VERSION "dbc-export 1 2026.26.6.5"

NS_ :

BS_:

BU_: BB DAS DI DIF DIR EPAS3P EPASTP ESP IBST PM PMF PMR RCM VCBATT0 VCCC VCFRONT VCLEFT VCRIGHT

BO_ 1427 EPASTP_alertLog: 8 EPASTP
 SG_ EPASTP_alertID M : 0|9@1+ (1,0) [0|511] "" Vector__XXX
 SG_ EPASTP_alertState : 15|1@1+ (1,0) [0|1] "" Vector__XXX
 SG_ EPASTP_a001_debugInfo m1 : 16|48@1+ (1,0) [0|281474976710655] "" Vector__XXX
 SG_ EPASTP_a002_debugInfo m2 : 16|48@1+ (1,0) [0|281474976710655] "" Vector__XXX
 SG_ EPASTP_a003_debugInfo m3 : 16|48@1+ (1,0) [0|281474976710655] "" Vector__XXX
 SG_ EPASTP_a004_debugInfo m4 : 16|48@1+ (1,0) [0|281474976710655] "" Vector__XXX
 SG_ EPASTP_a005_debugInfo m5 : 16|48@1+ (1,0) [0|281474976710655] "" Vector__XXX
 SG_ EPASTP_a006_debugInfo m6 : 16|48@1+ (1,0) [0|281474976710655] "" Vector__XXX
 SG_ EPASTP_a007_debugInfo m7 : 16|48@1+ (1,0) [0|281474976710655] "" Vector__XXX
 SG_ EPASTP_a009_debugInfo m9 : 16|48@1+ (1,0) [0|281474976710655] "" Vector__XXX
 SG_ EPASTP_a010_debugInfo m10 : 16|48@1+ (1,0) [0|281474976710655] "" Vector__XXX
 SG_ EPASTP_a011_debugInfo m11 : 16|48@1+ (1,0) [0|281474976710655] "" Vector__XXX
 SG_ EPASTP_a012_debugInfo m12 : 16|48@1+ (1,0) [0|281474976710655] "" Vector__XXX
 SG_ EPASTP_a013_debugInfo m13 : 16|48@1+ (1,0) [0|281474976710655] "" Vector__XXX
 SG_ EPASTP_a014_debugInfo m14 : 16|48@1+ (1,0) [0|281474976710655] "" Vector__XXX
 SG_ EPASTP_a015_debugInfo m15 : 16|48@1+ (1,0) [0|281474976710655] "" Vector__XXX
 SG_ EPASTP_a016_debugInfo m16 : 16|48@1+ (1,0) [0|281474976710655] "" Vector__XXX
 SG_ EPASTP_a017_debugInfo m17 : 16|48@1+ (1,0) [0|281474976710655] "" Vector__XXX
 SG_ EPASTP_a018_debugInfo m18 : 16|48@1+ (1,0) [0|281474976710655] "" Vector__XXX
 SG_ EPASTP_a019_debugInfo m19 : 16|48@1+ (1,0) [0|281474976710655] "" Vector__XXX
 SG_ EPASTP_a020_debugInfo m20 : 16|48@1+ (1,0) [0|281474976710655] "" Vector__XXX
 SG_ EPASTP_a021_debugInfo m21 : 16|48@1+ (1,0) [0|281474976710655] "" Vector__XXX
 SG_ EPASTP_a022_debugInfo m22 : 16|48@1+ (1,0) [0|281474976710655] "" Vector__XXX
 SG_ EPASTP_a023_debugInfo m23 : 16|48@1+ (1,0) [0|281474976710655] "" Vector__XXX
 SG_ EPASTP_a024_debugInfo m24 : 16|48@1+ (1,0) [0|281474976710655] "" Vector__XXX
 SG_ EPASTP_a025_debugInfo m25 : 16|48@1+ (1,0) [0|281474976710655] "" Vector__XXX
 SG_ EPASTP_a026_debugInfo m26 : 16|48@1+ (1,0) [0|281474976710655] "" Vector__XXX
 SG_ EPASTP_a027_debugInfo m27 : 16|48@1+ (1,0) [0|281474976710655] "" Vector__XXX
 SG_ EPASTP_a028_debugInfo m28 : 16|48@1+ (1,0) [0|281474976710655] "" Vector__XXX
 SG_ EPASTP_a029_debugInfo m29 : 16|48@1+ (1,0) [0|281474976710655] "" Vector__XXX
 SG_ EPASTP_a030_debugInfo m30 : 16|48@1+ (1,0) [0|281474976710655] "" Vector__XXX
 SG_ EPASTP_a031_debugInfo m31 : 16|48@1+ (1,0) [0|281474976710655] "" Vector__XXX
 SG_ EPASTP_a032_debugInfo m32 : 16|48@1+ (1,0) [0|281474976710655] "" Vector__XXX
 SG_ EPASTP_a033_debugInfo m33 : 16|48@1+ (1,0) [0|281474976710655] "" Vector__XXX
 SG_ EPASTP_a034_debugInfo m34 : 16|48@1+ (1,0) [0|281474976710655] "" Vector__XXX
 SG_ EPASTP_a035_debugInfo m35 : 16|48@1+ (1,0) [0|281474976710655] "" Vector__XXX
 SG_ EPASTP_a036_debugInfo m36 : 16|48@1+ (1,0) [0|281474976710655] "" Vector__XXX
 SG_ EPASTP_a037_debugInfo m37 : 16|48@1+ (1,0) [0|281474976710655] "" Vector__XXX
 SG_ EPASTP_a038_debugInfo m38 : 16|48@1+ (1,0) [0|281474976710655] "" Vector__XXX
 SG_ EPASTP_a039_debugInfo m39 : 16|48@1+ (1,0) [0|281474976710655] "" Vector__XXX
 SG_ EPASTP_a040_debugInfo m40 : 16|48@1+ (1,0) [0|281474976710655] "" Vector__XXX
 SG_ EPASTP_a041_debugInfo m41 : 16|48@1+ (1,0) [0|281474976710655] "" Vector__XXX
 SG_ EPASTP_a042_debugInfo m42 : 16|48@1+ (1,0) [0|281474976710655] "" Vector__XXX
 SG_ EPASTP_a043_debugInfo m43 : 16|48@1+ (1,0) [0|281474976710655] "" Vector__XXX
 SG_ EPASTP_a044_debugInfo m44 : 16|48@1+ (1,0) [0|281474976710655] "" Vector__XXX
 SG_ EPASTP_a045_debugInfo m45 : 16|48@1+ (1,0) [0|281474976710655] "" Vector__XXX
 SG_ EPASTP_a046_debugInfo m46 : 16|48@1+ (1,0) [0|281474976710655] "" Vector__XXX
 SG_ EPASTP_a047_debugInfo m47 : 16|48@1+ (1,0) [0|281474976710655] "" Vector__XXX
 SG_ EPASTP_a048_debugInfo m48 : 16|48@1+ (1,0) [0|281474976710655] "" Vector__XXX
 SG_ EPASTP_a049_debugInfo m49 : 16|48@1+ (1,0) [0|281474976710655] "" Vector__XXX
 SG_ EPASTP_a050_debugInfo m50 : 16|48@1+ (1,0) [0|281474976710655] "" Vector__XXX
 SG_ EPASTP_a051_debugInfo m51 : 16|48@1+ (1,0) [0|281474976710655] "" Vector__XXX
 SG_ EPASTP_a052_debugInfo m52 : 16|48@1+ (1,0) [0|281474976710655] "" Vector__XXX
 SG_ EPASTP_a053_debugInfo m53 : 16|48@1+ (1,0) [0|281474976710655] "" Vector__XXX
 SG_ EPASTP_a054_debugInfo m54 : 16|48@1+ (1,0) [0|281474976710655] "" Vector__XXX
 SG_ EPASTP_a055_debugInfo m55 : 16|48@1+ (1,0) [0|281474976710655] "" Vector__XXX
 SG_ EPASTP_a056_debugInfo m56 : 16|48@1+ (1,0) [0|281474976710655] "" Vector__XXX
 SG_ EPASTP_a057_debugInfo m57 : 16|48@1+ (1,0) [0|281474976710655] "" Vector__XXX
 SG_ EPASTP_a058_debugInfo m58 : 16|48@1+ (1,0) [0|281474976710655] "" Vector__XXX
 SG_ EPASTP_a059_debugInfo m59 : 16|48@1+ (1,0) [0|281474976710655] "" Vector__XXX
 SG_ EPASTP_a060_debugInfo m60 : 16|48@1+ (1,0) [0|281474976710655] "" Vector__XXX
 SG_ EPASTP_a061_debugInfo m61 : 16|48@1+ (1,0) [0|281474976710655] "" Vector__XXX
 SG_ EPASTP_a062_debugInfo m62 : 16|48@1+ (1,0) [0|281474976710655] "" Vector__XXX
 SG_ EPASTP_a063_debugInfo m63 : 16|48@1+ (1,0) [0|281474976710655] "" Vector__XXX
 SG_ EPASTP_a064_debugInfo m64 : 16|48@1+ (1,0) [0|281474976710655] "" Vector__XXX
 SG_ EPASTP_a065_debugInfo m65 : 16|48@1+ (1,0) [0|281474976710655] "" Vector__XXX
 SG_ EPASTP_a066_debugInfo m66 : 16|48@1+ (1,0) [0|281474976710655] "" Vector__XXX
 SG_ EPASTP_a067_debugInfo m67 : 16|48@1+ (1,0) [0|281474976710655] "" Vector__XXX
 SG_ EPASTP_a068_debugInfo m68 : 16|48@1+ (1,0) [0|281474976710655] "" Vector__XXX
 SG_ EPASTP_a069_debugInfo m69 : 16|48@1+ (1,0) [0|281474976710655] "" Vector__XXX
 SG_ EPASTP_a070_debugInfo m70 : 16|48@1+ (1,0) [0|281474976710655] "" Vector__XXX
 SG_ EPASTP_a071_debugInfo m71 : 16|48@1+ (1,0) [0|281474976710655] "" Vector__XXX
 SG_ EPASTP_a072_debugInfo m72 : 16|48@1+ (1,0) [0|281474976710655] "" Vector__XXX
 SG_ EPASTP_a073_debugInfo m73 : 16|48@1+ (1,0) [0|281474976710655] "" Vector__XXX
 SG_ EPASTP_a074_debugInfo m74 : 16|48@1+ (1,0) [0|281474976710655] "" Vector__XXX
 SG_ EPASTP_a075_debugInfo m75 : 16|48@1+ (1,0) [0|281474976710655] "" Vector__XXX
 SG_ EPASTP_a076_debugInfo m76 : 16|48@1+ (1,0) [0|281474976710655] "" Vector__XXX
 SG_ EPASTP_a077_debugInfo m77 : 16|48@1+ (1,0) [0|281474976710655] "" Vector__XXX
 SG_ EPASTP_a078_debugInfo m78 : 16|48@1+ (1,0) [0|281474976710655] "" Vector__XXX
 SG_ EPASTP_a079_debugInfo m79 : 16|48@1+ (1,0) [0|281474976710655] "" Vector__XXX
 SG_ EPASTP_a080_debugInfo m80 : 16|48@1+ (1,0) [0|281474976710655] "" Vector__XXX
 SG_ EPASTP_a081_debugInfo m81 : 16|48@1+ (1,0) [0|281474976710655] "" Vector__XXX
 SG_ EPASTP_a082_debugInfo m82 : 16|48@1+ (1,0) [0|281474976710655] "" Vector__XXX
 SG_ EPASTP_a083_debugInfo m83 : 16|48@1+ (1,0) [0|281474976710655] "" Vector__XXX
 SG_ EPASTP_a084_debugInfo m84 : 16|48@1+ (1,0) [0|281474976710655] "" Vector__XXX
 SG_ EPASTP_a085_debugInfo m85 : 16|48@1+ (1,0) [0|281474976710655] "" Vector__XXX
 SG_ EPASTP_a086_debugInfo m86 : 16|48@1+ (1,0) [0|281474976710655] "" Vector__XXX
 SG_ EPASTP_a087_debugInfo m87 : 16|48@1+ (1,0) [0|281474976710655] "" Vector__XXX
 SG_ EPASTP_a088_debugInfo m88 : 16|48@1+ (1,0) [0|281474976710655] "" Vector__XXX
 SG_ EPASTP_a089_debugInfo m89 : 16|48@1+ (1,0) [0|281474976710655] "" Vector__XXX
 SG_ EPASTP_a090_debugInfo m90 : 16|48@1+ (1,0) [0|281474976710655] "" Vector__XXX
 SG_ EPASTP_a091_debugInfo m91 : 16|48@1+ (1,0) [0|281474976710655] "" Vector__XXX
 SG_ EPASTP_a092_debugInfo m92 : 16|48@1+ (1,0) [0|281474976710655] "" Vector__XXX
 SG_ EPASTP_a093_debugInfo m93 : 16|48@1+ (1,0) [0|281474976710655] "" Vector__XXX
 SG_ EPASTP_a094_debugInfo m94 : 16|48@1+ (1,0) [0|281474976710655] "" Vector__XXX
 SG_ EPASTP_a095_debugInfo m95 : 16|48@1+ (1,0) [0|281474976710655] "" Vector__XXX
 SG_ EPASTP_a096_debugInfo m96 : 16|48@1+ (1,0) [0|281474976710655] "" Vector__XXX
 SG_ EPASTP_a097_debugInfo m97 : 16|48@1+ (1,0) [0|281474976710655] "" Vector__XXX
 SG_ EPASTP_a098_debugInfo m98 : 16|48@1+ (1,0) [0|281474976710655] "" Vector__XXX
 SG_ EPASTP_a099_debugInfo m99 : 16|48@1+ (1,0) [0|281474976710655] "" Vector__XXX
 SG_ EPASTP_a100_debugInfo m100 : 16|48@1+ (1,0) [0|281474976710655] "" Vector__XXX
 SG_ EPASTP_a101_debugInfo m101 : 16|48@1+ (1,0) [0|281474976710655] "" Vector__XXX
 SG_ EPASTP_a102_debugInfo m102 : 16|48@1+ (1,0) [0|281474976710655] "" Vector__XXX
 SG_ EPASTP_a103_debugInfo m103 : 16|48@1+ (1,0) [0|281474976710655] "" Vector__XXX
 SG_ EPASTP_a104_debugInfo m104 : 16|48@1+ (1,0) [0|281474976710655] "" Vector__XXX
 SG_ EPASTP_a105_debugInfo m105 : 16|48@1+ (1,0) [0|281474976710655] "" Vector__XXX
 SG_ EPASTP_a106_debugInfo m106 : 16|48@1+ (1,0) [0|281474976710655] "" Vector__XXX
 SG_ EPASTP_a107_debugInfo m107 : 16|48@1+ (1,0) [0|281474976710655] "" Vector__XXX
 SG_ EPASTP_a108_debugInfo m108 : 16|48@1+ (1,0) [0|281474976710655] "" Vector__XXX
 SG_ EPASTP_a109_debugInfo m109 : 16|48@1+ (1,0) [0|281474976710655] "" Vector__XXX
 SG_ EPASTP_a110_debugInfo m110 : 16|48@1+ (1,0) [0|281474976710655] "" Vector__XXX
 SG_ EPASTP_a111_debugInfo m111 : 16|48@1+ (1,0) [0|281474976710655] "" Vector__XXX
 SG_ EPASTP_a112_debugInfo m112 : 16|48@1+ (1,0) [0|281474976710655] "" Vector__XXX
 SG_ EPASTP_a113_debugInfo m113 : 16|48@1+ (1,0) [0|281474976710655] "" Vector__XXX
 SG_ EPASTP_a114_debugInfo m114 : 16|48@1+ (1,0) [0|281474976710655] "" Vector__XXX
 SG_ EPASTP_a115_debugInfo m115 : 16|48@1+ (1,0) [0|281474976710655] "" Vector__XXX
 SG_ EPASTP_a116_debugInfo m116 : 16|48@1+ (1,0) [0|281474976710655] "" Vector__XXX
 SG_ EPASTP_a117_debugInfo m117 : 16|48@1+ (1,0) [0|281474976710655] "" Vector__XXX
 SG_ EPASTP_a118_debugInfo m118 : 16|48@1+ (1,0) [0|281474976710655] "" Vector__XXX
 SG_ EPASTP_a119_debugInfo m119 : 16|48@1+ (1,0) [0|281474976710655] "" Vector__XXX
 SG_ EPASTP_a120_debugInfo m120 : 16|48@1+ (1,0) [0|281474976710655] "" Vector__XXX
 SG_ EPASTP_a121_debugInfo m121 : 16|48@1+ (1,0) [0|281474976710655] "" Vector__XXX
 SG_ EPASTP_a122_debugInfo m122 : 16|48@1+ (1,0) [0|281474976710655] "" Vector__XXX
 SG_ EPASTP_a123_debugInfo m123 : 16|48@1+ (1,0) [0|281474976710655] "" Vector__XXX
 SG_ EPASTP_a124_debugInfo m124 : 16|48@1+ (1,0) [0|281474976710655] "" Vector__XXX
 SG_ EPASTP_a125_debugInfo m125 : 16|48@1+ (1,0) [0|281474976710655] "" Vector__XXX
 SG_ EPASTP_a126_debugInfo m126 : 16|48@1+ (1,0) [0|281474976710655] "" Vector__XXX
 SG_ EPASTP_a127_debugInfo m127 : 16|48@1+ (1,0) [0|281474976710655] "" Vector__XXX
 SG_ EPASTP_a128_debugInfo m128 : 16|48@1+ (1,0) [0|281474976710655] "" Vector__XXX
 SG_ EPASTP_a129_debugInfo m129 : 16|48@1+ (1,0) [0|281474976710655] "" Vector__XXX
 SG_ EPASTP_a130_debugInfo m130 : 16|48@1+ (1,0) [0|281474976710655] "" Vector__XXX
 SG_ EPASTP_a131_debugInfo m131 : 16|48@1+ (1,0) [0|281474976710655] "" Vector__XXX
 SG_ EPASTP_a132_debugInfo m132 : 16|48@1+ (1,0) [0|281474976710655] "" Vector__XXX
 SG_ EPASTP_a133_debugInfo m133 : 16|48@1+ (1,0) [0|281474976710655] "" Vector__XXX
 SG_ EPASTP_a134_debugInfo m134 : 16|48@1+ (1,0) [0|281474976710655] "" Vector__XXX
 SG_ EPASTP_a135_debugInfo m135 : 16|48@1+ (1,0) [0|281474976710655] "" Vector__XXX
 SG_ EPASTP_a136_debugInfo m136 : 16|48@1+ (1,0) [0|281474976710655] "" Vector__XXX
 SG_ EPASTP_a137_debugInfo m137 : 16|48@1+ (1,0) [0|281474976710655] "" Vector__XXX
 SG_ EPASTP_a138_debugInfo m138 : 16|48@1+ (1,0) [0|281474976710655] "" Vector__XXX
 SG_ EPASTP_a139_debugInfo m139 : 16|48@1+ (1,0) [0|281474976710655] "" Vector__XXX
 SG_ EPASTP_a140_debugInfo m140 : 16|48@1+ (1,0) [0|281474976710655] "" Vector__XXX
 SG_ EPASTP_a141_debugInfo m141 : 16|48@1+ (1,0) [0|281474976710655] "" Vector__XXX
 SG_ EPASTP_a142_debugInfo m142 : 16|48@1+ (1,0) [0|281474976710655] "" Vector__XXX
 SG_ EPASTP_a143_debugInfo m143 : 16|48@1+ (1,0) [0|281474976710655] "" Vector__XXX
 SG_ EPASTP_a144_debugInfo m144 : 16|48@1+ (1,0) [0|281474976710655] "" Vector__XXX
 SG_ EPASTP_a145_debugInfo m145 : 16|48@1+ (1,0) [0|281474976710655] "" Vector__XXX
 SG_ EPASTP_a146_debugInfo m146 : 16|48@1+ (1,0) [0|281474976710655] "" Vector__XXX
 SG_ EPASTP_a147_debugInfo m147 : 16|48@1+ (1,0) [0|281474976710655] "" Vector__XXX
 SG_ EPASTP_a148_debugInfo m148 : 16|48@1+ (1,0) [0|281474976710655] "" Vector__XXX
 SG_ EPASTP_a149_debugInfo m149 : 16|48@1+ (1,0) [0|281474976710655] "" Vector__XXX
 SG_ EPASTP_a150_debugInfo m150 : 16|48@1+ (1,0) [0|281474976710655] "" Vector__XXX
 SG_ EPASTP_a152_debugInfo m152 : 16|48@1+ (1,0) [0|281474976710655] "" Vector__XXX
 SG_ EPASTP_a153_debugInfo m153 : 16|48@1+ (1,0) [0|281474976710655] "" Vector__XXX
 SG_ EPASTP_a154_debugInfo m154 : 16|48@1+ (1,0) [0|281474976710655] "" Vector__XXX
 SG_ EPASTP_a155_debugInfo m155 : 16|48@1+ (1,0) [0|281474976710655] "" Vector__XXX
 SG_ EPASTP_a156_debugInfo m156 : 16|48@1+ (1,0) [0|281474976710655] "" Vector__XXX
 SG_ EPASTP_a157_debugInfo m157 : 16|48@1+ (1,0) [0|281474976710655] "" Vector__XXX
 SG_ EPASTP_a158_debugInfo m158 : 16|48@1+ (1,0) [0|281474976710655] "" Vector__XXX
 SG_ EPASTP_a159_debugInfo m159 : 16|48@1+ (1,0) [0|281474976710655] "" Vector__XXX
 SG_ EPASTP_a160_debugInfo m160 : 16|48@1+ (1,0) [0|281474976710655] "" Vector__XXX
 SG_ EPASTP_a161_debugInfo m161 : 16|48@1+ (1,0) [0|281474976710655] "" Vector__XXX
 SG_ EPASTP_a162_debugInfo m162 : 16|48@1+ (1,0) [0|281474976710655] "" Vector__XXX
 SG_ EPASTP_a163_debugInfo m163 : 16|48@1+ (1,0) [0|281474976710655] "" Vector__XXX
 SG_ EPASTP_a164_debugInfo m164 : 16|48@1+ (1,0) [0|281474976710655] "" Vector__XXX
 SG_ EPASTP_a165_debugInfo m165 : 16|48@1+ (1,0) [0|281474976710655] "" Vector__XXX
 SG_ EPASTP_a166_debugInfo m166 : 16|48@1+ (1,0) [0|281474976710655] "" Vector__XXX
 SG_ EPASTP_a167_debugInfo m167 : 16|48@1+ (1,0) [0|281474976710655] "" Vector__XXX
 SG_ EPASTP_a168_debugInfo m168 : 16|48@1+ (1,0) [0|281474976710655] "" Vector__XXX
 SG_ EPASTP_a169_debugInfo m169 : 16|48@1+ (1,0) [0|281474976710655] "" Vector__XXX
 SG_ EPASTP_a170_debugInfo m170 : 16|48@1+ (1,0) [0|281474976710655] "" Vector__XXX
 SG_ EPASTP_a171_debugInfo m171 : 16|48@1+ (1,0) [0|281474976710655] "" Vector__XXX
 SG_ EPASTP_a172_debugInfo m172 : 16|48@1+ (1,0) [0|281474976710655] "" Vector__XXX
 SG_ EPASTP_a173_debugInfo m173 : 16|48@1+ (1,0) [0|281474976710655] "" Vector__XXX
 SG_ EPASTP_a174_debugInfo m174 : 16|48@1+ (1,0) [0|281474976710655] "" Vector__XXX
 SG_ EPASTP_a175_debugInfo m175 : 16|48@1+ (1,0) [0|281474976710655] "" Vector__XXX
 SG_ EPASTP_a176_debugInfo m176 : 16|48@1+ (1,0) [0|281474976710655] "" Vector__XXX
 SG_ EPASTP_a177_debugInfo m177 : 16|48@1+ (1,0) [0|281474976710655] "" Vector__XXX
 SG_ EPASTP_a178_debugInfo m178 : 16|48@1+ (1,0) [0|281474976710655] "" Vector__XXX
 SG_ EPASTP_a179_debugInfo m179 : 16|48@1+ (1,0) [0|281474976710655] "" Vector__XXX
 SG_ EPASTP_a180_debugInfo m180 : 16|48@1+ (1,0) [0|281474976710655] "" Vector__XXX
 SG_ EPASTP_a181_debugInfo m181 : 16|48@1+ (1,0) [0|281474976710655] "" Vector__XXX
 SG_ EPASTP_a182_debugInfo m182 : 16|48@1+ (1,0) [0|281474976710655] "" Vector__XXX
 SG_ EPASTP_a183_debugInfo m183 : 16|48@1+ (1,0) [0|281474976710655] "" Vector__XXX
 SG_ EPASTP_a184_debugInfo m184 : 16|48@1+ (1,0) [0|281474976710655] "" Vector__XXX
 SG_ EPASTP_a185_debugInfo m185 : 16|48@1+ (1,0) [0|281474976710655] "" Vector__XXX
 SG_ EPASTP_a186_debugInfo m186 : 16|48@1+ (1,0) [0|281474976710655] "" Vector__XXX
 SG_ EPASTP_a188_debugInfo m188 : 16|48@1+ (1,0) [0|281474976710655] "" Vector__XXX
 SG_ EPASTP_a189_debugInfo m189 : 16|48@1+ (1,0) [0|281474976710655] "" Vector__XXX
 SG_ EPASTP_a190_debugInfo m190 : 16|48@1+ (1,0) [0|281474976710655] "" Vector__XXX
 SG_ EPASTP_a191_debugInfo m191 : 16|48@1+ (1,0) [0|281474976710655] "" Vector__XXX
 SG_ EPASTP_a192_debugInfo m192 : 16|48@1+ (1,0) [0|281474976710655] "" Vector__XXX
 SG_ EPASTP_a193_debugInfo m193 : 16|48@1+ (1,0) [0|281474976710655] "" Vector__XXX
 SG_ EPASTP_a194_debugInfo m194 : 16|48@1+ (1,0) [0|281474976710655] "" Vector__XXX
 SG_ EPASTP_a195_debugInfo m195 : 16|48@1+ (1,0) [0|281474976710655] "" Vector__XXX
 SG_ EPASTP_a196_debugInfo m196 : 16|48@1+ (1,0) [0|281474976710655] "" Vector__XXX
 SG_ EPASTP_a197_debugInfo m197 : 16|48@1+ (1,0) [0|281474976710655] "" Vector__XXX
 SG_ EPASTP_a198_debugInfo m198 : 16|48@1+ (1,0) [0|281474976710655] "" Vector__XXX
 SG_ EPASTP_a199_debugInfo m199 : 16|48@1+ (1,0) [0|281474976710655] "" Vector__XXX
 SG_ EPASTP_a200_debugInfo m200 : 16|48@1+ (1,0) [0|281474976710655] "" Vector__XXX
 SG_ EPASTP_a201_debugInfo m201 : 16|48@1+ (1,0) [0|281474976710655] "" Vector__XXX
 SG_ EPASTP_a202_debugInfo m202 : 16|48@1+ (1,0) [0|281474976710655] "" Vector__XXX
 SG_ EPASTP_a203_debugInfo m203 : 16|48@1+ (1,0) [0|281474976710655] "" Vector__XXX
 SG_ EPASTP_a204_debugInfo m204 : 16|48@1+ (1,0) [0|281474976710655] "" Vector__XXX
 SG_ EPASTP_a205_debugInfo m205 : 16|48@1+ (1,0) [0|281474976710655] "" Vector__XXX
 SG_ EPASTP_a206_debugInfo m206 : 16|48@1+ (1,0) [0|281474976710655] "" Vector__XXX
 SG_ EPASTP_a207_debugInfo m207 : 16|48@1+ (1,0) [0|281474976710655] "" Vector__XXX
 SG_ EPASTP_a208_debugInfo m208 : 16|48@1+ (1,0) [0|281474976710655] "" Vector__XXX
 SG_ EPASTP_a209_debugInfo m209 : 16|48@1+ (1,0) [0|281474976710655] "" Vector__XXX
 SG_ EPASTP_a210_debugInfo m210 : 16|48@1+ (1,0) [0|281474976710655] "" Vector__XXX
 SG_ EPASTP_a211_debugInfo m211 : 16|48@1+ (1,0) [0|281474976710655] "" Vector__XXX
 SG_ EPASTP_a212_debugInfo m212 : 16|48@1+ (1,0) [0|281474976710655] "" Vector__XXX
 SG_ EPASTP_a213_debugInfo m213 : 16|48@1+ (1,0) [0|281474976710655] "" Vector__XXX
 SG_ EPASTP_a214_debugInfo m214 : 16|48@1+ (1,0) [0|281474976710655] "" Vector__XXX
 SG_ EPASTP_a215_debugInfo m215 : 16|48@1+ (1,0) [0|281474976710655] "" Vector__XXX
 SG_ EPASTP_a216_debugInfo m216 : 16|48@1+ (1,0) [0|281474976710655] "" Vector__XXX
 SG_ EPASTP_a217_debugInfo m217 : 16|48@1+ (1,0) [0|281474976710655] "" Vector__XXX
 SG_ EPASTP_a218_debugInfo m218 : 16|48@1+ (1,0) [0|281474976710655] "" Vector__XXX
 SG_ EPASTP_a219_debugInfo m219 : 16|48@1+ (1,0) [0|281474976710655] "" Vector__XXX
 SG_ EPASTP_a221_debugInfo m221 : 16|48@1+ (1,0) [0|281474976710655] "" Vector__XXX
 SG_ EPASTP_a222_debugInfo m222 : 16|48@1+ (1,0) [0|281474976710655] "" Vector__XXX
 SG_ EPASTP_a223_debugInfo m223 : 16|48@1+ (1,0) [0|281474976710655] "" Vector__XXX
 SG_ EPASTP_a224_debugInfo m224 : 16|48@1+ (1,0) [0|281474976710655] "" Vector__XXX
 SG_ EPASTP_a225_debugInfo m225 : 16|48@1+ (1,0) [0|281474976710655] "" Vector__XXX
 SG_ EPASTP_a226_debugInfo m226 : 16|48@1+ (1,0) [0|281474976710655] "" Vector__XXX
 SG_ EPASTP_a227_debugInfo m227 : 16|48@1+ (1,0) [0|281474976710655] "" Vector__XXX
 SG_ EPASTP_a228_debugInfo m228 : 16|48@1+ (1,0) [0|281474976710655] "" Vector__XXX
 SG_ EPASTP_a229_debugInfo m229 : 16|48@1+ (1,0) [0|281474976710655] "" Vector__XXX
 SG_ EPASTP_a230_debugInfo m230 : 16|48@1+ (1,0) [0|281474976710655] "" Vector__XXX
 SG_ EPASTP_a231_debugInfo m231 : 16|48@1+ (1,0) [0|281474976710655] "" Vector__XXX
 SG_ EPASTP_a232_debugInfo m232 : 16|48@1+ (1,0) [0|281474976710655] "" Vector__XXX
 SG_ EPASTP_a233_debugInfo m233 : 16|48@1+ (1,0) [0|281474976710655] "" Vector__XXX
 SG_ EPASTP_a234_debugInfo m234 : 16|48@1+ (1,0) [0|281474976710655] "" Vector__XXX
 SG_ EPASTP_a235_debugInfo m235 : 16|48@1+ (1,0) [0|281474976710655] "" Vector__XXX
 SG_ EPASTP_a236_debugInfo m236 : 16|48@1+ (1,0) [0|281474976710655] "" Vector__XXX
 SG_ EPASTP_a237_debugInfo m237 : 16|48@1+ (1,0) [0|281474976710655] "" Vector__XXX
 SG_ EPASTP_a238_debugInfo m238 : 16|48@1+ (1,0) [0|281474976710655] "" Vector__XXX
 SG_ EPASTP_a239_debugInfo m239 : 16|48@1+ (1,0) [0|281474976710655] "" Vector__XXX
 SG_ EPASTP_a240_debugInfo m240 : 16|48@1+ (1,0) [0|281474976710655] "" Vector__XXX
 SG_ EPASTP_a241_debugInfo m241 : 16|48@1+ (1,0) [0|281474976710655] "" Vector__XXX
 SG_ EPASTP_a242_debugInfo m242 : 16|48@1+ (1,0) [0|281474976710655] "" Vector__XXX
 SG_ EPASTP_a243_debugInfo m243 : 16|48@1+ (1,0) [0|281474976710655] "" Vector__XXX
 SG_ EPASTP_a244_debugInfo m244 : 16|48@1+ (1,0) [0|281474976710655] "" Vector__XXX
 SG_ EPASTP_a245_debugInfo m245 : 16|48@1+ (1,0) [0|281474976710655] "" Vector__XXX
 SG_ EPASTP_a246_debugInfo m246 : 16|48@1+ (1,0) [0|281474976710655] "" Vector__XXX
 SG_ EPASTP_a247_debugInfo m247 : 16|48@1+ (1,0) [0|281474976710655] "" Vector__XXX
 SG_ EPASTP_a248_debugInfo m248 : 16|48@1+ (1,0) [0|281474976710655] "" Vector__XXX
 SG_ EPASTP_a249_debugInfo m249 : 16|48@1+ (1,0) [0|281474976710655] "" Vector__XXX
 SG_ EPASTP_a250_debugInfo m250 : 16|48@1+ (1,0) [0|281474976710655] "" Vector__XXX
 SG_ EPASTP_a252_debugInfo m252 : 16|48@1+ (1,0) [0|281474976710655] "" Vector__XXX
 SG_ EPASTP_a253_debugInfo m253 : 16|48@1+ (1,0) [0|281474976710655] "" Vector__XXX
 SG_ EPASTP_a254_debugInfo m254 : 16|48@1+ (1,0) [0|281474976710655] "" Vector__XXX
 SG_ EPASTP_a255_debugInfo m255 : 16|48@1+ (1,0) [0|281474976710655] "" Vector__XXX
 SG_ EPASTP_a256_debugInfo m256 : 16|48@1+ (1,0) [0|281474976710655] "" Vector__XXX
 SG_ EPASTP_a257_debugInfo m257 : 16|48@1+ (1,0) [0|281474976710655] "" Vector__XXX
 SG_ EPASTP_a258_debugInfo m258 : 16|48@1+ (1,0) [0|281474976710655] "" Vector__XXX
 SG_ EPASTP_a259_debugInfo m259 : 16|48@1+ (1,0) [0|281474976710655] "" Vector__XXX
 SG_ EPASTP_a260_debugInfo m260 : 16|48@1+ (1,0) [0|281474976710655] "" Vector__XXX
 SG_ EPASTP_a261_debugInfo m261 : 16|48@1+ (1,0) [0|281474976710655] "" Vector__XXX
 SG_ EPASTP_a262_debugInfo m262 : 16|48@1+ (1,0) [0|281474976710655] "" Vector__XXX
 SG_ EPASTP_a263_debugInfo m263 : 16|48@1+ (1,0) [0|281474976710655] "" Vector__XXX
 SG_ EPASTP_a264_degradedECU m264 : 16|8@1+ (1,0) [0|255] "" Vector__XXX
 SG_ EPASTP_a264_vehicleSpeed m264 : 24|16@1+ (0.1,0) [0|6553.5] "kph" Vector__XXX
 SG_ EPASTP_a264_powerRatio m264 : 40|8@1+ (1,0) [0|255] "percent" Vector__XXX
 SG_ EPASTP_a264_ownSideDegradationRe m264 : 48|8@1+ (1,0) [0|255] "" Vector__XXX
 SG_ EPASTP_a264_otherSideDegradation m264 : 56|8@1+ (1,0) [0|255] "" Vector__XXX
 SG_ EPASTP_a265_degradedECU m265 : 16|8@1+ (1,0) [0|255] "" Vector__XXX
 SG_ EPASTP_a265_vehicleSpeed m265 : 24|16@1+ (0.1,0) [0|6553.5] "kph" Vector__XXX
 SG_ EPASTP_a265_rawMcuTemperature m265 : 40|16@1+ (1,-100) [-100|65435] "C" Vector__XXX
 SG_ EPASTP_a265_degradedCurrentLimit m265 : 56|8@1+ (1,0) [0|255] "A" Vector__XXX
 SG_ EPASTP_a266_cdpAssistFactor m266 : 16|8@1+ (1,0) [0|255] "percent" Vector__XXX
 SG_ EPASTP_a266_vehicleSpeed m266 : 24|16@1+ (0.1,0) [0|6553.5] "kph" Vector__XXX
 SG_ EPASTP_a267_vehicleSpeed m267 : 16|16@1+ (0.1,0) [0|6553.5] "kph" Vector__XXX
 SG_ EPASTP_a267_velocityEstimatorSta m267 : 32|8@1+ (1,0) [0|255] "" Vector__XXX
 SG_ EPASTP_a269_vehicleSpeed m269 : 16|16@1+ (0.1,0) [0|6553.5] "kph" Vector__XXX
 SG_ EPASTP_a270_debugInfo m270 : 16|48@1+ (1,0) [0|281474976710655] "" Vector__XXX

BO_ 919 EPASTP_alertMatrix: 8 EPASTP
 SG_ EPASTP_matrixIndex M : 0|4@1+ (1,0) [0|15] "" Vector__XXX
 SG_ EPASTP_a001_adcCalibrationOrInit m0 : 4|1@1+ (1,0) [0|1] "" Vector__XXX
 SG_ EPASTP_a002_adcMuxErr m0 : 5|1@1+ (1,0) [0|1] "" Vector__XXX
 SG_ EPASTP_a003_pspInvalidParamset m0 : 6|1@1+ (1,0) [0|1] "" Vector__XXX
 SG_ EPASTP_a004_scpInputMia m0 : 7|1@1+ (1,0) [0|1] "" Vector__XXX
 SG_ EPASTP_a005_scpUnknownResetSourc m0 : 8|1@1+ (1,0) [0|1] "" Vector__XXX
 SG_ EPASTP_a006_swrhResetByInvalidEr m0 : 9|1@1+ (1,0) [0|1] "" Vector__XXX
 SG_ EPASTP_a007_tsmcCoreTempDiff m0 : 10|1@1+ (1,0) [0|1] "" Vector__XXX
 SG_ EPASTP_a008_psdcPlatformShutdown m0 : 11|1@1+ (1,0) [0|1] "" Vector__XXX
 SG_ EPASTP_a009_mcusscLbistPermanent m0 : 12|1@1+ (1,0) [0|1] "" Vector__XXX
 SG_ EPASTP_a010_svcIncompatibleSwVer m0 : 13|1@1+ (1,0) [0|1] "" Vector__XXX
 SG_ EPASTP_a011_mcusscMonbistErr m0 : 14|1@1+ (1,0) [0|1] "" Vector__XXX
 SG_ EPASTP_a012_mcusscMbistEccErr m0 : 15|1@1+ (1,0) [0|1] "" Vector__XXX
 SG_ EPASTP_a013_mcusscSffMonitoringF m0 : 16|1@1+ (1,0) [0|1] "" Vector__XXX
 SG_ EPASTP_a014_mcusscSffMonitoringM m0 : 17|1@1+ (1,0) [0|1] "" Vector__XXX
 SG_ EPASTP_a015_mcusscCsErrorCheckFa m0 : 18|1@1+ (1,0) [0|1] "" Vector__XXX
 SG_ EPASTP_a016_mcufcCsErrorCheckFai m0 : 19|1@1+ (1,0) [0|1] "" Vector__XXX
 SG_ EPASTP_a017_stmdStmPlausibilityC m0 : 20|1@1+ (1,0) [0|1] "" Vector__XXX
 SG_ EPASTP_a018_exchCsErrorCheck m0 : 21|1@1+ (1,0) [0|1] "" Vector__XXX
 SG_ EPASTP_a019_rsthHwResetInfoCorru m0 : 22|1@1+ (1,0) [0|1] "" Vector__XXX
 SG_ EPASTP_a020_mcusscEolEcuIdIntegr m0 : 23|1@1+ (1,0) [0|1] "" Vector__XXX
 SG_ EPASTP_a021_osehCsErrorCheck m0 : 24|1@1+ (1,0) [0|1] "" Vector__XXX
 SG_ EPASTP_a022_swrhSwResetInfoCorru m0 : 25|1@1+ (1,0) [0|1] "" Vector__XXX
 SG_ EPASTP_a023_btarcCorruptionCheck m0 : 26|1@1+ (1,0) [0|1] "" Vector__XXX
 SG_ EPASTP_a024_srhCsErrorCheckFail m0 : 27|1@1+ (1,0) [0|1] "" Vector__XXX
 SG_ EPASTP_a025_btarcCorruptionCheck m0 : 28|1@1+ (1,0) [0|1] "" Vector__XXX
 SG_ EPASTP_a026_mrccCsErrorCheckFail m0 : 29|1@1+ (1,0) [0|1] "" Vector__XXX
 SG_ EPASTP_a027_mcusscDmuHfErr m0 : 30|1@1+ (1,0) [0|1] "" Vector__XXX
 SG_ EPASTP_a028_smuhNonInitDataCorru m0 : 31|1@1+ (1,0) [0|1] "" Vector__XXX
 SG_ EPASTP_a029_smuhSmuCoreCntErrorT m0 : 32|1@1+ (1,0) [0|1] "" Vector__XXX
 SG_ EPASTP_a030_rsthClockReset m0 : 33|1@1+ (1,0) [0|1] "" Vector__XXX
 SG_ EPASTP_a031_pmsProductionModeFai m0 : 34|1@1+ (1,0) [0|1] "" Vector__XXX
 SG_ EPASTP_a032_eolpEolCheckFailed m0 : 35|1@1+ (1,0) [0|1] "" Vector__XXX
 SG_ EPASTP_a033_icsvcPswVersionMisma m0 : 36|1@1+ (1,0) [0|1] "" Vector__XXX
 SG_ EPASTP_a034_sbchReadbackRegFail m0 : 37|1@1+ (1,0) [0|1] "" Vector__XXX
 SG_ EPASTP_a035_sbchChipIdFail m0 : 38|1@1+ (1,0) [0|1] "" Vector__XXX
 SG_ EPASTP_a036_sbcmSbcBistFailed m0 : 39|1@1+ (1,0) [0|1] "" Vector__XXX
 SG_ EPASTP_a037_epmV5P2Fail m0 : 40|1@1+ (1,0) [0|1] "" Vector__XXX
 SG_ EPASTP_a038_csohCh1CsErrorErrAtR m0 : 41|1@1+ (1,0) [0|1] "" Vector__XXX
 SG_ EPASTP_a039_csohCh2CsErrorErrAtR m0 : 42|1@1+ (1,0) [0|1] "" Vector__XXX
 SG_ EPASTP_a040_swrhLimitedResetRetr m0 : 43|1@1+ (1,0) [0|1] "" Vector__XXX
 SG_ EPASTP_a041_imcmCoreConfiguratio m0 : 44|1@1+ (1,0) [0|1] "" Vector__XXX
 SG_ EPASTP_a042_wdhWdTestFail m0 : 45|1@1+ (1,0) [0|1] "" Vector__XXX
 SG_ EPASTP_a043_sbcmWdStateDisabled m0 : 46|1@1+ (1,0) [0|1] "" Vector__XXX
 SG_ EPASTP_a044_sbcmSbcEepromFail m0 : 47|1@1+ (1,0) [0|1] "" Vector__XXX
 SG_ EPASTP_a045_psumSbcBandgapVoltEr m0 : 48|1@1+ (1,0) [0|1] "" Vector__XXX
 SG_ EPASTP_a046_mcusscOscillatorNotR m0 : 49|1@1+ (1,0) [0|1] "" Vector__XXX
 SG_ EPASTP_a047_epmVregVoltFail m0 : 50|1@1+ (1,0) [0|1] "" Vector__XXX
 SG_ EPASTP_a048_epmVcpVoltFail m0 : 51|1@1+ (1,0) [0|1] "" Vector__XXX
 SG_ EPASTP_a049_epmLgFail m0 : 52|1@1+ (1,0) [0|1] "" Vector__XXX
 SG_ EPASTP_a050_erlErr m0 : 53|1@1+ (1,0) [0|1] "" Vector__XXX
 SG_ EPASTP_a051_ermMessageErr m0 : 54|1@1+ (1,0) [0|1] "" Vector__XXX
 SG_ EPASTP_a052_ermSdcInputBufferOve m0 : 55|1@1+ (1,0) [0|1] "" Vector__XXX
 SG_ EPASTP_a053_adcUnexpectedNumOfDa m0 : 56|1@1+ (1,0) [0|1] "" Vector__XXX
 SG_ EPASTP_a054_adcUnexpectedData m0 : 57|1@1+ (1,0) [0|1] "" Vector__XXX
 SG_ EPASTP_a055_amExtendedGduTest m0 : 58|1@1+ (1,0) [0|1] "" Vector__XXX
 SG_ EPASTP_a056_amGduConfigCsErrorCh m0 : 59|1@1+ (1,0) [0|1] "" Vector__XXX
 SG_ EPASTP_a057_amGduVds m0 : 60|1@1+ (1,0) [0|1] "" Vector__XXX
 SG_ EPASTP_a058_amIntVgsUndervtgErr m0 : 61|1@1+ (1,0) [0|1] "" Vector__XXX
 SG_ EPASTP_a059_amStartupTestFailed m0 : 62|1@1+ (1,0) [0|1] "" Vector__XXX
 SG_ EPASTP_a060_amGduFail m0 : 63|1@1+ (1,0) [0|1] "" Vector__XXX
 SG_ EPASTP_a061_amIntSerialErr m1 : 4|1@1+ (1,0) [0|1] "" Vector__XXX
 SG_ EPASTP_a062_amPhaseBridgeCheck m1 : 5|1@1+ (1,0) [0|1] "" Vector__XXX
 SG_ EPASTP_a063_amIntRegulatorErr m1 : 6|1@1+ (1,0) [0|1] "" Vector__XXX
 SG_ EPASTP_a064_amBridgeShort m1 : 7|1@1+ (1,0) [0|1] "" Vector__XXX
 SG_ EPASTP_a065_amGduJuncTemp m1 : 8|1@1+ (1,0) [0|1] "" Vector__XXX
 SG_ EPASTP_a066_amVoltQfErr m1 : 9|1@1+ (1,0) [0|1] "" Vector__XXX
 SG_ EPASTP_a067_tspmPowermoduleTempI m1 : 10|1@1+ (1,0) [0|1] "" Vector__XXX
 SG_ EPASTP_a068_rsthCoreRedundancyEr m1 : 11|1@1+ (1,0) [0|1] "" Vector__XXX
 SG_ EPASTP_a069_rsthCoreTempOutOfRan m1 : 12|1@1+ (1,0) [0|1] "" Vector__XXX
 SG_ EPASTP_a070_rsthInternalLowVolt m1 : 13|1@1+ (1,0) [0|1] "" Vector__XXX
 SG_ EPASTP_a071_rsthInternalHighVolt m1 : 14|1@1+ (1,0) [0|1] "" Vector__XXX
 SG_ EPASTP_a072_rsthFlashUncorrEccOr m1 : 15|1@1+ (1,0) [0|1] "" Vector__XXX
 SG_ EPASTP_a073_rsthOtherEdcEcc m1 : 16|1@1+ (1,0) [0|1] "" Vector__XXX
 SG_ EPASTP_a074_rsthUnexpectedAlarm m1 : 17|1@1+ (1,0) [0|1] "" Vector__XXX
 SG_ EPASTP_a075_rsthUnusedOtherModul m1 : 18|1@1+ (1,0) [0|1] "" Vector__XXX
 SG_ EPASTP_a076_exchGeneralException m1 : 19|1@1+ (1,0) [0|1] "" Vector__XXX
 SG_ EPASTP_a077_dmDeadlineViolation m1 : 20|1@1+ (1,0) [0|1] "" Vector__XXX
 SG_ EPASTP_a078_dmDeadlineViolation m1 : 21|1@1+ (1,0) [0|1] "" Vector__XXX
 SG_ EPASTP_a079_gduhComErr m1 : 22|1@1+ (1,0) [0|1] "" Vector__XXX
 SG_ EPASTP_a080_pwmTimerSyncCheck m1 : 23|1@1+ (1,0) [0|1] "" Vector__XXX
 SG_ EPASTP_a081_exchFloatingPointExc m1 : 24|1@1+ (1,0) [0|1] "" Vector__XXX
 SG_ EPASTP_a082_adcTriggerTimeChk m1 : 25|1@1+ (1,0) [0|1] "" Vector__XXX
 SG_ EPASTP_a083_tdaDclinkcapacitorTe m1 : 26|1@1+ (1,0) [0|1] "" Vector__XXX
 SG_ EPASTP_a084_adcTriggerCheck m1 : 27|1@1+ (1,0) [0|1] "" Vector__XXX
 SG_ EPASTP_a085_amGduSwitchOffTestBy m1 : 28|1@1+ (1,0) [0|1] "" Vector__XXX
 SG_ EPASTP_a086_rsthRamUncorrEcc m1 : 29|1@1+ (1,0) [0|1] "" Vector__XXX
 SG_ EPASTP_a087_rsthFlashConfigErr m1 : 30|1@1+ (1,0) [0|1] "" Vector__XXX
 SG_ EPASTP_a088_tedMainboardTempChec m1 : 31|1@1+ (1,0) [0|1] "" Vector__XXX
 SG_ EPASTP_a089_tedRevercebattfetjun m1 : 32|1@1+ (1,0) [0|1] "" Vector__XXX
 SG_ EPASTP_a090_etsmWarning m1 : 33|1@1+ (1,0) [0|1] "" Vector__XXX
 SG_ EPASTP_a091_bvpBattVoltCrossChkF m1 : 34|1@1+ (1,0) [0|1] "" Vector__XXX
 SG_ EPASTP_a092_amGduSwitchOffTestBy m1 : 35|1@1+ (1,0) [0|1] "" Vector__XXX
 SG_ EPASTP_a093_sctpTsuSingleStaticF m1 : 36|1@1+ (1,0) [0|1] "" Vector__XXX
 SG_ EPASTP_a094_sctpTsuMultipleStati m1 : 37|1@1+ (1,0) [0|1] "" Vector__XXX
 SG_ EPASTP_a095_mdModelBasedMotorInt m1 : 38|1@1+ (1,0) [0|1] "" Vector__XXX
 SG_ EPASTP_a096_rppRpsSingleStaticFa m1 : 39|1@1+ (1,0) [0|1] "" Vector__XXX
 SG_ EPASTP_a097_rppRpsMultipleStatic m1 : 40|1@1+ (1,0) [0|1] "" Vector__XXX
 SG_ EPASTP_a098_invErr m1 : 41|1@1+ (1,0) [0|1] "" Vector__XXX
 SG_ EPASTP_a099_mcdTorqueMismatchFau m1 : 42|1@1+ (1,0) [0|1] "" Vector__XXX
 SG_ EPASTP_a100_amVbrgLssFault m1 : 43|1@1+ (1,0) [0|1] "" Vector__XXX
 SG_ EPASTP_a101_sdrvSpcIdMismatch m1 : 44|1@1+ (1,0) [0|1] "" Vector__XXX
 SG_ EPASTP_a102_amPhasecurrentQosErr m1 : 45|1@1+ (1,0) [0|1] "" Vector__XXX
 SG_ EPASTP_a103_exhaUnusedInterruptC m1 : 46|1@1+ (1,0) [0|1] "" Vector__XXX
 SG_ EPASTP_a104_exhaBusMpuException m1 : 47|1@1+ (1,0) [0|1] "" Vector__XXX
 SG_ EPASTP_a105_exhaSriBusErrExcepti m1 : 48|1@1+ (1,0) [0|1] "" Vector__XXX
 SG_ EPASTP_a106_exhaSpbBusErrExcepti m1 : 49|1@1+ (1,0) [0|1] "" Vector__XXX
 SG_ EPASTP_a107_exhaOtherNmiExceptio m1 : 50|1@1+ (1,0) [0|1] "" Vector__XXX
 SG_ EPASTP_a108_exhaInternalProtecti m1 : 51|1@1+ (1,0) [0|1] "" Vector__XXX
 SG_ EPASTP_a109_exhaSysBusOrPeriphEr m1 : 52|1@1+ (1,0) [0|1] "" Vector__XXX
 SG_ EPASTP_a110_amPhaseRelaySwitchOf m1 : 53|1@1+ (1,0) [0|1] "" Vector__XXX
 SG_ EPASTP_a111_amCurrentSensingDisc m1 : 54|1@1+ (1,0) [0|1] "" Vector__XXX
 SG_ EPASTP_a112_rsthSafetyFlipflopEr m1 : 55|1@1+ (1,0) [0|1] "" Vector__XXX
 SG_ EPASTP_a113_rsthUncorrectableEnd m1 : 56|1@1+ (1,0) [0|1] "" Vector__XXX
 SG_ EPASTP_a114_osehOsErr m1 : 57|1@1+ (1,0) [0|1] "" Vector__XXX
 SG_ EPASTP_a115_mcusscLbistSingleFai m1 : 58|1@1+ (1,0) [0|1] "" Vector__XXX
 SG_ EPASTP_a116_mrccStartupRegCsErro m1 : 59|1@1+ (1,0) [0|1] "" Vector__XXX
 SG_ EPASTP_a117_mrccStartupRegCsErro m1 : 60|1@1+ (1,0) [0|1] "" Vector__XXX
 SG_ EPASTP_a118_mcusscFlashCsErrorEr m1 : 61|1@1+ (1,0) [0|1] "" Vector__XXX
 SG_ EPASTP_a119_mcusscFlashEccCritic m1 : 62|1@1+ (1,0) [0|1] "" Vector__XXX
 SG_ EPASTP_a120_mcusscFlashEccLatent m1 : 63|1@1+ (1,0) [0|1] "" Vector__XXX
 SG_ EPASTP_a121_mcusscMbistEccErr m2 : 4|1@1+ (1,0) [0|1] "" Vector__XXX
 SG_ EPASTP_a122_pcpBridgeFetShort m2 : 5|1@1+ (1,0) [0|1] "" Vector__XXX
 SG_ EPASTP_a123_imcmCommErr m2 : 6|1@1+ (1,0) [0|1] "" Vector__XXX
 SG_ EPASTP_a124_mcusscMbistEccTransi m2 : 7|1@1+ (1,0) [0|1] "" Vector__XXX
 SG_ EPASTP_a125_mcusscMbistMiaErr m2 : 8|1@1+ (1,0) [0|1] "" Vector__XXX
 SG_ EPASTP_a126_mcusscMonbistMiaErr m2 : 9|1@1+ (1,0) [0|1] "" Vector__XXX
 SG_ EPASTP_a127_exchAdditionalExcept m2 : 10|1@1+ (1,0) [0|1] "" Vector__XXX
 SG_ EPASTP_a128_exchExceptionStopRes m2 : 11|1@1+ (1,0) [0|1] "" Vector__XXX
 SG_ EPASTP_a129_exchAdditionalExcept m2 : 12|1@1+ (1,0) [0|1] "" Vector__XXX
 SG_ EPASTP_a130_mrccConfigCsErrorErr m2 : 13|1@1+ (1,0) [0|1] "" Vector__XXX
 SG_ EPASTP_a131_exchGuardedResetAfte m2 : 14|1@1+ (1,0) [0|1] "" Vector__XXX
 SG_ EPASTP_a132_mcusscNotSupportedMc m2 : 15|1@1+ (1,0) [0|1] "" Vector__XXX
 SG_ EPASTP_a133_mcusscLbistEcuIdIsNo m2 : 16|1@1+ (1,0) [0|1] "" Vector__XXX
 SG_ EPASTP_a134_osehGuardedResetAfte m2 : 17|1@1+ (1,0) [0|1] "" Vector__XXX
 SG_ EPASTP_a135_tmpsfetjCalculationO m2 : 18|1@1+ (1,0) [0|1] "" Vector__XXX
 SG_ EPASTP_a136_ftElectricalAngleQf m2 : 19|1@1+ (1,0) [0|1] "" Vector__XXX
 SG_ EPASTP_a137_osehErrWithoutImmedi m2 : 20|1@1+ (1,0) [0|1] "" Vector__XXX
 SG_ EPASTP_a138_osehAdditionalErrWit m2 : 21|1@1+ (1,0) [0|1] "" Vector__XXX
 SG_ EPASTP_a139_osehAdditionalOsErr m2 : 22|1@1+ (1,0) [0|1] "" Vector__XXX
 SG_ EPASTP_a140_imcmConfigurationErr m2 : 23|1@1+ (1,0) [0|1] "" Vector__XXX
 SG_ EPASTP_a141_amFetShortTest m2 : 24|1@1+ (1,0) [0|1] "" Vector__XXX
 SG_ EPASTP_a142_tedEmifilterDmcTempC m2 : 25|1@1+ (1,0) [0|1] "" Vector__XXX
 SG_ EPASTP_a143_tedEmifilterCmcTempC m2 : 26|1@1+ (1,0) [0|1] "" Vector__XXX
 SG_ EPASTP_a144_mriCoreRaminitFailed m2 : 27|1@1+ (1,0) [0|1] "" Vector__XXX
 SG_ EPASTP_a145_mriPeripheralRaminit m2 : 28|1@1+ (1,0) [0|1] "" Vector__XXX
 SG_ EPASTP_a146_btarcRcCircuitCheck m2 : 29|1@1+ (1,0) [0|1] "" Vector__XXX
 SG_ EPASTP_a147_amDcLinkShortedFail m2 : 30|1@1+ (1,0) [0|1] "" Vector__XXX
 SG_ EPASTP_a148_mrccExitFromStandbyD m2 : 31|1@1+ (1,0) [0|1] "" Vector__XXX
 SG_ EPASTP_a149_amReversibleEmergenc m2 : 32|1@1+ (1,0) [0|1] "" Vector__XXX
 SG_ EPASTP_a150_amExternalEmergencyO m2 : 33|1@1+ (1,0) [0|1] "" Vector__XXX
 SG_ EPASTP_a151_amPermanentEmergency m2 : 34|1@1+ (1,0) [0|1] "" Vector__XXX
 SG_ EPASTP_a152_exchFlashEccExceptio m2 : 35|1@1+ (1,0) [0|1] "" Vector__XXX
 SG_ EPASTP_a153_sdsmBlockSelectorInv m2 : 36|1@1+ (1,0) [0|1] "" Vector__XXX
 SG_ EPASTP_a154_sdsmCsErrorInvalidPr m2 : 37|1@1+ (1,0) [0|1] "" Vector__XXX
 SG_ EPASTP_a155_sdsmDataInvalidAll m2 : 38|1@1+ (1,0) [0|1] "" Vector__XXX
 SG_ EPASTP_a156_amIntSerialErrSafety m2 : 39|1@1+ (1,0) [0|1] "" Vector__XXX
 SG_ EPASTP_a157_mcudcpInvalidEcuId m2 : 40|1@1+ (1,0) [0|1] "" Vector__XXX
 SG_ EPASTP_a158_amGduFailDuringRecov m2 : 41|1@1+ (1,0) [0|1] "" Vector__XXX
 SG_ EPASTP_a159_exchFlashWordlineTra m2 : 42|1@1+ (1,0) [0|1] "" Vector__XXX
 SG_ EPASTP_a160_rsthCpu1UnexpectedAl m2 : 43|1@1+ (1,0) [0|1] "" Vector__XXX
 SG_ EPASTP_a161_tdaRelayfetjunctionT m2 : 44|1@1+ (1,0) [0|1] "" Vector__XXX
 SG_ EPASTP_a162_tdaBridgefetjunction m2 : 45|1@1+ (1,0) [0|1] "" Vector__XXX
 SG_ EPASTP_a163_tdaPowermoduleTempCh m2 : 46|1@1+ (1,0) [0|1] "" Vector__XXX
 SG_ EPASTP_a164_tdaBattfetjunctionTe m2 : 47|1@1+ (1,0) [0|1] "" Vector__XXX
 SG_ EPASTP_a165_tdaDcbusshuntTempChe m2 : 48|1@1+ (1,0) [0|1] "" Vector__XXX
 SG_ EPASTP_a166_tdaPhasecurrentshunt m2 : 49|1@1+ (1,0) [0|1] "" Vector__XXX
 SG_ EPASTP_a167_iccd1ErrQueueOverflo m2 : 50|1@1+ (1,0) [0|1] "" Vector__XXX
 SG_ EPASTP_a168_c1csInvalidC1App m2 : 51|1@1+ (1,0) [0|1] "" Vector__XXX
 SG_ EPASTP_a169_scpSafetyReset m2 : 52|1@1+ (1,0) [0|1] "" Vector__XXX
 SG_ EPASTP_a170_pmpDcvoltAge m2 : 53|1@1+ (1,0) [0|1] "" Vector__XXX
 SG_ EPASTP_a171_pmpKgvalueAge m2 : 54|1@1+ (1,0) [0|1] "" Vector__XXX
 SG_ EPASTP_a172_pmpElangMotorcurrent m2 : 55|1@1+ (1,0) [0|1] "" Vector__XXX
 SG_ EPASTP_a173_pmpRotorspeedAge m2 : 56|1@1+ (1,0) [0|1] "" Vector__XXX
 SG_ EPASTP_a174_pmpPhasecurrentAge m2 : 57|1@1+ (1,0) [0|1] "" Vector__XXX
 SG_ EPASTP_a175_exchFlashStoredConfi m2 : 58|1@1+ (1,0) [0|1] "" Vector__XXX
 SG_ EPASTP_a176_exchCpu1ExceptionRes m2 : 59|1@1+ (1,0) [0|1] "" Vector__XXX
 SG_ EPASTP_a177_etsrInvalidated m2 : 60|1@1+ (1,0) [0|1] "" Vector__XXX
 SG_ EPASTP_a178_exchWdtException m2 : 61|1@1+ (1,0) [0|1] "" Vector__XXX
 SG_ EPASTP_a179_tedMotorcoilTempChec m2 : 62|1@1+ (1,0) [0|1] "" Vector__XXX
 SG_ EPASTP_a180_dmDeadlineViolationC m2 : 63|1@1+ (1,0) [0|1] "" Vector__XXX
 SG_ EPASTP_a181_dmDeadlineViolationC m3 : 4|1@1+ (1,0) [0|1] "" Vector__XXX
 SG_ EPASTP_a182_mcdInputMia m3 : 5|1@1+ (1,0) [0|1] "" Vector__XXX
 SG_ EPASTP_a183_sbchCommErrSbcToMcu m3 : 6|1@1+ (1,0) [0|1] "" Vector__XXX
 SG_ EPASTP_a184_sbcmCommBufferOverfl m3 : 7|1@1+ (1,0) [0|1] "" Vector__XXX
 SG_ EPASTP_a185_sbcscpQAWatchdogRese m3 : 8|1@1+ (1,0) [0|1] "" Vector__XXX
 SG_ EPASTP_a186_wdhCommBufferOverflo m3 : 9|1@1+ (1,0) [0|1] "" Vector__XXX
 SG_ EPASTP_a187_epmVoltFail m3 : 10|1@1+ (1,0) [0|1] "" Vector__XXX
 SG_ EPASTP_a188_epmCommBufferOverflo m3 : 11|1@1+ (1,0) [0|1] "" Vector__XXX
 SG_ EPASTP_a189_sbchCommErrMcuToSbc m3 : 12|1@1+ (1,0) [0|1] "" Vector__XXX
 SG_ EPASTP_a190_sbchCommBufferOverfl m3 : 13|1@1+ (1,0) [0|1] "" Vector__XXX
 SG_ EPASTP_a191_sbcscpVcp2VucVoltFai m3 : 14|1@1+ (1,0) [0|1] "" Vector__XXX
 SG_ EPASTP_a192_osumC0CsaNearFull m3 : 15|1@1+ (1,0) [0|1] "" Vector__XXX
 SG_ EPASTP_a193_osumC0StackNearFull m3 : 16|1@1+ (1,0) [0|1] "" Vector__XXX
 SG_ EPASTP_a194_amNvdataLoss m3 : 17|1@1+ (1,0) [0|1] "" Vector__XXX
 SG_ EPASTP_a195_imcmCommErrC1 m3 : 18|1@1+ (1,0) [0|1] "" Vector__XXX
 SG_ EPASTP_a196_topEolTasOffsetInval m3 : 19|1@1+ (1,0) [0|1] "" Vector__XXX
 SG_ EPASTP_a197_difpDifactorInvalid m3 : 20|1@1+ (1,0) [0|1] "" Vector__XXX
 SG_ EPASTP_a198_osumC1CsaNearFull m3 : 21|1@1+ (1,0) [0|1] "" Vector__XXX
 SG_ EPASTP_a199_osumC1StackNearFull m3 : 22|1@1+ (1,0) [0|1] "" Vector__XXX
 SG_ EPASTP_a200_ammInputBufferOverfl m3 : 23|1@1+ (1,0) [0|1] "" Vector__XXX
 SG_ EPASTP_a201_ammOutputBufferOverf m3 : 24|1@1+ (1,0) [0|1] "" Vector__XXX
 SG_ EPASTP_a202_ohnvmpStoredOffsetLo m3 : 25|1@1+ (1,0) [0|1] "" Vector__XXX
 SG_ EPASTP_a203_ctcInterfaceErr m3 : 26|1@1+ (1,0) [0|1] "" Vector__XXX
 SG_ EPASTP_a204_fdpPrevTrqErr m3 : 27|1@1+ (1,0) [0|1] "" Vector__XXX
 SG_ EPASTP_a205_fdrOclFail m3 : 28|1@1+ (1,0) [0|1] "" Vector__XXX
 SG_ EPASTP_a206_fdrOclPartialBlockin m3 : 29|1@1+ (1,0) [0|1] "" Vector__XXX
 SG_ EPASTP_a207_fdrOclFreezing m3 : 30|1@1+ (1,0) [0|1] "" Vector__XXX
 SG_ EPASTP_a208_fdrLowSeverityBlocki m3 : 31|1@1+ (1,0) [0|1] "" Vector__XXX
 SG_ EPASTP_a209_fdrLowSeverityFreezi m3 : 32|1@1+ (1,0) [0|1] "" Vector__XXX
 SG_ EPASTP_a210_fdrTotalBlocking m3 : 33|1@1+ (1,0) [0|1] "" Vector__XXX
 SG_ EPASTP_a211_frmInternalErr m3 : 34|1@1+ (1,0) [0|1] "" Vector__XXX
 SG_ EPASTP_a212_frmDataLost m3 : 35|1@1+ (1,0) [0|1] "" Vector__XXX
 SG_ EPASTP_a213_frmHighFrictionDetec m3 : 36|1@1+ (1,0) [0|1] "" Vector__XXX
 SG_ EPASTP_a214_velInterfaceErr m3 : 37|1@1+ (1,0) [0|1] "" Vector__XXX
 SG_ EPASTP_a215_vsgSafeViolErr m3 : 38|1@1+ (1,0) [0|1] "" Vector__XXX
 SG_ EPASTP_a216_isdgImproperShutdown m3 : 39|1@1+ (1,0) [0|1] "" Vector__XXX
 SG_ EPASTP_a217_msdMasterSilentErr m3 : 40|1@1+ (1,0) [0|1] "" Vector__XXX
 SG_ EPASTP_a218_aadApplicationStateE m3 : 41|1@1+ (1,0) [0|1] "" Vector__XXX
 SG_ EPASTP_a219_frhFastRestartFailed m3 : 42|1@1+ (1,0) [0|1] "" Vector__XXX
 SG_ EPASTP_a221_apsCntError m3 : 43|1@1+ (1,0) [0|1] "" Vector__XXX
 SG_ EPASTP_a222_apsCsError m3 : 44|1@1+ (1,0) [0|1] "" Vector__XXX
 SG_ EPASTP_a223_apsMia m3 : 45|1@1+ (1,0) [0|1] "" Vector__XXX
 SG_ EPASTP_a224_dasCntError m3 : 46|1@1+ (1,0) [0|1] "" Vector__XXX
 SG_ EPASTP_a225_dasCsError m3 : 47|1@1+ (1,0) [0|1] "" Vector__XXX
 SG_ EPASTP_a226_dasMia m3 : 48|1@1+ (1,0) [0|1] "" Vector__XXX
 SG_ EPASTP_a227_dirTorqueCntError m3 : 49|1@1+ (1,0) [0|1] "" Vector__XXX
 SG_ EPASTP_a228_dirTorqueCsError m3 : 50|1@1+ (1,0) [0|1] "" Vector__XXX
 SG_ EPASTP_a229_dirTorqueMia m3 : 51|1@1+ (1,0) [0|1] "" Vector__XXX
 SG_ EPASTP_a230_diSpdCntError m3 : 52|1@1+ (1,0) [0|1] "" Vector__XXX
 SG_ EPASTP_a231_diSpdCsError m3 : 53|1@1+ (1,0) [0|1] "" Vector__XXX
 SG_ EPASTP_a232_diSpdMia m3 : 54|1@1+ (1,0) [0|1] "" Vector__XXX
 SG_ EPASTP_a233_ecu2StatCntError m3 : 55|1@1+ (1,0) [0|1] "" Vector__XXX
 SG_ EPASTP_a234_ecu2StatCsError m3 : 56|1@1+ (1,0) [0|1] "" Vector__XXX
 SG_ EPASTP_a235_ecu2StatMia m3 : 57|1@1+ (1,0) [0|1] "" Vector__XXX
 SG_ EPASTP_a236_espWrCntError m3 : 58|1@1+ (1,0) [0|1] "" Vector__XXX
 SG_ EPASTP_a237_espWrCsError m3 : 59|1@1+ (1,0) [0|1] "" Vector__XXX
 SG_ EPASTP_a238_espWrMia m3 : 60|1@1+ (1,0) [0|1] "" Vector__XXX
 SG_ EPASTP_a239_espWsCntError m3 : 61|1@1+ (1,0) [0|1] "" Vector__XXX
 SG_ EPASTP_a240_espWsCsError m3 : 62|1@1+ (1,0) [0|1] "" Vector__XXX
 SG_ EPASTP_a241_espWsMia m3 : 63|1@1+ (1,0) [0|1] "" Vector__XXX
 SG_ EPASTP_a242_gtwConfigMia m4 : 4|1@1+ (1,0) [0|1] "" Vector__XXX
 SG_ EPASTP_a243_rcmCntError m4 : 5|1@1+ (1,0) [0|1] "" Vector__XXX
 SG_ EPASTP_a244_rcmCsError m4 : 6|1@1+ (1,0) [0|1] "" Vector__XXX
 SG_ EPASTP_a245_rcmMia m4 : 7|1@1+ (1,0) [0|1] "" Vector__XXX
 SG_ EPASTP_a246_sccmCntError m4 : 8|1@1+ (1,0) [0|1] "" Vector__XXX
 SG_ EPASTP_a247_sccmCsError m4 : 9|1@1+ (1,0) [0|1] "" Vector__XXX
 SG_ EPASTP_a248_sccmMia m4 : 10|1@1+ (1,0) [0|1] "" Vector__XXX
 SG_ EPASTP_a249_uiTuneReqCntError m4 : 11|1@1+ (1,0) [0|1] "" Vector__XXX
 SG_ EPASTP_a250_uiTuneReqCsError m4 : 12|1@1+ (1,0) [0|1] "" Vector__XXX
 SG_ EPASTP_a251_uiTuneReqMia m4 : 13|1@1+ (1,0) [0|1] "" Vector__XXX
 SG_ EPASTP_a252_vcFrontCntError m4 : 14|1@1+ (1,0) [0|1] "" Vector__XXX
 SG_ EPASTP_a253_vcFrontCsError m4 : 15|1@1+ (1,0) [0|1] "" Vector__XXX
 SG_ EPASTP_a254_vcFrontMia m4 : 16|1@1+ (1,0) [0|1] "" Vector__XXX
 SG_ EPASTP_a255_pmState2Mia m4 : 17|1@1+ (1,0) [0|1] "" Vector__XXX
 SG_ EPASTP_a256_dcvmOverVolt m4 : 18|1@1+ (1,0) [0|1] "" Vector__XXX
 SG_ EPASTP_a257_dcvmUnderVolt m4 : 19|1@1+ (1,0) [0|1] "" Vector__XXX
 SG_ EPASTP_a258_pspInvalidProjectPar m4 : 20|1@1+ (1,0) [0|1] "" Vector__XXX
 SG_ EPASTP_a259_scoCanBusOff m4 : 21|1@1+ (1,0) [0|1] "" Vector__XXX
 SG_ EPASTP_a260_scoPrivateBusOff m4 : 22|1@1+ (1,0) [0|1] "" Vector__XXX
 SG_ EPASTP_a261_sccmStatusError m4 : 23|1@1+ (1,0) [0|1] "" Vector__XXX
 SG_ EPASTP_a262_yawRateStatus m4 : 24|1@1+ (1,0) [0|1] "" Vector__XXX
 SG_ EPASTP_a263_espWsStatus m4 : 25|1@1+ (1,0) [0|1] "" Vector__XXX
 SG_ EPASTP_a264_assistTorqueLimited m4 : 26|1@1+ (1,0) [0|1] "" Vector__XXX
 SG_ EPASTP_a265_overheatProtect m4 : 27|1@1+ (1,0) [0|1] "" Vector__XXX
 SG_ EPASTP_a266_overloadProtect m4 : 28|1@1+ (1,0) [0|1] "" Vector__XXX
 SG_ EPASTP_a267_safeSpeedAssist m4 : 29|1@1+ (1,0) [0|1] "" Vector__XXX
 SG_ EPASTP_a268_eacCancelled m4 : 30|1@1+ (1,0) [0|1] "" Vector__XXX
 SG_ EPASTP_a269_assistTorqueDisabled m4 : 31|1@1+ (1,0) [0|1] "" Vector__XXX
 SG_ EPASTP_a270_oscillationCompTrqLi m4 : 32|1@1+ (1,0) [0|1] "" Vector__XXX

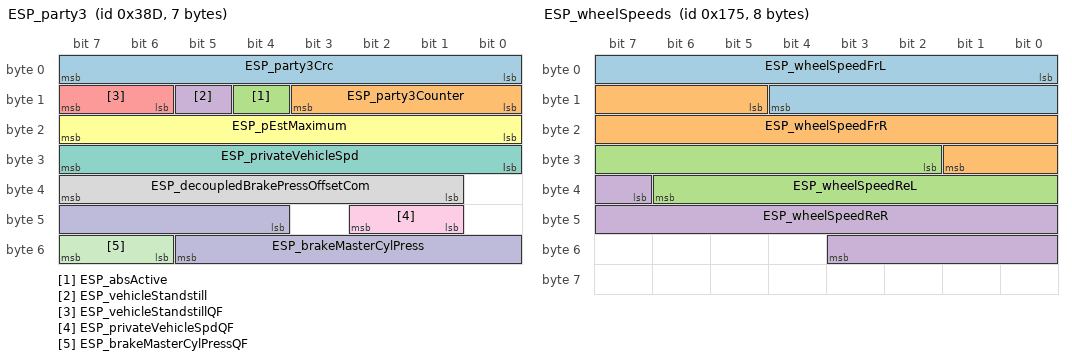
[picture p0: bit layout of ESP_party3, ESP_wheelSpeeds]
BO_ 909 ESP_party3: 7 ESP
 SG_ ESP_party3Crc : 0|8@1+ (1,0) [0|255] "" Vector__XXX
 SG_ ESP_party3Counter : 8|4@1+ (1,0) [0|15] "" Vector__XXX
 SG_ ESP_absActive : 12|1@1+ (1,0) [0|1] "" Vector__XXX
 SG_ ESP_vehicleStandstill : 13|1@1+ (1,0) [0|1] "" Vector__XXX
 SG_ ESP_vehicleStandstillQF : 14|2@1+ (1,0) [0|3] "" Vector__XXX
 SG_ ESP_pEstMaximum : 16|8@1+ (1,0) [0|255] "bar" Vector__XXX
 SG_ ESP_privateVehicleSpd : 24|8@1+ (0.4,0) [0|102] "m/s" Vector__XXX
 SG_ ESP_decoupledBrakePressOffsetCom : 33|7@1+ (0.25,-16) [-16|15.5] "bar" Vector__XXX
 SG_ ESP_privateVehicleSpdQF : 41|2@1+ (1,0) [0|3] "" Vector__XXX
 SG_ ESP_brakeMasterCylPress : 44|10@1+ (0.3,-30) [-30|276.6] "bar" Vector__XXX
 SG_ ESP_brakeMasterCylPressQF : 54|2@1+ (1,0) [0|3] "" Vector__XXX

BO_ 325 ESP_status: 8 ESP
 SG_ ESP_statusChecksum : 0|8@1+ (1,0) [0|255] "" Vector__XXX
 SG_ ESP_statusCounter : 8|4@1+ (1,0) [0|15] "" Vector__XXX
 SG_ ESP_espModeActive : 12|2@1+ (1,0) [0|3] "" Vector__XXX
 SG_ ESP_stabilityControlSts2 : 14|2@1+ (1,0) [0|3] "" Vector__XXX
 SG_ ESP_ebdFaultLamp : 16|1@1+ (1,0) [0|1] "" Vector__XXX
 SG_ ESP_absFaultLamp : 17|1@1+ (1,0) [0|1] "" Vector__XXX
 SG_ ESP_espFaultLamp : 18|1@1+ (1,0) [0|1] "" Vector__XXX
 SG_ ESP_hydraulicBoostEnabled : 19|1@1+ (1,0) [0|1] "" Vector__XXX
 SG_ ESP_espLampFlash : 20|1@1+ (1,0) [0|1] "" Vector__XXX
 SG_ ESP_brakeLamp : 21|1@1+ (1,0) [0|1] "" Vector__XXX
 SG_ ESP_absBrakeEvent2 : 22|2@1+ (1,0) [0|3] "" Vector__XXX
 SG_ ESP_longitudinalAccelQF : 24|1@1+ (1,0) [0|1] "" Vector__XXX
 SG_ ESP_lateralAccelQF : 25|1@1+ (1,0) [0|1] "" Vector__XXX
 SG_ ESP_yawRateQF : 26|1@1+ (1,0) [0|1] "" Vector__XXX
 SG_ ESP_steeringAngleQF : 27|1@1+ (1,0) [0|1] "" Vector__XXX
 SG_ ESP_brakeDiscWipingActive : 28|1@1+ (1,0) [0|1] "" Vector__XXX
 SG_ ESP_driverBrakeApply : 29|2@1+ (1,0) [0|2] "" Vector__XXX
 SG_ ESP_brakeApply : 31|1@1+ (1,0) [0|1] "" Vector__XXX
 SG_ ESP_aesPrimaryActuatorStatus : 32|2@1+ (1,0) [0|3] "" Vector__XXX
 SG_ ESP_cdpStatus : 34|2@1+ (1,0) [0|3] "" Vector__XXX
 SG_ ESP_ptcTargetState : 36|2@1+ (1,0) [0|2] "" Vector__XXX
 SG_ ESP_btcTargetState : 38|2@1+ (1,0) [0|2] "" Vector__XXX
 SG_ ESP_decoupledBrakePressEst : 40|8@1+ (1,-30) [-30|224] "bar" Vector__XXX
 SG_ ESP_ebrStandstillSkid : 48|1@1+ (1,0) [0|1] "" Vector__XXX
 SG_ ESP_ebrStatus : 49|2@1+ (1,0) [0|3] "" Vector__XXX
 SG_ ESP_brakeTorqueTarget : 51|13@1+ (3,0) [0|24573] "Nm" Vector__XXX

BO_ 373 ESP_wheelSpeeds: 8 ESP
 SG_ ESP_wheelSpeedFrL : 0|13@1+ (0.042,0) [0|343.98] "km/h" Vector__XXX
 SG_ ESP_wheelSpeedFrR : 13|13@1+ (0.042,0) [0|343.98] "km/h" Vector__XXX
 SG_ ESP_wheelSpeedReL : 26|13@1+ (0.042,0) [0|343.98] "km/h" Vector__XXX
 SG_ ESP_wheelSpeedReR : 39|13@1+ (0.042,0) [0|343.98] "km/h" Vector__XXX

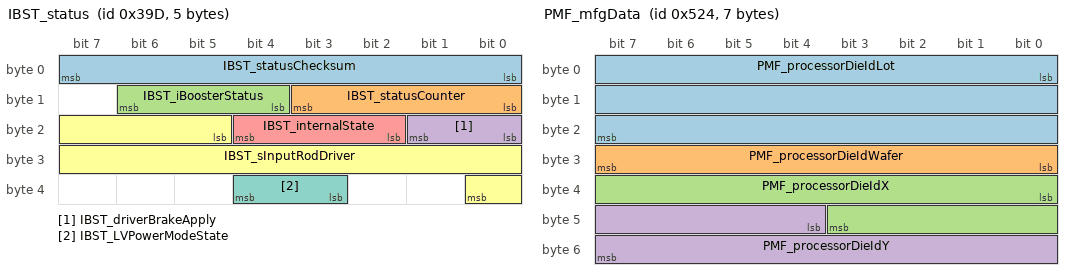
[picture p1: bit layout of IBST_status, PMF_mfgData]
BO_ 925 IBST_status: 5 IBST
 SG_ IBST_statusChecksum : 0|8@1+ (1,0) [0|255] "" Vector__XXX
 SG_ IBST_statusCounter : 8|4@1+ (1,0) [0|15] "" Vector__XXX
 SG_ IBST_iBoosterStatus : 12|3@1+ (1,0) [0|7] "" Vector__XXX
 SG_ IBST_driverBrakeApply : 16|2@1+ (1,0) [0|3] "" Vector__XXX
 SG_ IBST_internalState : 18|3@1+ (1,0) [0|7] "" Vector__XXX
 SG_ IBST_sInputRodDriver : 21|12@1+ (0.015625,-5) [-5|47] "mm" Vector__XXX
 SG_ IBST_LVPowerModeState : 35|2@1+ (1,0) [0|3] "" Vector__XXX

BO_ 1316 PMF_mfgData: 7 PMF
 SG_ PMF_processorDieIdLot : 0|24@1+ (1,0) [0|16777215] "" Vector__XXX
 SG_ PMF_processorDieIdWafer : 24|8@1+ (1,0) [0|255] "" Vector__XXX
 SG_ PMF_processorDieIdX : 32|12@1+ (1,0) [0|4095] "" Vector__XXX
 SG_ PMF_processorDieIdY : 44|12@1+ (1,0) [0|4095] "" Vector__XXX

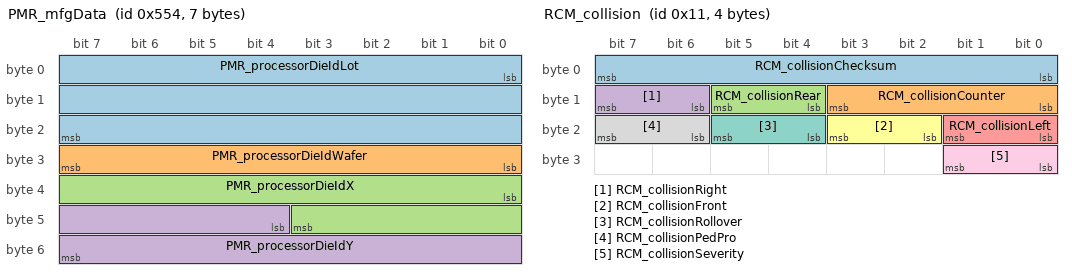
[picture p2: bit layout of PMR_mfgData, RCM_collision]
BO_ 1364 PMR_mfgData: 7 PMR
 SG_ PMR_processorDieIdLot : 0|24@1+ (1,0) [0|16777215] "" Vector__XXX
 SG_ PMR_processorDieIdWafer : 24|8@1+ (1,0) [0|255] "" Vector__XXX
 SG_ PMR_processorDieIdX : 32|12@1+ (1,0) [0|4095] "" Vector__XXX
 SG_ PMR_processorDieIdY : 44|12@1+ (1,0) [0|4095] "" Vector__XXX

BO_ 1973 PM_itpmsDisplay: 3 PM
 SG_ PM_itpmsDisplaySelector M : 0|2@1+ (1,0) [0|3] "" Vector__XXX
 SG_ PM_indirectTPMSTellTale m0 : 2|2@1+ (1,0) [0|3] "" Vector__XXX
 SG_ PM_indirectTPMSDisplayState m0 : 4|2@1+ (1,0) [0|3] "" Vector__XXX
 SG_ PM_indirectTPMSDisplayProgress m0 : 8|5@1+ (0.05,0) [0|1] "-" Vector__XXX
 SG_ PM_indirectTPMSDisplayWarningInd m0 : 13|2@1+ (1,0) [0|3] "" Vector__XXX
 SG_ PM_indirectTPMSDisplayWarni_0001 m0 : 16|2@1+ (1,0) [0|3] "" Vector__XXX
 SG_ PM_indirectTPMSDisplayWarni_0002 m0 : 18|2@1+ (1,0) [0|3] "" Vector__XXX
 SG_ PM_indirectTPMSDisplayWarni_0003 m0 : 20|2@1+ (1,0) [0|3] "" Vector__XXX
 SG_ PM_indirectTPMSRecommendedColdPr m1 : 8|8@1+ (0.025,0) [0|6.35] "bar" Vector__XXX
 SG_ PM_indirectTPMSRecommendedC_0001 m1 : 16|8@1+ (0.025,0) [0|6.35] "bar" Vector__XXX
 SG_ PM_fusedPressureEstimateFrL m2 : 2|9@1+ (0.008,0) [0|4] "bar" Vector__XXX
 SG_ PM_fusedPressureEstimateFrR m2 : 11|9@1+ (0.008,0) [0|4] "bar" Vector__XXX
 SG_ PM_fusedPressureEstimateReL m3 : 2|9@1+ (0.008,0) [0|4] "bar" Vector__XXX
 SG_ PM_fusedPressureEstimateReR m3 : 11|9@1+ (0.008,0) [0|4] "bar" Vector__XXX

BO_ 2038 PM_vdcDebug: 8 PM
 SG_ PM_vdcDebugSelector M : 0|6@1+ (1,0) [0|63] "" Vector__XXX
 SG_ PM_VDCA_TCSlipTargetMod_RA_Fwd m5 : 8|6@1- (0.1,0) [-3|3] "m/s" Vector__XXX
 SG_ PM_VDCA_TCSlipTargetMod_RA_Rwd m5 : 16|6@1- (0.1,0) [-3|3] "m/s" Vector__XXX
 SG_ PM_VSE_forceY_RA m5 : 22|9@1- (40,240) [-10000|10440] "N" Vector__XXX
 SG_ PM_VDCT_observerSlipAngle_RA m5 : 31|9@1- (0.005,0.03) [-1.25|1.305] "rad" Vector__XXX
 SG_ PM_VSE_muVehicleFxLow m5 : 40|5@1+ (0.05,0) [0|1.55] "mu" Vector__XXX
 SG_ PM_VE_fxmFres m13 : 8|8@1- (200,0) [-20000|20000] "N" Vector__XXX
 SG_ PM_VE_fxAccelMass m13 : 16|8@1- (0.16,0) [-20|20] "m/s^2" Vector__XXX
 SG_ PM_VE_vxDotGrade m13 : 24|8@1- (0.1,0.8) [-12|13.5] "m/s^2" Vector__XXX
 SG_ PM_VE_betaEst m13 : 32|8@1- (0.01,0) [-1|1] "rad" Vector__XXX
 SG_ PM_VSE_muVehicleFxHigh m13 : 40|5@1+ (0.05,0) [0|1.55] "mu" Vector__XXX
 SG_ PM_VSE_muVehicleDecLeakRate m29 : 6|5@1+ (0.05,0) [0|1.55] "mu" Vector__XXX
 SG_ PM_VSE_muVehicleLearnDown m29 : 11|5@1+ (0.05,0) [0|1.55] "mu" Vector__XXX
 SG_ PM_VSE_muVehicleDecFilter m29 : 16|5@1+ (0.05,0) [0|1.55] "mu" Vector__XXX
 SG_ PM_VSE_muVehicleLatDecLeakRate m29 : 21|5@1+ (0.05,0) [0|1.55] "mu" Vector__XXX
 SG_ PM_VSE_splitMuProbability m29 : 26|5@1+ (0.05,0) [0|1.55] "probability" Vector__XXX
 SG_ PM_VSE_splitMuTotalMz m29 : 31|9@1- (60,360) [-15000|15660] "Nm" Vector__XXX
 SG_ PM_VSE_attitudeBankAngle m29 : 40|9@1- (0.005,0.03) [-1.25|1.305] "rad" Vector__XXX
 SG_ PM_VSE_attitudeDBetaInControl m29 : 49|8@1- (0.01,0.03) [-1.25|1.3] "rad" Vector__XXX
 SG_ PM_VSE_roadWheelAngleAverage m29 : 57|7@1- (0.015,0.255) [-0.7|1.2] "rad" Vector__XXX

BO_ 17 RCM_collision: 4 RCM
 SG_ RCM_collisionChecksum : 0|8@1+ (1,0) [0|255] "" Vector__XXX
 SG_ RCM_collisionCounter : 8|4@1+ (1,0) [0|15] "" Vector__XXX
 SG_ RCM_collisionRear : 12|2@1+ (1,0) [0|2] "" Vector__XXX
 SG_ RCM_collisionRight : 14|2@1+ (1,0) [0|2] "" Vector__XXX
 SG_ RCM_collisionLeft : 16|2@1+ (1,0) [0|2] "" Vector__XXX
 SG_ RCM_collisionFront : 18|2@1+ (1,0) [0|2] "" Vector__XXX
 SG_ RCM_collisionRollover : 20|2@1+ (1,0) [0|2] "" Vector__XXX
 SG_ RCM_collisionPedPro : 22|2@1+ (1,0) [0|2] "" Vector__XXX
 SG_ RCM_collisionSeverity : 24|2@1+ (1,0) [0|3] "" Vector__XXX

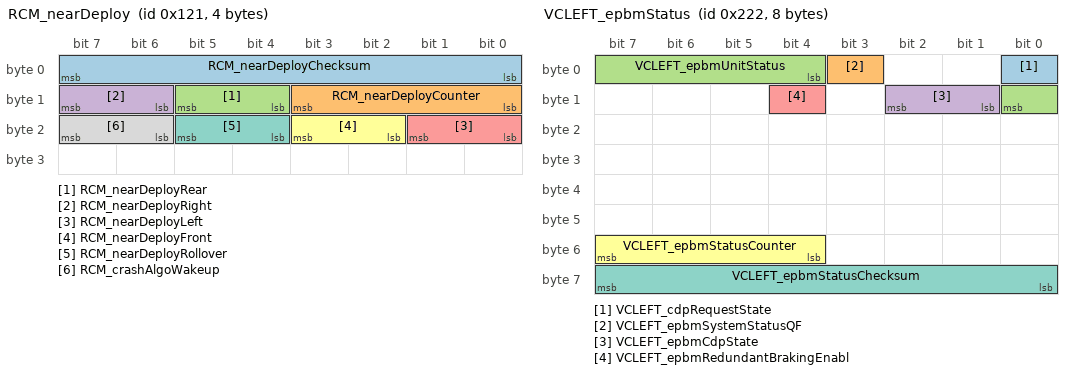
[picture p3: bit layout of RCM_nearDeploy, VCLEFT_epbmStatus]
BO_ 289 RCM_nearDeploy: 4 RCM
 SG_ RCM_nearDeployChecksum : 0|8@1+ (1,0) [0|255] "" Vector__XXX
 SG_ RCM_nearDeployCounter : 8|4@1+ (1,0) [0|15] "" Vector__XXX
 SG_ RCM_nearDeployRear : 12|2@1+ (1,0) [0|2] "" Vector__XXX
 SG_ RCM_nearDeployRight : 14|2@1+ (1,0) [0|2] "" Vector__XXX
 SG_ RCM_nearDeployLeft : 16|2@1+ (1,0) [0|2] "" Vector__XXX
 SG_ RCM_nearDeployFront : 18|2@1+ (1,0) [0|2] "" Vector__XXX
 SG_ RCM_nearDeployRollover : 20|2@1+ (1,0) [0|2] "" Vector__XXX
 SG_ RCM_crashAlgoWakeup : 22|2@1+ (1,0) [0|2] "" Vector__XXX

BO_ 1618 VCBATT0_info: 8 VCBATT0
 SG_ VCBATT0_infoIndex M : 0|8@1+ (1,0) [0|255] "" Vector__XXX
 SG_ VCBATT0_infoBuildType m10 : 8|3@1+ (1,0) [0|7] "" Vector__XXX
 SG_ VCBATT0_infoBuildConfigId m10 : 16|16@1+ (1,0) [0|65535] "" Vector__XXX
 SG_ VCBATT0_infoHardwareId m10 : 32|16@1+ (1,0) [0|65535] "" Vector__XXX
 SG_ VCBATT0_infoComponentId m10 : 48|16@1+ (1,0) [0|65535] "" Vector__XXX
 SG_ VCBATT0_infoPcbaId m11 : 8|8@1+ (1,0) [0|255] "" Vector__XXX
 SG_ VCBATT0_infoAssemblyId m11 : 16|8@1+ (1,0) [0|254] "" Vector__XXX
 SG_ VCBATT0_infoUsageId m11 : 24|16@1+ (1,0) [0|65535] "" Vector__XXX
 SG_ VCBATT0_infoSubUsageId m11 : 40|16@1+ (1,0) [0|65535] "" Vector__XXX
 SG_ VCBATT0_infoAppCrc m13 : 8|32@1+ (1,0) [0|4294967295] "" Vector__XXX
 SG_ VCBATT0_infoAppGitHash m17 : 8|56@1+ (1,0) [0|7.20575940379e+16] "" Vector__XXX
 SG_ VCBATT0_infoBootGitHash m18 : 8|56@1+ (1,0) [0|7.20575940379e+16] "" Vector__XXX
 SG_ VCBATT0_infoBootUdsProtoVersion m20 : 8|16@1+ (1,0) [0|65535] "" Vector__XXX
 SG_ VCBATT0_infoBootCrc m20 : 24|32@1+ (1,0) [0|4294967295] "" Vector__XXX

BO_ 1994 VCCC_info: 8 VCCC
 SG_ VCCC_infoIndex M : 0|8@1+ (1,0) [0|255] "" Vector__XXX
 SG_ VCCC_infoBuildType m10 : 8|8@1+ (1,0) [0|255] "" Vector__XXX
 SG_ VCCC_infoBuildConfigId m10 : 16|16@1+ (1,0) [0|65535] "" Vector__XXX
 SG_ VCCC_infoHardwareId m10 : 32|16@1+ (1,0) [0|65535] "" Vector__XXX
 SG_ VCCC_infoComponentId m10 : 48|16@1+ (1,0) [0|65535] "" Vector__XXX
 SG_ VCCC_infoPcbaId m11 : 8|8@1+ (1,0) [0|255] "" Vector__XXX
 SG_ VCCC_infoAssemblyId m11 : 16|8@1+ (1,0) [0|254] "" Vector__XXX
 SG_ VCCC_infoUsageId m11 : 24|16@1+ (1,0) [0|65535] "" Vector__XXX
 SG_ VCCC_infoSubUsageId m11 : 40|16@1+ (1,0) [0|65535] "" Vector__XXX
 SG_ VCCC_infoAppCrc m13 : 8|32@1+ (1,0) [0|4294967295] "" Vector__XXX
 SG_ VCCC_infoAppGitHash m17 : 8|56@1+ (1,0) [0|7.20575940379e+16] "" Vector__XXX
 SG_ VCCC_infoBootGitHash m18 : 8|56@1+ (1,0) [0|7.20575940379e+16] "" Vector__XXX
 SG_ VCCC_infoBootUdsProtoVersion m20 : 8|8@1+ (1,0) [0|255] "" Vector__XXX
 SG_ VCCC_infoBootCrc m20 : 24|32@1+ (1,0) [0|4294967295] "" Vector__XXX

BO_ 260 VCFRONT_partyDebug: 7 VCFRONT
 SG_ VCFRONT_vcleftHighPower : 0|1@1+ (1,0) [0|1] "" Vector__XXX
 SG_ VCFRONT_vcrightHighPower : 1|1@1+ (1,0) [0|1] "" Vector__XXX
 SG_ VCFRONT_uiHighPower : 2|1@1+ (1,0) [0|1] "" Vector__XXX
 SG_ VCFRONT_5VAStable : 3|1@1+ (1,0) [0|1] "" Vector__XXX
 SG_ VCFRONT_5VBStable : 4|1@1+ (1,0) [0|1] "" Vector__XXX
 SG_ VCFRONT_12VAStable : 5|1@1+ (1,0) [0|1] "" Vector__XXX
 SG_ VCFRONT_12VBStable : 6|1@1+ (1,0) [0|1] "" Vector__XXX
 SG_ VCFRONT_railA : 7|1@1+ (1,0) [0|1] "" Vector__XXX
 SG_ VCFRONT_railB : 8|1@1+ (1,0) [0|1] "" Vector__XXX
 SG_ VCFRONT_chargePumpStable : 9|1@1+ (1,0) [0|1] "" Vector__XXX
 SG_ VCFRONT_vehicleSM : 10|5@1+ (1,0) [0|31] "" Vector__XXX
 SG_ VCFRONT_revBattFault : 15|1@1+ (1,0) [0|1] "" Vector__XXX
 SG_ VCFRONT_battSM : 16|4@1+ (1,0) [0|15] "" Vector__XXX
 SG_ VCFRONT_U13Init : 20|1@1+ (1,0) [0|1] "" Vector__XXX
 SG_ VCFRONT_U16Init : 21|1@1+ (1,0) [0|1] "" Vector__XXX
 SG_ VCFRONT_anyVehLoadShedActiveDBG : 22|1@1+ (1,0) [0|1] "" Vector__XXX
 SG_ VCFRONT_battVoltage : 24|12@1+ (0.005443676,0) [0|22.29185322] "V" Vector__XXX
 SG_ VCFRONT_battCurrent : 40|16@1- (0.005,0) [-163.84|163.835] "A" Vector__XXX

BO_ 258 VCLEFT_doorStatus: 8 VCLEFT
 SG_ VCLEFT_doorClosureStatusFront : 0|4@1+ (1,0) [1|15] "" Vector__XXX
 SG_ VCLEFT_doorClosureStatusRear : 4|4@1+ (1,0) [1|15] "" Vector__XXX
 SG_ VCLEFT_frontLatchSwitch : 8|1@1+ (1,0) [0|1] "" Vector__XXX
 SG_ VCLEFT_rearLatchSwitch : 9|1@1+ (1,0) [0|1] "" Vector__XXX
 SG_ VCLEFT_frontHandlePulled : 10|1@1+ (1,0) [0|1] "" Vector__XXX
 SG_ VCLEFT_rearHandlePulled : 11|1@1+ (1,0) [0|1] "" Vector__XXX
 SG_ VCLEFT_frontRelActuatorSwitch : 12|1@1+ (1,0) [0|1] "" Vector__XXX
 SG_ VCLEFT_rearRelActuatorSwitch : 13|1@1+ (1,0) [0|1] "" Vector__XXX
 SG_ VCLEFT_frontLatchStatus : 14|4@1+ (1,0) [1|15] "" Vector__XXX
 SG_ VCLEFT_rearLatchStatus : 18|4@1+ (1,0) [1|15] "" Vector__XXX
 SG_ VCLEFT_lastDoorReqSourceFront : 22|3@1+ (1,0) [0|7] "" Vector__XXX
 SG_ VCLEFT_lastDoorReqSourceRear : 25|3@1+ (1,0) [0|7] "" Vector__XXX
 SG_ VCLEFT_frontIntSwitchFaulted : 28|1@1+ (1,0) [0|1] "" Vector__XXX
 SG_ VCLEFT_rearIntSwitchFaulted : 29|1@1+ (1,0) [0|1] "" Vector__XXX
 SG_ VCLEFT_frontIntSwitchPressed : 31|1@1+ (1,0) [0|1] "" Vector__XXX
 SG_ VCLEFT_rearIntSwitchPressed : 32|1@1+ (1,0) [0|1] "" Vector__XXX
 SG_ VCLEFT_mirrorTiltXPosition : 33|8@1+ (0.02,0) [0|5] "V" Vector__XXX
 SG_ VCLEFT_mirrorTiltYPosition : 41|8@1+ (0.02,0) [0|5] "V" Vector__XXX
 SG_ VCLEFT_mirrorState : 49|3@1+ (1,0) [0|7] "" Vector__XXX
 SG_ VCLEFT_mirrorFoldState : 52|3@1+ (1,0) [0|7] "" Vector__XXX
 SG_ VCLEFT_mirrorRecallState : 55|3@1+ (1,0) [0|7] "" Vector__XXX
 SG_ VCLEFT_mirrorHeatState : 58|3@1+ (1,0) [1|7] "" Vector__XXX
 SG_ VCLEFT_rearHandlePulledPersist : 61|1@1+ (1,0) [0|1] "" Vector__XXX
 SG_ VCLEFT_frontHandlePulledPersist : 62|1@1+ (1,0) [0|1] "" Vector__XXX
 SG_ VCLEFT_mirrorDipped : 63|1@1+ (1,0) [0|1] "" Vector__XXX

BO_ 546 VCLEFT_epbmStatus: 8 VCLEFT
 SG_ VCLEFT_cdpRequestState : 0|1@1+ (1,0) [0|1] "" Vector__XXX
 SG_ VCLEFT_epbmSystemStatusQF : 3|1@1+ (1,0) [0|1] "" Vector__XXX
 SG_ VCLEFT_epbmUnitStatus : 4|5@1+ (1,0) [0|31] "" Vector__XXX
 SG_ VCLEFT_epbmCdpState : 9|2@1+ (1,0) [0|3] "" Vector__XXX
 SG_ VCLEFT_epbmRedundantBrakingEnabl : 12|1@1+ (1,0) [0|1] "" Vector__XXX
 SG_ VCLEFT_epbmStatusCounter : 52|4@1+ (1,0) [0|15] "" Vector__XXX
 SG_ VCLEFT_epbmStatusChecksum : 56|8@1+ (1,0) [0|255] "" Vector__XXX

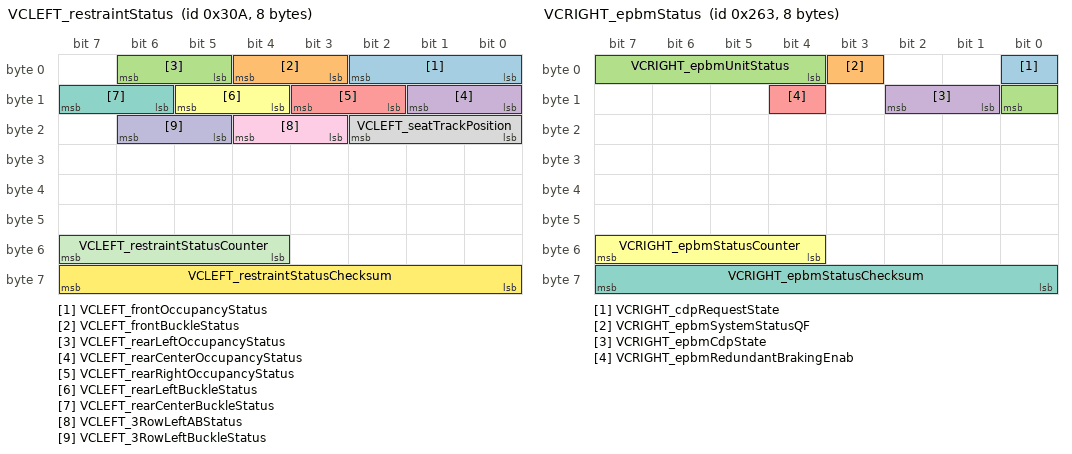
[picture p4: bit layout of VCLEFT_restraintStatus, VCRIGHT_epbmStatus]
BO_ 778 VCLEFT_restraintStatus: 8 VCLEFT
 SG_ VCLEFT_frontOccupancyStatus : 0|3@1+ (1,0) [0|6] "" Vector__XXX
 SG_ VCLEFT_frontBuckleStatus : 3|2@1+ (1,0) [0|3] "" Vector__XXX
 SG_ VCLEFT_rearLeftOccupancyStatus : 5|2@1+ (1,0) [0|3] "" Vector__XXX
 SG_ VCLEFT_rearCenterOccupancyStatus : 8|2@1+ (1,0) [0|3] "" Vector__XXX
 SG_ VCLEFT_rearRightOccupancyStatus : 10|2@1+ (1,0) [0|3] "" Vector__XXX
 SG_ VCLEFT_rearLeftBuckleStatus : 12|2@1+ (1,0) [0|3] "" Vector__XXX
 SG_ VCLEFT_rearCenterBuckleStatus : 14|2@1+ (1,0) [0|3] "" Vector__XXX
 SG_ VCLEFT_seatTrackPosition : 16|3@1+ (1,0) [0|6] "" Vector__XXX
 SG_ VCLEFT_3RowLeftABStatus : 19|2@1+ (1,0) [0|3] "" Vector__XXX
 SG_ VCLEFT_3RowLeftBuckleStatus : 21|2@1+ (1,0) [0|3] "" Vector__XXX
 SG_ VCLEFT_restraintStatusCounter : 52|4@1+ (1,0) [0|15] "" Vector__XXX
 SG_ VCLEFT_restraintStatusChecksum : 56|8@1+ (1,0) [0|255] "" Vector__XXX

BO_ 1124 VCRIGHT_AP_hvacState1Hz: 8 VCRIGHT
 SG_ VCRIGHT_AP_hvacState1HzIndex M : 0|1@1+ (1,0) [0|1] "" Vector__XXX
 SG_ VCRIGHT_AP_tempCameraModele_0001 m0 : 2|8@1+ (0.5,-40) [-40|85] "degC" Vector__XXX
 SG_ VCRIGHT_AP_tempCameraModeledWind m0 : 10|8@1+ (0.5,-40) [-40|85] "degC" Vector__XXX
 SG_ VCRIGHT_AP_cameraModeledWin_0001 m0 : 18|7@1+ (1,0) [0|100] "%" Vector__XXX
 SG_ VCRIGHT_AP_cameraModeledWindshie m0 : 25|7@1+ (1,0) [0|100] "%" Vector__XXX
 SG_ VCRIGHT_AP_maxAchievableASideTem m0 : 32|7@1+ (1,-20) [-20|70] "degC" Vector__XXX
 SG_ VCRIGHT_AP_cameraModeledPocketWa m0 : 42|10@1+ (0.04,0) [0|40] "g/kg" Vector__XXX
 SG_ VCRIGHT_AP_humidityModelInitStat m0 : 52|5@1+ (1,0) [0|31] "" Vector__XXX
 SG_ VCRIGHT_AP_humidityModelStatus m0 : 57|5@1+ (1,0) [0|31] "" Vector__XXX

BO_ 259 VCRIGHT_doorStatus: 8 VCRIGHT
 SG_ VCRIGHT_doorClosureStatusFront : 0|4@1+ (1,0) [1|15] "" Vector__XXX
 SG_ VCRIGHT_doorClosureStatusRear : 4|4@1+ (1,0) [1|15] "" Vector__XXX
 SG_ VCRIGHT_frontLatchSwitch : 8|1@1+ (1,0) [0|1] "" Vector__XXX
 SG_ VCRIGHT_rearLatchSwitch : 9|1@1+ (1,0) [0|1] "" Vector__XXX
 SG_ VCRIGHT_frontHandlePulled : 10|1@1+ (1,0) [0|1] "" Vector__XXX
 SG_ VCRIGHT_rearHandlePulled : 11|1@1+ (1,0) [0|1] "" Vector__XXX
 SG_ VCRIGHT_frontRelActuatorSwitch : 12|1@1+ (1,0) [0|1] "" Vector__XXX
 SG_ VCRIGHT_rearRelActuatorSwitch : 13|1@1+ (1,0) [0|1] "" Vector__XXX
 SG_ VCRIGHT_frontLatchStatus : 14|4@1+ (1,0) [1|15] "" Vector__XXX
 SG_ VCRIGHT_rearLatchStatus : 18|4@1+ (1,0) [1|15] "" Vector__XXX
 SG_ VCRIGHT_lastDoorReqSourceFront : 22|3@1+ (1,0) [0|7] "" Vector__XXX
 SG_ VCRIGHT_lastDoorReqSourceRear : 25|3@1+ (1,0) [0|7] "" Vector__XXX
 SG_ VCRIGHT_frontIntSwitchFaulted : 28|1@1+ (1,0) [0|1] "" Vector__XXX
 SG_ VCRIGHT_rearIntSwitchFaulted : 29|1@1+ (1,0) [0|1] "" Vector__XXX
 SG_ VCRIGHT_frontHandlePulledPersist : 30|1@1+ (1,0) [0|1] "" Vector__XXX
 SG_ VCRIGHT_frontIntSwitchPressed : 31|1@1+ (1,0) [0|1] "" Vector__XXX
 SG_ VCRIGHT_rearIntSwitchPressed : 32|1@1+ (1,0) [0|1] "" Vector__XXX
 SG_ VCRIGHT_mirrorTiltXPosition : 33|8@1+ (0.02,0) [0|5] "V" Vector__XXX
 SG_ VCRIGHT_mirrorTiltYPosition : 41|8@1+ (0.02,0) [0|5] "V" Vector__XXX
 SG_ VCRIGHT_mirrorState : 49|3@1+ (1,0) [0|7] "" Vector__XXX
 SG_ VCRIGHT_mirrorFoldState : 52|3@1+ (1,0) [0|7] "" Vector__XXX
 SG_ VCRIGHT_mirrorDipped : 55|1@1+ (1,0) [0|1] "" Vector__XXX
 SG_ VCRIGHT_trunkLatchStatus : 56|4@1+ (1,0) [1|15] "" Vector__XXX
 SG_ VCRIGHT_mirrorRecallState : 60|3@1+ (1,0) [0|7] "" Vector__XXX
 SG_ VCRIGHT_rearHandlePulledPersist : 63|1@1+ (1,0) [0|1] "" Vector__XXX

BO_ 611 VCRIGHT_epbmStatus: 8 VCRIGHT
 SG_ VCRIGHT_cdpRequestState : 0|1@1+ (1,0) [0|1] "" Vector__XXX
 SG_ VCRIGHT_epbmSystemStatusQF : 3|1@1+ (1,0) [0|1] "" Vector__XXX
 SG_ VCRIGHT_epbmUnitStatus : 4|5@1+ (1,0) [0|31] "" Vector__XXX
 SG_ VCRIGHT_epbmCdpState : 9|2@1+ (1,0) [0|3] "" Vector__XXX
 SG_ VCRIGHT_epbmRedundantBrakingEnab : 12|1@1+ (1,0) [0|1] "" Vector__XXX
 SG_ VCRIGHT_epbmStatusCounter : 52|4@1+ (1,0) [0|15] "" Vector__XXX
 SG_ VCRIGHT_epbmStatusChecksum : 56|8@1+ (1,0) [0|255] "" Vector__XXX

BO_ 794 VCRIGHT_restraintStatus: 8 VCRIGHT
 SG_ VCRIGHT_frontOccupancyStatus : 0|3@1+ (1,0) [0|6] "" Vector__XXX
 SG_ VCRIGHT_frontBuckleStatus : 3|2@1+ (1,0) [0|3] "" Vector__XXX
 SG_ VCRIGHT_rearCenterBuckleStatus : 5|2@1+ (1,0) [0|3] "" Vector__XXX
 SG_ VCRIGHT_rearRightBuckleStatus : 8|2@1+ (1,0) [0|3] "" Vector__XXX
 SG_ VCRIGHT_rearRightOccupancyStatus : 10|2@1+ (1,0) [0|3] "" Vector__XXX
 SG_ VCRIGHT_3RowLeftBuckleStatus : 12|2@1+ (1,0) [0|3] "" Vector__XXX
 SG_ VCRIGHT_3RowRightBuckleStatus : 14|2@1+ (1,0) [0|3] "" Vector__XXX
 SG_ VCRIGHT_3RowLeftOccupancyStatus : 16|2@1+ (1,0) [0|3] "" Vector__XXX
 SG_ VCRIGHT_3RowRightOccupancyStatus : 18|2@1+ (1,0) [0|3] "" Vector__XXX
 SG_ VCRIGHT_seatTrackPosition : 20|3@1+ (1,0) [0|6] "" Vector__XXX
 SG_ VCRIGHT_occupantClassification : 23|3@1+ (1,0) [0|6] "" Vector__XXX
 SG_ VCRIGHT_occupantClassificationQF : 26|1@1+ (1,0) [0|1] "" Vector__XXX
 SG_ VCRIGHT_classificationEnabled : 27|1@1+ (1,0) [0|1] "" Vector__XXX
 SG_ VCRIGHT_classificationEnabledQF : 28|1@1+ (1,0) [0|1] "" Vector__XXX
 SG_ VCRIGHT_3RowRightABStatus : 30|2@1+ (1,0) [0|3] "" Vector__XXX
 SG_ VCRIGHT_restraintStatusCounter : 52|4@1+ (1,0) [0|15] "" Vector__XXX
 SG_ VCRIGHT_restraintStatusChecksum : 56|8@1+ (1,0) [0|255] "" Vector__XXX

BO_TX_BU_ 1427 : EPASTP;
BO_TX_BU_ 919 : EPASTP;
BO_TX_BU_ 909 : ESP;
BO_TX_BU_ 325 : ESP;
BO_TX_BU_ 373 : ESP;
BO_TX_BU_ 925 : IBST;
BO_TX_BU_ 1316 : PMF;
BO_TX_BU_ 1364 : PMR;
BO_TX_BU_ 1973 : PM;
BO_TX_BU_ 2038 : PM;
BO_TX_BU_ 17 : RCM;
BO_TX_BU_ 289 : RCM;
BO_TX_BU_ 1618 : VCBATT0;
BO_TX_BU_ 1994 : VCCC;
BO_TX_BU_ 260 : VCFRONT;
BO_TX_BU_ 258 : VCLEFT;
BO_TX_BU_ 546 : VCLEFT;
BO_TX_BU_ 778 : VCLEFT;
BO_TX_BU_ 1124 : VCRIGHT;
BO_TX_BU_ 259 : VCRIGHT;
BO_TX_BU_ 611 : VCRIGHT;
BO_TX_BU_ 794 : VCRIGHT;
CM_ BO_ 1427 "EPASTP ECU message: alert log; frame length from the layout, not yet observed on a vehicle bus";
CM_ SG_ 1427 EPASTP_alertID "EPASTP ECU: alert ID";
CM_ SG_ 1427 EPASTP_alertState "EPASTP ECU: alert state";
CM_ SG_ 1427 EPASTP_a001_debugInfo "EPASTP ECU: a001 debug info";
CM_ SG_ 1427 EPASTP_a002_debugInfo "EPASTP ECU: a002 debug info";
CM_ SG_ 1427 EPASTP_a003_debugInfo "EPASTP ECU: a003 debug info";
CM_ SG_ 1427 EPASTP_a004_debugInfo "EPASTP ECU: a004 debug info";
CM_ SG_ 1427 EPASTP_a005_debugInfo "EPASTP ECU: a005 debug info";
CM_ SG_ 1427 EPASTP_a006_debugInfo "EPASTP ECU: a006 debug info";
CM_ SG_ 1427 EPASTP_a007_debugInfo "EPASTP ECU: a007 debug info";
CM_ SG_ 1427 EPASTP_a009_debugInfo "EPASTP ECU: a009 debug info";
CM_ SG_ 1427 EPASTP_a010_debugInfo "EPASTP ECU: a010 debug info";
CM_ SG_ 1427 EPASTP_a011_debugInfo "EPASTP ECU: a011 debug info";
CM_ SG_ 1427 EPASTP_a012_debugInfo "EPASTP ECU: a012 debug info";
CM_ SG_ 1427 EPASTP_a013_debugInfo "EPASTP ECU: a013 debug info";
CM_ SG_ 1427 EPASTP_a014_debugInfo "EPASTP ECU: a014 debug info";
CM_ SG_ 1427 EPASTP_a015_debugInfo "EPASTP ECU: a015 debug info";
CM_ SG_ 1427 EPASTP_a016_debugInfo "EPASTP ECU: a016 debug info";
CM_ SG_ 1427 EPASTP_a017_debugInfo "EPASTP ECU: a017 debug info";
CM_ SG_ 1427 EPASTP_a018_debugInfo "EPASTP ECU: a018 debug info";
CM_ SG_ 1427 EPASTP_a019_debugInfo "EPASTP ECU: a019 debug info";
CM_ SG_ 1427 EPASTP_a020_debugInfo "EPASTP ECU: a020 debug info";
CM_ SG_ 1427 EPASTP_a021_debugInfo "EPASTP ECU: a021 debug info";
CM_ SG_ 1427 EPASTP_a022_debugInfo "EPASTP ECU: a022 debug info";
CM_ SG_ 1427 EPASTP_a023_debugInfo "EPASTP ECU: a023 debug info";
CM_ SG_ 1427 EPASTP_a024_debugInfo "EPASTP ECU: a024 debug info";
CM_ SG_ 1427 EPASTP_a025_debugInfo "EPASTP ECU: a025 debug info";
CM_ SG_ 1427 EPASTP_a026_debugInfo "EPASTP ECU: a026 debug info";
CM_ SG_ 1427 EPASTP_a027_debugInfo "EPASTP ECU: a027 debug info";
CM_ SG_ 1427 EPASTP_a028_debugInfo "EPASTP ECU: a028 debug info";
CM_ SG_ 1427 EPASTP_a029_debugInfo "EPASTP ECU: a029 debug info";
CM_ SG_ 1427 EPASTP_a030_debugInfo "EPASTP ECU: a030 debug info";
CM_ SG_ 1427 EPASTP_a031_debugInfo "EPASTP ECU: a031 debug info";
CM_ SG_ 1427 EPASTP_a032_debugInfo "EPASTP ECU: a032 debug info";
CM_ SG_ 1427 EPASTP_a033_debugInfo "EPASTP ECU: a033 debug info";
CM_ SG_ 1427 EPASTP_a034_debugInfo "EPASTP ECU: a034 debug info";
CM_ SG_ 1427 EPASTP_a035_debugInfo "EPASTP ECU: a035 debug info";
CM_ SG_ 1427 EPASTP_a036_debugInfo "EPASTP ECU: a036 debug info";
CM_ SG_ 1427 EPASTP_a037_debugInfo "EPASTP ECU: a037 debug info";
CM_ SG_ 1427 EPASTP_a038_debugInfo "EPASTP ECU: a038 debug info";
CM_ SG_ 1427 EPASTP_a039_debugInfo "EPASTP ECU: a039 debug info";
CM_ SG_ 1427 EPASTP_a040_debugInfo "EPASTP ECU: a040 debug info";
CM_ SG_ 1427 EPASTP_a041_debugInfo "EPASTP ECU: a041 debug info";
CM_ SG_ 1427 EPASTP_a042_debugInfo "EPASTP ECU: a042 debug info";
CM_ SG_ 1427 EPASTP_a043_debugInfo "EPASTP ECU: a043 debug info";
CM_ SG_ 1427 EPASTP_a044_debugInfo "EPASTP ECU: a044 debug info";
CM_ SG_ 1427 EPASTP_a045_debugInfo "EPASTP ECU: a045 debug info";
CM_ SG_ 1427 EPASTP_a046_debugInfo "EPASTP ECU: a046 debug info";
CM_ SG_ 1427 EPASTP_a047_debugInfo "EPASTP ECU: a047 debug info";
CM_ SG_ 1427 EPASTP_a048_debugInfo "EPASTP ECU: a048 debug info";
CM_ SG_ 1427 EPASTP_a049_debugInfo "EPASTP ECU: a049 debug info";
CM_ SG_ 1427 EPASTP_a050_debugInfo "EPASTP ECU: a050 debug info";
CM_ SG_ 1427 EPASTP_a051_debugInfo "EPASTP ECU: a051 debug info";
CM_ SG_ 1427 EPASTP_a052_debugInfo "EPASTP ECU: a052 debug info";
CM_ SG_ 1427 EPASTP_a053_debugInfo "EPASTP ECU: a053 debug info";
CM_ SG_ 1427 EPASTP_a054_debugInfo "EPASTP ECU: a054 debug info";
CM_ SG_ 1427 EPASTP_a055_debugInfo "EPASTP ECU: a055 debug info";
CM_ SG_ 1427 EPASTP_a056_debugInfo "EPASTP ECU: a056 debug info";
CM_ SG_ 1427 EPASTP_a057_debugInfo "EPASTP ECU: a057 debug info";
CM_ SG_ 1427 EPASTP_a058_debugInfo "EPASTP ECU: a058 debug info";
CM_ SG_ 1427 EPASTP_a059_debugInfo "EPASTP ECU: a059 debug info";
CM_ SG_ 1427 EPASTP_a060_debugInfo "EPASTP ECU: a060 debug info";
CM_ SG_ 1427 EPASTP_a061_debugInfo "EPASTP ECU: a061 debug info";
CM_ SG_ 1427 EPASTP_a062_debugInfo "EPASTP ECU: a062 debug info";
CM_ SG_ 1427 EPASTP_a063_debugInfo "EPASTP ECU: a063 debug info";
CM_ SG_ 1427 EPASTP_a064_debugInfo "EPASTP ECU: a064 debug info";
CM_ SG_ 1427 EPASTP_a065_debugInfo "EPASTP ECU: a065 debug info";
CM_ SG_ 1427 EPASTP_a066_debugInfo "EPASTP ECU: a066 debug info";
CM_ SG_ 1427 EPASTP_a067_debugInfo "EPASTP ECU: a067 debug info";
CM_ SG_ 1427 EPASTP_a068_debugInfo "EPASTP ECU: a068 debug info";
CM_ SG_ 1427 EPASTP_a069_debugInfo "EPASTP ECU: a069 debug info";
CM_ SG_ 1427 EPASTP_a070_debugInfo "EPASTP ECU: a070 debug info";
CM_ SG_ 1427 EPASTP_a071_debugInfo "EPASTP ECU: a071 debug info";
CM_ SG_ 1427 EPASTP_a072_debugInfo "EPASTP ECU: a072 debug info";
CM_ SG_ 1427 EPASTP_a073_debugInfo "EPASTP ECU: a073 debug info";
CM_ SG_ 1427 EPASTP_a074_debugInfo "EPASTP ECU: a074 debug info";
CM_ SG_ 1427 EPASTP_a075_debugInfo "EPASTP ECU: a075 debug info";
CM_ SG_ 1427 EPASTP_a076_debugInfo "EPASTP ECU: a076 debug info";
CM_ SG_ 1427 EPASTP_a077_debugInfo "EPASTP ECU: a077 debug info";
CM_ SG_ 1427 EPASTP_a078_debugInfo "EPASTP ECU: a078 debug info";
CM_ SG_ 1427 EPASTP_a079_debugInfo "EPASTP ECU: a079 debug info";
CM_ SG_ 1427 EPASTP_a080_debugInfo "EPASTP ECU: a080 debug info";
CM_ SG_ 1427 EPASTP_a081_debugInfo "EPASTP ECU: a081 debug info";
CM_ SG_ 1427 EPASTP_a082_debugInfo "EPASTP ECU: a082 debug info";
CM_ SG_ 1427 EPASTP_a083_debugInfo "EPASTP ECU: a083 debug info";
CM_ SG_ 1427 EPASTP_a084_debugInfo "EPASTP ECU: a084 debug info";
CM_ SG_ 1427 EPASTP_a085_debugInfo "EPASTP ECU: a085 debug info";
CM_ SG_ 1427 EPASTP_a086_debugInfo "EPASTP ECU: a086 debug info";
CM_ SG_ 1427 EPASTP_a087_debugInfo "EPASTP ECU: a087 debug info";
CM_ SG_ 1427 EPASTP_a088_debugInfo "EPASTP ECU: a088 debug info";
CM_ SG_ 1427 EPASTP_a089_debugInfo "EPASTP ECU: a089 debug info";
CM_ SG_ 1427 EPASTP_a090_debugInfo "EPASTP ECU: a090 debug info";
CM_ SG_ 1427 EPASTP_a091_debugInfo "EPASTP ECU: a091 debug info";
CM_ SG_ 1427 EPASTP_a092_debugInfo "EPASTP ECU: a092 debug info";
CM_ SG_ 1427 EPASTP_a093_debugInfo "EPASTP ECU: a093 debug info";
CM_ SG_ 1427 EPASTP_a094_debugInfo "EPASTP ECU: a094 debug info";
CM_ SG_ 1427 EPASTP_a095_debugInfo "EPASTP ECU: a095 debug info";
CM_ SG_ 1427 EPASTP_a096_debugInfo "EPASTP ECU: a096 debug info";
CM_ SG_ 1427 EPASTP_a097_debugInfo "EPASTP ECU: a097 debug info";
CM_ SG_ 1427 EPASTP_a098_debugInfo "EPASTP ECU: a098 debug info";
CM_ SG_ 1427 EPASTP_a099_debugInfo "EPASTP ECU: a099 debug info";
CM_ SG_ 1427 EPASTP_a100_debugInfo "EPASTP ECU: a100 debug info";
CM_ SG_ 1427 EPASTP_a101_debugInfo "EPASTP ECU: a101 debug info";
CM_ SG_ 1427 EPASTP_a102_debugInfo "EPASTP ECU: a102 debug info";
CM_ SG_ 1427 EPASTP_a103_debugInfo "EPASTP ECU: a103 debug info";
CM_ SG_ 1427 EPASTP_a104_debugInfo "EPASTP ECU: a104 debug info";
CM_ SG_ 1427 EPASTP_a105_debugInfo "EPASTP ECU: a105 debug info";
CM_ SG_ 1427 EPASTP_a106_debugInfo "EPASTP ECU: a106 debug info";
CM_ SG_ 1427 EPASTP_a107_debugInfo "EPASTP ECU: a107 debug info";
CM_ SG_ 1427 EPASTP_a108_debugInfo "EPASTP ECU: a108 debug info";
CM_ SG_ 1427 EPASTP_a109_debugInfo "EPASTP ECU: a109 debug info";
CM_ SG_ 1427 EPASTP_a110_debugInfo "EPASTP ECU: a110 debug info";
CM_ SG_ 1427 EPASTP_a111_debugInfo "EPASTP ECU: a111 debug info";
CM_ SG_ 1427 EPASTP_a112_debugInfo "EPASTP ECU: a112 debug info";
CM_ SG_ 1427 EPASTP_a113_debugInfo "EPASTP ECU: a113 debug info";
CM_ SG_ 1427 EPASTP_a114_debugInfo "EPASTP ECU: a114 debug info";
CM_ SG_ 1427 EPASTP_a115_debugInfo "EPASTP ECU: a115 debug info";
CM_ SG_ 1427 EPASTP_a116_debugInfo "EPASTP ECU: a116 debug info";
CM_ SG_ 1427 EPASTP_a117_debugInfo "EPASTP ECU: a117 debug info";
CM_ SG_ 1427 EPASTP_a118_debugInfo "EPASTP ECU: a118 debug info";
CM_ SG_ 1427 EPASTP_a119_debugInfo "EPASTP ECU: a119 debug info";
CM_ SG_ 1427 EPASTP_a120_debugInfo "EPASTP ECU: a120 debug info";
CM_ SG_ 1427 EPASTP_a121_debugInfo "EPASTP ECU: a121 debug info";
CM_ SG_ 1427 EPASTP_a122_debugInfo "EPASTP ECU: a122 debug info";
CM_ SG_ 1427 EPASTP_a123_debugInfo "EPASTP ECU: a123 debug info";
CM_ SG_ 1427 EPASTP_a124_debugInfo "EPASTP ECU: a124 debug info";
CM_ SG_ 1427 EPASTP_a125_debugInfo "EPASTP ECU: a125 debug info";
CM_ SG_ 1427 EPASTP_a126_debugInfo "EPASTP ECU: a126 debug info";
CM_ SG_ 1427 EPASTP_a127_debugInfo "EPASTP ECU: a127 debug info";
CM_ SG_ 1427 EPASTP_a128_debugInfo "EPASTP ECU: a128 debug info";
CM_ SG_ 1427 EPASTP_a129_debugInfo "EPASTP ECU: a129 debug info";
CM_ SG_ 1427 EPASTP_a130_debugInfo "EPASTP ECU: a130 debug info";
CM_ SG_ 1427 EPASTP_a131_debugInfo "EPASTP ECU: a131 debug info";
CM_ SG_ 1427 EPASTP_a132_debugInfo "EPASTP ECU: a132 debug info";
CM_ SG_ 1427 EPASTP_a133_debugInfo "EPASTP ECU: a133 debug info";
CM_ SG_ 1427 EPASTP_a134_debugInfo "EPASTP ECU: a134 debug info";
CM_ SG_ 1427 EPASTP_a135_debugInfo "EPASTP ECU: a135 debug info";
CM_ SG_ 1427 EPASTP_a136_debugInfo "EPASTP ECU: a136 debug info";
CM_ SG_ 1427 EPASTP_a137_debugInfo "EPASTP ECU: a137 debug info";
CM_ SG_ 1427 EPASTP_a138_debugInfo "EPASTP ECU: a138 debug info";
CM_ SG_ 1427 EPASTP_a139_debugInfo "EPASTP ECU: a139 debug info";
CM_ SG_ 1427 EPASTP_a140_debugInfo "EPASTP ECU: a140 debug info";
CM_ SG_ 1427 EPASTP_a141_debugInfo "EPASTP ECU: a141 debug info";
CM_ SG_ 1427 EPASTP_a142_debugInfo "EPASTP ECU: a142 debug info";
CM_ SG_ 1427 EPASTP_a143_debugInfo "EPASTP ECU: a143 debug info";
CM_ SG_ 1427 EPASTP_a144_debugInfo "EPASTP ECU: a144 debug info";
CM_ SG_ 1427 EPASTP_a145_debugInfo "EPASTP ECU: a145 debug info";
CM_ SG_ 1427 EPASTP_a146_debugInfo "EPASTP ECU: a146 debug info";
CM_ SG_ 1427 EPASTP_a147_debugInfo "EPASTP ECU: a147 debug info";
CM_ SG_ 1427 EPASTP_a148_debugInfo "EPASTP ECU: a148 debug info";
CM_ SG_ 1427 EPASTP_a149_debugInfo "EPASTP ECU: a149 debug info";
CM_ SG_ 1427 EPASTP_a150_debugInfo "EPASTP ECU: a150 debug info";
CM_ SG_ 1427 EPASTP_a152_debugInfo "EPASTP ECU: a152 debug info";
CM_ SG_ 1427 EPASTP_a153_debugInfo "EPASTP ECU: a153 debug info";
CM_ SG_ 1427 EPASTP_a154_debugInfo "EPASTP ECU: a154 debug info";
CM_ SG_ 1427 EPASTP_a155_debugInfo "EPASTP ECU: a155 debug info";
CM_ SG_ 1427 EPASTP_a156_debugInfo "EPASTP ECU: a156 debug info";
CM_ SG_ 1427 EPASTP_a157_debugInfo "EPASTP ECU: a157 debug info";
CM_ SG_ 1427 EPASTP_a158_debugInfo "EPASTP ECU: a158 debug info";
CM_ SG_ 1427 EPASTP_a159_debugInfo "EPASTP ECU: a159 debug info";
CM_ SG_ 1427 EPASTP_a160_debugInfo "EPASTP ECU: a160 debug info";
CM_ SG_ 1427 EPASTP_a161_debugInfo "EPASTP ECU: a161 debug info";
CM_ SG_ 1427 EPASTP_a162_debugInfo "EPASTP ECU: a162 debug info";
CM_ SG_ 1427 EPASTP_a163_debugInfo "EPASTP ECU: a163 debug info";
CM_ SG_ 1427 EPASTP_a164_debugInfo "EPASTP ECU: a164 debug info";
CM_ SG_ 1427 EPASTP_a165_debugInfo "EPASTP ECU: a165 debug info";
CM_ SG_ 1427 EPASTP_a166_debugInfo "EPASTP ECU: a166 debug info";
CM_ SG_ 1427 EPASTP_a167_debugInfo "EPASTP ECU: a167 debug info";
CM_ SG_ 1427 EPASTP_a168_debugInfo "EPASTP ECU: a168 debug info";
CM_ SG_ 1427 EPASTP_a169_debugInfo "EPASTP ECU: a169 debug info";
CM_ SG_ 1427 EPASTP_a170_debugInfo "EPASTP ECU: a170 debug info";
CM_ SG_ 1427 EPASTP_a171_debugInfo "EPASTP ECU: a171 debug info";
CM_ SG_ 1427 EPASTP_a172_debugInfo "EPASTP ECU: a172 debug info";
CM_ SG_ 1427 EPASTP_a173_debugInfo "EPASTP ECU: a173 debug info";
CM_ SG_ 1427 EPASTP_a174_debugInfo "EPASTP ECU: a174 debug info";
CM_ SG_ 1427 EPASTP_a175_debugInfo "EPASTP ECU: a175 debug info";
CM_ SG_ 1427 EPASTP_a176_debugInfo "EPASTP ECU: a176 debug info";
CM_ SG_ 1427 EPASTP_a177_debugInfo "EPASTP ECU: a177 debug info";
CM_ SG_ 1427 EPASTP_a178_debugInfo "EPASTP ECU: a178 debug info";
CM_ SG_ 1427 EPASTP_a179_debugInfo "EPASTP ECU: a179 debug info";
CM_ SG_ 1427 EPASTP_a180_debugInfo "EPASTP ECU: a180 debug info";
CM_ SG_ 1427 EPASTP_a181_debugInfo "EPASTP ECU: a181 debug info";
CM_ SG_ 1427 EPASTP_a182_debugInfo "EPASTP ECU: a182 debug info";
CM_ SG_ 1427 EPASTP_a183_debugInfo "EPASTP ECU: a183 debug info";
CM_ SG_ 1427 EPASTP_a184_debugInfo "EPASTP ECU: a184 debug info";
CM_ SG_ 1427 EPASTP_a185_debugInfo "EPASTP ECU: a185 debug info";
CM_ SG_ 1427 EPASTP_a186_debugInfo "EPASTP ECU: a186 debug info";
CM_ SG_ 1427 EPASTP_a188_debugInfo "EPASTP ECU: a188 debug info";
CM_ SG_ 1427 EPASTP_a189_debugInfo "EPASTP ECU: a189 debug info";
CM_ SG_ 1427 EPASTP_a190_debugInfo "EPASTP ECU: a190 debug info";
CM_ SG_ 1427 EPASTP_a191_debugInfo "EPASTP ECU: a191 debug info";
CM_ SG_ 1427 EPASTP_a192_debugInfo "EPASTP ECU: a192 debug info";
CM_ SG_ 1427 EPASTP_a193_debugInfo "EPASTP ECU: a193 debug info";
CM_ SG_ 1427 EPASTP_a194_debugInfo "EPASTP ECU: a194 debug info";
CM_ SG_ 1427 EPASTP_a195_debugInfo "EPASTP ECU: a195 debug info";
CM_ SG_ 1427 EPASTP_a196_debugInfo "EPASTP ECU: a196 debug info";
CM_ SG_ 1427 EPASTP_a197_debugInfo "EPASTP ECU: a197 debug info";
CM_ SG_ 1427 EPASTP_a198_debugInfo "EPASTP ECU: a198 debug info";
CM_ SG_ 1427 EPASTP_a199_debugInfo "EPASTP ECU: a199 debug info";
CM_ SG_ 1427 EPASTP_a200_debugInfo "EPASTP ECU: a200 debug info";
CM_ SG_ 1427 EPASTP_a201_debugInfo "EPASTP ECU: a201 debug info";
CM_ SG_ 1427 EPASTP_a202_debugInfo "EPASTP ECU: a202 debug info";
CM_ SG_ 1427 EPASTP_a203_debugInfo "EPASTP ECU: a203 debug info";
CM_ SG_ 1427 EPASTP_a204_debugInfo "EPASTP ECU: a204 debug info";
CM_ SG_ 1427 EPASTP_a205_debugInfo "EPASTP ECU: a205 debug info";
CM_ SG_ 1427 EPASTP_a206_debugInfo "EPASTP ECU: a206 debug info";
CM_ SG_ 1427 EPASTP_a207_debugInfo "EPASTP ECU: a207 debug info";
CM_ SG_ 1427 EPASTP_a208_debugInfo "EPASTP ECU: a208 debug info";
CM_ SG_ 1427 EPASTP_a209_debugInfo "EPASTP ECU: a209 debug info";
CM_ SG_ 1427 EPASTP_a210_debugInfo "EPASTP ECU: a210 debug info";
CM_ SG_ 1427 EPASTP_a211_debugInfo "EPASTP ECU: a211 debug info";
CM_ SG_ 1427 EPASTP_a212_debugInfo "EPASTP ECU: a212 debug info";
CM_ SG_ 1427 EPASTP_a213_debugInfo "EPASTP ECU: a213 debug info";
CM_ SG_ 1427 EPASTP_a214_debugInfo "EPASTP ECU: a214 debug info";
CM_ SG_ 1427 EPASTP_a215_debugInfo "EPASTP ECU: a215 debug info";
CM_ SG_ 1427 EPASTP_a216_debugInfo "EPASTP ECU: a216 debug info";
CM_ SG_ 1427 EPASTP_a217_debugInfo "EPASTP ECU: a217 debug info";
CM_ SG_ 1427 EPASTP_a218_debugInfo "EPASTP ECU: a218 debug info";
CM_ SG_ 1427 EPASTP_a219_debugInfo "EPASTP ECU: a219 debug info";
CM_ SG_ 1427 EPASTP_a221_debugInfo "EPASTP ECU: a221 debug info";
CM_ SG_ 1427 EPASTP_a222_debugInfo "EPASTP ECU: a222 debug info";
CM_ SG_ 1427 EPASTP_a223_debugInfo "EPASTP ECU: a223 debug info";
CM_ SG_ 1427 EPASTP_a224_debugInfo "EPASTP ECU: a224 debug info";
CM_ SG_ 1427 EPASTP_a225_debugInfo "EPASTP ECU: a225 debug info";
CM_ SG_ 1427 EPASTP_a226_debugInfo "EPASTP ECU: a226 debug info";
CM_ SG_ 1427 EPASTP_a227_debugInfo "EPASTP ECU: a227 debug info";
CM_ SG_ 1427 EPASTP_a228_debugInfo "EPASTP ECU: a228 debug info";
CM_ SG_ 1427 EPASTP_a229_debugInfo "EPASTP ECU: a229 debug info";
CM_ SG_ 1427 EPASTP_a230_debugInfo "EPASTP ECU: a230 debug info";
CM_ SG_ 1427 EPASTP_a231_debugInfo "EPASTP ECU: a231 debug info";
CM_ SG_ 1427 EPASTP_a232_debugInfo "EPASTP ECU: a232 debug info";
CM_ SG_ 1427 EPASTP_a233_debugInfo "EPASTP ECU: a233 debug info";
CM_ SG_ 1427 EPASTP_a234_debugInfo "EPASTP ECU: a234 debug info";
CM_ SG_ 1427 EPASTP_a235_debugInfo "EPASTP ECU: a235 debug info";
CM_ SG_ 1427 EPASTP_a236_debugInfo "EPASTP ECU: a236 debug info";
CM_ SG_ 1427 EPASTP_a237_debugInfo "EPASTP ECU: a237 debug info";
CM_ SG_ 1427 EPASTP_a238_debugInfo "EPASTP ECU: a238 debug info";
CM_ SG_ 1427 EPASTP_a239_debugInfo "EPASTP ECU: a239 debug info";
CM_ SG_ 1427 EPASTP_a240_debugInfo "EPASTP ECU: a240 debug info";
CM_ SG_ 1427 EPASTP_a241_debugInfo "EPASTP ECU: a241 debug info";
CM_ SG_ 1427 EPASTP_a242_debugInfo "EPASTP ECU: a242 debug info";
CM_ SG_ 1427 EPASTP_a243_debugInfo "EPASTP ECU: a243 debug info";
CM_ SG_ 1427 EPASTP_a244_debugInfo "EPASTP ECU: a244 debug info";
CM_ SG_ 1427 EPASTP_a245_debugInfo "EPASTP ECU: a245 debug info";
CM_ SG_ 1427 EPASTP_a246_debugInfo "EPASTP ECU: a246 debug info";
CM_ SG_ 1427 EPASTP_a247_debugInfo "EPASTP ECU: a247 debug info";
CM_ SG_ 1427 EPASTP_a248_debugInfo "EPASTP ECU: a248 debug info";
CM_ SG_ 1427 EPASTP_a249_debugInfo "EPASTP ECU: a249 debug info";
CM_ SG_ 1427 EPASTP_a250_debugInfo "EPASTP ECU: a250 debug info";
CM_ SG_ 1427 EPASTP_a252_debugInfo "EPASTP ECU: a252 debug info";
CM_ SG_ 1427 EPASTP_a253_debugInfo "EPASTP ECU: a253 debug info";
CM_ SG_ 1427 EPASTP_a254_debugInfo "EPASTP ECU: a254 debug info";
CM_ SG_ 1427 EPASTP_a255_debugInfo "EPASTP ECU: a255 debug info";
CM_ SG_ 1427 EPASTP_a256_debugInfo "EPASTP ECU: a256 debug info";
CM_ SG_ 1427 EPASTP_a257_debugInfo "EPASTP ECU: a257 debug info";
CM_ SG_ 1427 EPASTP_a258_debugInfo "EPASTP ECU: a258 debug info";
CM_ SG_ 1427 EPASTP_a259_debugInfo "EPASTP ECU: a259 debug info";
CM_ SG_ 1427 EPASTP_a260_debugInfo "EPASTP ECU: a260 debug info";
CM_ SG_ 1427 EPASTP_a261_debugInfo "EPASTP ECU: a261 debug info";
CM_ SG_ 1427 EPASTP_a262_debugInfo "EPASTP ECU: a262 debug info";
CM_ SG_ 1427 EPASTP_a263_debugInfo "EPASTP ECU: a263 debug info";
CM_ SG_ 1427 EPASTP_a264_degradedECU "EPASTP ECU: a264 degraded ECU";
CM_ SG_ 1427 EPASTP_a264_vehicleSpeed "EPASTP ECU: a264 vehicle speed";
CM_ SG_ 1427 EPASTP_a264_powerRatio "EPASTP ECU: a264 power ratio";
CM_ SG_ 1427 EPASTP_a264_ownSideDegradationRe "EPASTP ECU: a264 own side degradation reason";
CM_ SG_ 1427 EPASTP_a264_otherSideDegradation "EPASTP ECU: a264 other side degradation reason";
CM_ SG_ 1427 EPASTP_a265_degradedECU "EPASTP ECU: a265 degraded ECU";
CM_ SG_ 1427 EPASTP_a265_vehicleSpeed "EPASTP ECU: a265 vehicle speed";
CM_ SG_ 1427 EPASTP_a265_rawMcuTemperature "EPASTP ECU: a265 raw mcu temperature";
CM_ SG_ 1427 EPASTP_a265_degradedCurrentLimit "EPASTP ECU: a265 degraded current limit";
CM_ SG_ 1427 EPASTP_a266_cdpAssistFactor "EPASTP ECU: a266 cdp assist factor";
CM_ SG_ 1427 EPASTP_a266_vehicleSpeed "EPASTP ECU: a266 vehicle speed";
CM_ SG_ 1427 EPASTP_a267_vehicleSpeed "EPASTP ECU: a267 vehicle speed";
CM_ SG_ 1427 EPASTP_a267_velocityEstimatorSta "EPASTP ECU: a267 velocity estimator state";
CM_ SG_ 1427 EPASTP_a269_vehicleSpeed "EPASTP ECU: a269 vehicle speed";
CM_ SG_ 1427 EPASTP_a270_debugInfo "EPASTP ECU: a270 debug info";
CM_ BO_ 919 "EPASTP ECU message: alert matrix; frame length from the layout, not yet observed on a vehicle bus";
CM_ SG_ 919 EPASTP_matrixIndex "EPASTP ECU: matrix index";
CM_ SG_ 919 EPASTP_a001_adcCalibrationOrInit "EPASTP ECU: a001 adc calibration or init fail";
CM_ SG_ 919 EPASTP_a002_adcMuxErr "EPASTP ECU: a002 adc mux err";
CM_ SG_ 919 EPASTP_a003_pspInvalidParamset "EPASTP ECU: a003 psp invalid paramset";
CM_ SG_ 919 EPASTP_a004_scpInputMia "EPASTP ECU: a004 scp input mia";
CM_ SG_ 919 EPASTP_a005_scpUnknownResetSourc "EPASTP ECU: a005 scp unknown reset source";
CM_ SG_ 919 EPASTP_a006_swrhResetByInvalidEr "EPASTP ECU: a006 swrh reset by invalid errid";
CM_ SG_ 919 EPASTP_a007_tsmcCoreTempDiff "EPASTP ECU: a007 tsmc core temp diff";
CM_ SG_ 919 EPASTP_a008_psdcPlatformShutdown "EPASTP ECU: a008 psdc platform shutdown";
CM_ SG_ 919 EPASTP_a009_mcusscLbistPermanent "EPASTP ECU: a009 mcussc lbist permanent fail";
CM_ SG_ 919 EPASTP_a010_svcIncompatibleSwVer "EPASTP ECU: a010 svc incompatible sw versions";
CM_ SG_ 919 EPASTP_a011_mcusscMonbistErr "EPASTP ECU: a011 mcussc monbist err";
CM_ SG_ 919 EPASTP_a012_mcusscMbistEccErr "EPASTP ECU: a012 mcussc mbist ecc err";
CM_ SG_ 919 EPASTP_a013_mcusscSffMonitoringF "EPASTP ECU: a013 mcussc sff monitoring failed";
CM_ SG_ 919 EPASTP_a014_mcusscSffMonitoringM "EPASTP ECU: a014 mcussc sff monitoring mia";
CM_ SG_ 919 EPASTP_a015_mcusscCsErrorCheckFa "EPASTP ECU: a015 mcussc cs error check fail";
CM_ SG_ 919 EPASTP_a016_mcufcCsErrorCheckFai "EPASTP ECU: a016 mcufc cs error check fail";
CM_ SG_ 919 EPASTP_a017_stmdStmPlausibilityC "EPASTP ECU: a017 stmd stm plausibility check err";
CM_ SG_ 919 EPASTP_a018_exchCsErrorCheck "EPASTP ECU: a018 exch cs error check";
CM_ SG_ 919 EPASTP_a019_rsthHwResetInfoCorru "EPASTP ECU: a019 rsth hw reset info corruption check";
CM_ SG_ 919 EPASTP_a020_mcusscEolEcuIdIntegr "EPASTP ECU: a020 mcussc eol ecu id integritiy fail";
CM_ SG_ 919 EPASTP_a021_osehCsErrorCheck "EPASTP ECU: a021 oseh cs error check";
CM_ SG_ 919 EPASTP_a022_swrhSwResetInfoCorru "EPASTP ECU: a022 swrh sw reset info corruption check";
CM_ SG_ 919 EPASTP_a023_btarcCorruptionCheck "EPASTP ECU: a023 btarc corruption check";
CM_ SG_ 919 EPASTP_a024_srhCsErrorCheckFail "EPASTP ECU: a024 srh cs error check fail";
CM_ SG_ 919 EPASTP_a025_btarcCorruptionCheck "EPASTP ECU: a025 btarc corruption check";
CM_ SG_ 919 EPASTP_a026_mrccCsErrorCheckFail "EPASTP ECU: a026 mrcc cs error check fail";
CM_ SG_ 919 EPASTP_a027_mcusscDmuHfErr "EPASTP ECU: a027 mcussc dmu hf err";
CM_ SG_ 919 EPASTP_a028_smuhNonInitDataCorru "EPASTP ECU: a028 smuh non init data corruption";
CM_ SG_ 919 EPASTP_a029_smuhSmuCoreCntErrorT "EPASTP ECU: a029 smuh smu core cnt error test fail";
CM_ SG_ 919 EPASTP_a030_rsthClockReset "EPASTP ECU: a030 rsth clock reset";
CM_ SG_ 919 EPASTP_a031_pmsProductionModeFai "EPASTP ECU: a031 pms production mode failed";
CM_ SG_ 919 EPASTP_a032_eolpEolCheckFailed "EPASTP ECU: a032 eolp eol check failed";
CM_ SG_ 919 EPASTP_a033_icsvcPswVersionMisma "EPASTP ECU: a033 icsvc psw version mismatch";
CM_ SG_ 919 EPASTP_a034_sbchReadbackRegFail "EPASTP ECU: a034 sbch readback reg fail";
CM_ SG_ 919 EPASTP_a035_sbchChipIdFail "EPASTP ECU: a035 sbch chip id fail";
CM_ SG_ 919 EPASTP_a036_sbcmSbcBistFailed "EPASTP ECU: a036 sbcm sbc bist failed";
CM_ SG_ 919 EPASTP_a037_epmV5P2Fail "EPASTP ECU: a037 epm V5 P2 fail";
CM_ SG_ 919 EPASTP_a038_csohCh1CsErrorErrAtR "EPASTP ECU: a038 csoh ch1 cs error err at reset";
CM_ SG_ 919 EPASTP_a039_csohCh2CsErrorErrAtR "EPASTP ECU: a039 csoh ch2 cs error err at reset";
CM_ SG_ 919 EPASTP_a040_swrhLimitedResetRetr "EPASTP ECU: a040 swrh limited reset retries expired";
CM_ SG_ 919 EPASTP_a041_imcmCoreConfiguratio "EPASTP ECU: a041 imcm core configuration mismatch";
CM_ SG_ 919 EPASTP_a042_wdhWdTestFail "EPASTP ECU: a042 wdh wd test fail";
CM_ SG_ 919 EPASTP_a043_sbcmWdStateDisabled "EPASTP ECU: a043 sbcm wd state disabled";
CM_ SG_ 919 EPASTP_a044_sbcmSbcEepromFail "EPASTP ECU: a044 sbcm sbc eeprom fail";
CM_ SG_ 919 EPASTP_a045_psumSbcBandgapVoltEr "EPASTP ECU: a045 psum sbc bandgap volt err";
CM_ SG_ 919 EPASTP_a046_mcusscOscillatorNotR "EPASTP ECU: a046 mcussc oscillator not reliable";
CM_ SG_ 919 EPASTP_a047_epmVregVoltFail "EPASTP ECU: a047 epm vreg volt fail";
CM_ SG_ 919 EPASTP_a048_epmVcpVoltFail "EPASTP ECU: a048 epm vcp volt fail";
CM_ SG_ 919 EPASTP_a049_epmLgFail "EPASTP ECU: a049 epm lg fail";
CM_ SG_ 919 EPASTP_a050_erlErr "EPASTP ECU: a050 erl err";
CM_ SG_ 919 EPASTP_a051_ermMessageErr "EPASTP ECU: a051 erm message err";
CM_ SG_ 919 EPASTP_a052_ermSdcInputBufferOve "EPASTP ECU: a052 erm sdc input buffer overflow";
CM_ SG_ 919 EPASTP_a053_adcUnexpectedNumOfDa "EPASTP ECU: a053 adc unexpected num of data";
CM_ SG_ 919 EPASTP_a054_adcUnexpectedData "EPASTP ECU: a054 adc unexpected data";
CM_ SG_ 919 EPASTP_a055_amExtendedGduTest "EPASTP ECU: a055 am extended gdu test";
CM_ SG_ 919 EPASTP_a056_amGduConfigCsErrorCh "EPASTP ECU: a056 am gdu config cs error check";
CM_ SG_ 919 EPASTP_a057_amGduVds "EPASTP ECU: a057 am gdu vds";
CM_ SG_ 919 EPASTP_a058_amIntVgsUndervtgErr "EPASTP ECU: a058 am int vgs undervtg err";
CM_ SG_ 919 EPASTP_a059_amStartupTestFailed "EPASTP ECU: a059 am startup test failed";
CM_ SG_ 919 EPASTP_a060_amGduFail "EPASTP ECU: a060 am gdu fail";
CM_ SG_ 919 EPASTP_a061_amIntSerialErr "EPASTP ECU: a061 am int serial err";
CM_ SG_ 919 EPASTP_a062_amPhaseBridgeCheck "EPASTP ECU: a062 am phase bridge check";
CM_ SG_ 919 EPASTP_a063_amIntRegulatorErr "EPASTP ECU: a063 am int regulator err";
CM_ SG_ 919 EPASTP_a064_amBridgeShort "EPASTP ECU: a064 am bridge short";
CM_ SG_ 919 EPASTP_a065_amGduJuncTemp "EPASTP ECU: a065 am gdu junc temp";
CM_ SG_ 919 EPASTP_a066_amVoltQfErr "EPASTP ECU: a066 am volt qf err";
CM_ SG_ 919 EPASTP_a067_tspmPowermoduleTempI "EPASTP ECU: a067 tspm powermodule temp implausible";
CM_ SG_ 919 EPASTP_a068_rsthCoreRedundancyEr "EPASTP ECU: a068 rsth core redundancy err";
CM_ SG_ 919 EPASTP_a069_rsthCoreTempOutOfRan "EPASTP ECU: a069 rsth core temp out of range hw check";
CM_ SG_ 919 EPASTP_a070_rsthInternalLowVolt "EPASTP ECU: a070 rsth internal low volt";
CM_ SG_ 919 EPASTP_a071_rsthInternalHighVolt "EPASTP ECU: a071 rsth internal high volt";
CM_ SG_ 919 EPASTP_a072_rsthFlashUncorrEccOr "EPASTP ECU: a072 rsth flash uncorr ecc or ovfl";
CM_ SG_ 919 EPASTP_a073_rsthOtherEdcEcc "EPASTP ECU: a073 rsth other edc ecc";
CM_ SG_ 919 EPASTP_a074_rsthUnexpectedAlarm "EPASTP ECU: a074 rsth unexpected alarm";
CM_ SG_ 919 EPASTP_a075_rsthUnusedOtherModul "EPASTP ECU: a075 rsth unused other module alarm";
CM_ SG_ 919 EPASTP_a076_exchGeneralException "EPASTP ECU: a076 exch general exception";
CM_ SG_ 919 EPASTP_a077_dmDeadlineViolation "EPASTP ECU: a077 dm deadline violation";
CM_ SG_ 919 EPASTP_a078_dmDeadlineViolation "EPASTP ECU: a078 dm deadline violation";
CM_ SG_ 919 EPASTP_a079_gduhComErr "EPASTP ECU: a079 gduh com err";
CM_ SG_ 919 EPASTP_a080_pwmTimerSyncCheck "EPASTP ECU: a080 pwm timer sync check";
CM_ SG_ 919 EPASTP_a081_exchFloatingPointExc "EPASTP ECU: a081 exch floating point exception";
CM_ SG_ 919 EPASTP_a082_adcTriggerTimeChk "EPASTP ECU: a082 adc trigger time chk";
CM_ SG_ 919 EPASTP_a083_tdaDclinkcapacitorTe "EPASTP ECU: a083 tda dclinkcapacitor temp checker";
CM_ SG_ 919 EPASTP_a084_adcTriggerCheck "EPASTP ECU: a084 adc trigger check";
CM_ SG_ 919 EPASTP_a085_amGduSwitchOffTestBy "EPASTP ECU: a085 am gdu switch off test by mcu";
CM_ SG_ 919 EPASTP_a086_rsthRamUncorrEcc "EPASTP ECU: a086 rsth ram uncorr ecc";
CM_ SG_ 919 EPASTP_a087_rsthFlashConfigErr "EPASTP ECU: a087 rsth flash config err";
CM_ SG_ 919 EPASTP_a088_tedMainboardTempChec "EPASTP ECU: a088 ted mainboard temp checker";
CM_ SG_ 919 EPASTP_a089_tedRevercebattfetjun "EPASTP ECU: a089 ted revercebattfetjunction temp checker";
CM_ SG_ 919 EPASTP_a090_etsmWarning "EPASTP ECU: a090 etsm warning";
CM_ SG_ 919 EPASTP_a091_bvpBattVoltCrossChkF "EPASTP ECU: a091 bvp batt volt cross chk failed";
CM_ SG_ 919 EPASTP_a092_amGduSwitchOffTestBy "EPASTP ECU: a092 am gdu switch off test by sbc";
CM_ SG_ 919 EPASTP_a093_sctpTsuSingleStaticF "EPASTP ECU: a093 sctp tsu single static fail";
CM_ SG_ 919 EPASTP_a094_sctpTsuMultipleStati "EPASTP ECU: a094 sctp tsu multiple static fail";
CM_ SG_ 919 EPASTP_a095_mdModelBasedMotorInt "EPASTP ECU: a095 md model based motor integrity check";
CM_ SG_ 919 EPASTP_a096_rppRpsSingleStaticFa "EPASTP ECU: a096 rpp rps single static fail";
CM_ SG_ 919 EPASTP_a097_rppRpsMultipleStatic "EPASTP ECU: a097 rpp rps multiple static fail";
CM_ SG_ 919 EPASTP_a098_invErr "EPASTP ECU: a098 inv err";
CM_ SG_ 919 EPASTP_a099_mcdTorqueMismatchFau "EPASTP ECU: a099 mcd torque mismatch fault";
CM_ SG_ 919 EPASTP_a100_amVbrgLssFault "EPASTP ECU: a100 am vbrg lss fault";
CM_ SG_ 919 EPASTP_a101_sdrvSpcIdMismatch "EPASTP ECU: a101 sdrv spc id mismatch";
CM_ SG_ 919 EPASTP_a102_amPhasecurrentQosErr "EPASTP ECU: a102 am phasecurrent qos err";
CM_ SG_ 919 EPASTP_a103_exhaUnusedInterruptC "EPASTP ECU: a103 exha unused interrupt call exception";
CM_ SG_ 919 EPASTP_a104_exhaBusMpuException "EPASTP ECU: a104 exha bus mpu exception";
CM_ SG_ 919 EPASTP_a105_exhaSriBusErrExcepti "EPASTP ECU: a105 exha sri bus err exception";
CM_ SG_ 919 EPASTP_a106_exhaSpbBusErrExcepti "EPASTP ECU: a106 exha spb bus err exception";
CM_ SG_ 919 EPASTP_a107_exhaOtherNmiExceptio "EPASTP ECU: a107 exha other nmi exception";
CM_ SG_ 919 EPASTP_a108_exhaInternalProtecti "EPASTP ECU: a108 exha internal protection exception";
CM_ SG_ 919 EPASTP_a109_exhaSysBusOrPeriphEr "EPASTP ECU: a109 exha sys bus or periph err exception";
CM_ SG_ 919 EPASTP_a110_amPhaseRelaySwitchOf "EPASTP ECU: a110 am phase relay switch off test";
CM_ SG_ 919 EPASTP_a111_amCurrentSensingDisc "EPASTP ECU: a111 am current sensing disconnection";
CM_ SG_ 919 EPASTP_a112_rsthSafetyFlipflopEr "EPASTP ECU: a112 rsth safety flipflop err";
CM_ SG_ 919 EPASTP_a113_rsthUncorrectableEnd "EPASTP ECU: a113 rsth uncorrectable end to end bus err";
CM_ SG_ 919 EPASTP_a114_osehOsErr "EPASTP ECU: a114 oseh os err";
CM_ SG_ 919 EPASTP_a115_mcusscLbistSingleFai "EPASTP ECU: a115 mcussc lbist single fail";
CM_ SG_ 919 EPASTP_a116_mrccStartupRegCsErro "EPASTP ECU: a116 mrcc startup reg cs error static err";
CM_ SG_ 919 EPASTP_a117_mrccStartupRegCsErro "EPASTP ECU: a117 mrcc startup reg cs error transient err";
CM_ SG_ 919 EPASTP_a118_mcusscFlashCsErrorEr "EPASTP ECU: a118 mcussc flash cs error err";
CM_ SG_ 919 EPASTP_a119_mcusscFlashEccCritic "EPASTP ECU: a119 mcussc flash ecc critical err";
CM_ SG_ 919 EPASTP_a120_mcusscFlashEccLatent "EPASTP ECU: a120 mcussc flash ecc latent err";
CM_ SG_ 919 EPASTP_a121_mcusscMbistEccErr "EPASTP ECU: a121 mcussc mbist ecc err";
CM_ SG_ 919 EPASTP_a122_pcpBridgeFetShort "EPASTP ECU: a122 pcp bridge fet short";
CM_ SG_ 919 EPASTP_a123_imcmCommErr "EPASTP ECU: a123 imcm comm err";
CM_ SG_ 919 EPASTP_a124_mcusscMbistEccTransi "EPASTP ECU: a124 mcussc mbist ecc transient err";
CM_ SG_ 919 EPASTP_a125_mcusscMbistMiaErr "EPASTP ECU: a125 mcussc mbist mia err";
CM_ SG_ 919 EPASTP_a126_mcusscMonbistMiaErr "EPASTP ECU: a126 mcussc monbist mia err";
CM_ SG_ 919 EPASTP_a127_exchAdditionalExcept "EPASTP ECU: a127 exch additional exception after rst";
CM_ SG_ 919 EPASTP_a128_exchExceptionStopRes "EPASTP ECU: a128 exch exception stop restart";
CM_ SG_ 919 EPASTP_a129_exchAdditionalExcept "EPASTP ECU: a129 exch additional exception stop restart";
CM_ SG_ 919 EPASTP_a130_mrccConfigCsErrorErr "EPASTP ECU: a130 mrcc config cs error err";
CM_ SG_ 919 EPASTP_a131_exchGuardedResetAfte "EPASTP ECU: a131 exch guarded reset after partition stop";
CM_ SG_ 919 EPASTP_a132_mcusscNotSupportedMc "EPASTP ECU: a132 mcussc not supported mcu";
CM_ SG_ 919 EPASTP_a133_mcusscLbistEcuIdIsNo "EPASTP ECU: a133 mcussc lbist ecu id is not supported";
CM_ SG_ 919 EPASTP_a134_osehGuardedResetAfte "EPASTP ECU: a134 oseh guarded reset after err without reset";
CM_ SG_ 919 EPASTP_a135_tmpsfetjCalculationO "EPASTP ECU: a135 tmpsfetj calculation overflow err";
CM_ SG_ 919 EPASTP_a136_ftElectricalAngleQf "EPASTP ECU: a136 ft electrical angle qf";
CM_ SG_ 919 EPASTP_a137_osehErrWithoutImmedi "EPASTP ECU: a137 oseh err without immediate reset";
CM_ SG_ 919 EPASTP_a138_osehAdditionalErrWit "EPASTP ECU: a138 oseh additional err without imm reset";
CM_ SG_ 919 EPASTP_a139_osehAdditionalOsErr "EPASTP ECU: a139 oseh additional os err";
CM_ SG_ 919 EPASTP_a140_imcmConfigurationErr "EPASTP ECU: a140 imcm configuration err";
CM_ SG_ 919 EPASTP_a141_amFetShortTest "EPASTP ECU: a141 am fet short test";
CM_ SG_ 919 EPASTP_a142_tedEmifilterDmcTempC "EPASTP ECU: a142 ted emifilter dmc temp checker";
CM_ SG_ 919 EPASTP_a143_tedEmifilterCmcTempC "EPASTP ECU: a143 ted emifilter cmc temp checker";
CM_ SG_ 919 EPASTP_a144_mriCoreRaminitFailed "EPASTP ECU: a144 mri core raminit failed";
CM_ SG_ 919 EPASTP_a145_mriPeripheralRaminit "EPASTP ECU: a145 mri peripheral raminit failed";
CM_ SG_ 919 EPASTP_a146_btarcRcCircuitCheck "EPASTP ECU: a146 btarc rc circuit check";
CM_ SG_ 919 EPASTP_a147_amDcLinkShortedFail "EPASTP ECU: a147 am dc link shorted fail";
CM_ SG_ 919 EPASTP_a148_mrccExitFromStandbyD "EPASTP ECU: a148 mrcc exit from standby detected";
CM_ SG_ 919 EPASTP_a149_amReversibleEmergenc "EPASTP ECU: a149 am reversible emergency off requested";
CM_ SG_ 919 EPASTP_a150_amExternalEmergencyO "EPASTP ECU: a150 am external emergency off requested";
CM_ SG_ 919 EPASTP_a151_amPermanentEmergency "EPASTP ECU: a151 am permanent emergency off requested";
CM_ SG_ 919 EPASTP_a152_exchFlashEccExceptio "EPASTP ECU: a152 exch flash ecc exception";
CM_ SG_ 919 EPASTP_a153_sdsmBlockSelectorInv "EPASTP ECU: a153 sdsm block selector invalid";
CM_ SG_ 919 EPASTP_a154_sdsmCsErrorInvalidPr "EPASTP ECU: a154 sdsm cs error invalid primary";
CM_ SG_ 919 EPASTP_a155_sdsmDataInvalidAll "EPASTP ECU: a155 sdsm data invalid all";
CM_ SG_ 919 EPASTP_a156_amIntSerialErrSafety "EPASTP ECU: a156 am int serial err safety reset";
CM_ SG_ 919 EPASTP_a157_mcudcpInvalidEcuId "EPASTP ECU: a157 mcudcp invalid ecu id";
CM_ SG_ 919 EPASTP_a158_amGduFailDuringRecov "EPASTP ECU: a158 am gdu fail during recovery";
CM_ SG_ 919 EPASTP_a159_exchFlashWordlineTra "EPASTP ECU: a159 exch flash wordline transient err";
CM_ SG_ 919 EPASTP_a160_rsthCpu1UnexpectedAl "EPASTP ECU: a160 rsth cpu1 unexpected alarm";
CM_ SG_ 919 EPASTP_a161_tdaRelayfetjunctionT "EPASTP ECU: a161 tda relayfetjunction temp checker";
CM_ SG_ 919 EPASTP_a162_tdaBridgefetjunction "EPASTP ECU: a162 tda bridgefetjunction temp checker";
CM_ SG_ 919 EPASTP_a163_tdaPowermoduleTempCh "EPASTP ECU: a163 tda powermodule temp checker";
CM_ SG_ 919 EPASTP_a164_tdaBattfetjunctionTe "EPASTP ECU: a164 tda battfetjunction temp checker";
CM_ SG_ 919 EPASTP_a165_tdaDcbusshuntTempChe "EPASTP ECU: a165 tda dcbusshunt temp checker";
CM_ SG_ 919 EPASTP_a166_tdaPhasecurrentshunt "EPASTP ECU: a166 tda phasecurrentshunt temp checker";
CM_ SG_ 919 EPASTP_a167_iccd1ErrQueueOverflo "EPASTP ECU: a167 iccd1 err queue overflow";
CM_ SG_ 919 EPASTP_a168_c1csInvalidC1App "EPASTP ECU: a168 c1cs invalid C1 app";
CM_ SG_ 919 EPASTP_a169_scpSafetyReset "EPASTP ECU: a169 scp safety reset";
CM_ SG_ 919 EPASTP_a170_pmpDcvoltAge "EPASTP ECU: a170 pmp dcvolt age";
CM_ SG_ 919 EPASTP_a171_pmpKgvalueAge "EPASTP ECU: a171 pmp kgvalue age";
CM_ SG_ 919 EPASTP_a172_pmpElangMotorcurrent "EPASTP ECU: a172 pmp elang motorcurrent age";
CM_ SG_ 919 EPASTP_a173_pmpRotorspeedAge "EPASTP ECU: a173 pmp rotorspeed age";
CM_ SG_ 919 EPASTP_a174_pmpPhasecurrentAge "EPASTP ECU: a174 pmp phasecurrent age";
CM_ SG_ 919 EPASTP_a175_exchFlashStoredConfi "EPASTP ECU: a175 exch flash stored config err";
CM_ SG_ 919 EPASTP_a176_exchCpu1ExceptionRes "EPASTP ECU: a176 exch cpu1 exception reset";
CM_ SG_ 919 EPASTP_a177_etsrInvalidated "EPASTP ECU: a177 etsr invalidated";
CM_ SG_ 919 EPASTP_a178_exchWdtException "EPASTP ECU: a178 exch wdt exception";
CM_ SG_ 919 EPASTP_a179_tedMotorcoilTempChec "EPASTP ECU: a179 ted motorcoil temp checker";
CM_ SG_ 919 EPASTP_a180_dmDeadlineViolationC "EPASTP ECU: a180 dm deadline violation C1";
CM_ SG_ 919 EPASTP_a181_dmDeadlineViolationC "EPASTP ECU: a181 dm deadline violation C1";
CM_ SG_ 919 EPASTP_a182_mcdInputMia "EPASTP ECU: a182 mcd input mia";
CM_ SG_ 919 EPASTP_a183_sbchCommErrSbcToMcu "EPASTP ECU: a183 sbch comm err sbc to mcu";
CM_ SG_ 919 EPASTP_a184_sbcmCommBufferOverfl "EPASTP ECU: a184 sbcm comm buffer overflow";
CM_ SG_ 919 EPASTP_a185_sbcscpQAWatchdogRese "EPASTP ECU: a185 sbcscp QA watchdog reset";
CM_ SG_ 919 EPASTP_a186_wdhCommBufferOverflo "EPASTP ECU: a186 wdh comm buffer overflow";
CM_ SG_ 919 EPASTP_a187_epmVoltFail "EPASTP ECU: a187 epm volt fail";
CM_ SG_ 919 EPASTP_a188_epmCommBufferOverflo "EPASTP ECU: a188 epm comm buffer overflow";
CM_ SG_ 919 EPASTP_a189_sbchCommErrMcuToSbc "EPASTP ECU: a189 sbch comm err mcu to sbc";
CM_ SG_ 919 EPASTP_a190_sbchCommBufferOverfl "EPASTP ECU: a190 sbch comm buffer overflow";
CM_ SG_ 919 EPASTP_a191_sbcscpVcp2VucVoltFai "EPASTP ECU: a191 sbcscp vcp2 vuc volt fail";
CM_ SG_ 919 EPASTP_a192_osumC0CsaNearFull "EPASTP ECU: a192 osum C0 csa near full";
CM_ SG_ 919 EPASTP_a193_osumC0StackNearFull "EPASTP ECU: a193 osum C0 stack near full";
CM_ SG_ 919 EPASTP_a194_amNvdataLoss "EPASTP ECU: a194 am nvdata loss";
CM_ SG_ 919 EPASTP_a195_imcmCommErrC1 "EPASTP ECU: a195 imcm comm err C1";
CM_ SG_ 919 EPASTP_a196_topEolTasOffsetInval "EPASTP ECU: a196 top eol tas offset invalid";
CM_ SG_ 919 EPASTP_a197_difpDifactorInvalid "EPASTP ECU: a197 difp difactor invalid";
CM_ SG_ 919 EPASTP_a198_osumC1CsaNearFull "EPASTP ECU: a198 osum C1 csa near full";
CM_ SG_ 919 EPASTP_a199_osumC1StackNearFull "EPASTP ECU: a199 osum C1 stack near full";
CM_ SG_ 919 EPASTP_a200_ammInputBufferOverfl "EPASTP ECU: a200 amm input buffer overflow";
CM_ SG_ 919 EPASTP_a201_ammOutputBufferOverf "EPASTP ECU: a201 amm output buffer overflow";
CM_ SG_ 919 EPASTP_a202_ohnvmpStoredOffsetLo "EPASTP ECU: a202 ohnvmp stored offset lost";
CM_ SG_ 919 EPASTP_a203_ctcInterfaceErr "EPASTP ECU: a203 ctc interface err";
CM_ SG_ 919 EPASTP_a204_fdpPrevTrqErr "EPASTP ECU: a204 fdp prev trq err";
CM_ SG_ 919 EPASTP_a205_fdrOclFail "EPASTP ECU: a205 fdr ocl fail";
CM_ SG_ 919 EPASTP_a206_fdrOclPartialBlockin "EPASTP ECU: a206 fdr ocl partial blocking";
CM_ SG_ 919 EPASTP_a207_fdrOclFreezing "EPASTP ECU: a207 fdr ocl freezing";
CM_ SG_ 919 EPASTP_a208_fdrLowSeverityBlocki "EPASTP ECU: a208 fdr low severity blocking";
CM_ SG_ 919 EPASTP_a209_fdrLowSeverityFreezi "EPASTP ECU: a209 fdr low severity freezing";
CM_ SG_ 919 EPASTP_a210_fdrTotalBlocking "EPASTP ECU: a210 fdr total blocking";
CM_ SG_ 919 EPASTP_a211_frmInternalErr "EPASTP ECU: a211 frm internal err";
CM_ SG_ 919 EPASTP_a212_frmDataLost "EPASTP ECU: a212 frm data lost";
CM_ SG_ 919 EPASTP_a213_frmHighFrictionDetec "EPASTP ECU: a213 frm high friction detected";
CM_ SG_ 919 EPASTP_a214_velInterfaceErr "EPASTP ECU: a214 vel interface err";
CM_ SG_ 919 EPASTP_a215_vsgSafeViolErr "EPASTP ECU: a215 vsg safe viol err";
CM_ SG_ 919 EPASTP_a216_isdgImproperShutdown "EPASTP ECU: a216 isdg improper shutdown";
CM_ SG_ 919 EPASTP_a217_msdMasterSilentErr "EPASTP ECU: a217 msd master silent err";
CM_ SG_ 919 EPASTP_a218_aadApplicationStateE "EPASTP ECU: a218 aad application state err";
CM_ SG_ 919 EPASTP_a219_frhFastRestartFailed "EPASTP ECU: a219 frh fast restart failed";
CM_ SG_ 919 EPASTP_a221_apsCntError "EPASTP ECU: a221 aps cnt error";
CM_ SG_ 919 EPASTP_a222_apsCsError "EPASTP ECU: a222 aps cs error";
CM_ SG_ 919 EPASTP_a223_apsMia "EPASTP ECU: a223 aps mia";
CM_ SG_ 919 EPASTP_a224_dasCntError "EPASTP ECU: a224 das cnt error";
CM_ SG_ 919 EPASTP_a225_dasCsError "EPASTP ECU: a225 das cs error";
CM_ SG_ 919 EPASTP_a226_dasMia "EPASTP ECU: a226 das mia";
CM_ SG_ 919 EPASTP_a227_dirTorqueCntError "EPASTP ECU: a227 dir torque cnt error";
CM_ SG_ 919 EPASTP_a228_dirTorqueCsError "EPASTP ECU: a228 dir torque cs error";
CM_ SG_ 919 EPASTP_a229_dirTorqueMia "EPASTP ECU: a229 dir torque mia";
CM_ SG_ 919 EPASTP_a230_diSpdCntError "EPASTP ECU: a230 di spd cnt error";
CM_ SG_ 919 EPASTP_a231_diSpdCsError "EPASTP ECU: a231 di spd cs error";
CM_ SG_ 919 EPASTP_a232_diSpdMia "EPASTP ECU: a232 di spd mia";
CM_ SG_ 919 EPASTP_a233_ecu2StatCntError "EPASTP ECU: a233 ecu2 stat cnt error";
CM_ SG_ 919 EPASTP_a234_ecu2StatCsError "EPASTP ECU: a234 ecu2 stat cs error";
CM_ SG_ 919 EPASTP_a235_ecu2StatMia "EPASTP ECU: a235 ecu2 stat mia";
CM_ SG_ 919 EPASTP_a236_espWrCntError "EPASTP ECU: a236 esp wr cnt error";
CM_ SG_ 919 EPASTP_a237_espWrCsError "EPASTP ECU: a237 esp wr cs error";
CM_ SG_ 919 EPASTP_a238_espWrMia "EPASTP ECU: a238 esp wr mia";
CM_ SG_ 919 EPASTP_a239_espWsCntError "EPASTP ECU: a239 esp ws cnt error";
CM_ SG_ 919 EPASTP_a240_espWsCsError "EPASTP ECU: a240 esp ws cs error";
CM_ SG_ 919 EPASTP_a241_espWsMia "EPASTP ECU: a241 esp ws mia";
CM_ SG_ 919 EPASTP_a242_gtwConfigMia "EPASTP ECU: a242 gtw config mia";
CM_ SG_ 919 EPASTP_a243_rcmCntError "EPASTP ECU: a243 rcm cnt error";
CM_ SG_ 919 EPASTP_a244_rcmCsError "EPASTP ECU: a244 rcm cs error";
CM_ SG_ 919 EPASTP_a245_rcmMia "EPASTP ECU: a245 rcm mia";
CM_ SG_ 919 EPASTP_a246_sccmCntError "EPASTP ECU: a246 sccm cnt error";
CM_ SG_ 919 EPASTP_a247_sccmCsError "EPASTP ECU: a247 sccm cs error";
CM_ SG_ 919 EPASTP_a248_sccmMia "EPASTP ECU: a248 sccm mia";
CM_ SG_ 919 EPASTP_a249_uiTuneReqCntError "EPASTP ECU: a249 ui tune req cnt error";
CM_ SG_ 919 EPASTP_a250_uiTuneReqCsError "EPASTP ECU: a250 ui tune req cs error";
CM_ SG_ 919 EPASTP_a251_uiTuneReqMia "EPASTP ECU: a251 ui tune req mia";
CM_ SG_ 919 EPASTP_a252_vcFrontCntError "EPASTP ECU: a252 vc front cnt error";
CM_ SG_ 919 EPASTP_a253_vcFrontCsError "EPASTP ECU: a253 vc front cs error";
CM_ SG_ 919 EPASTP_a254_vcFrontMia "EPASTP ECU: a254 vc front mia";
CM_ SG_ 919 EPASTP_a255_pmState2Mia "EPASTP ECU: a255 pm state2 mia";
CM_ SG_ 919 EPASTP_a256_dcvmOverVolt "EPASTP ECU: a256 dcvm over volt";
CM_ SG_ 919 EPASTP_a257_dcvmUnderVolt "EPASTP ECU: a257 dcvm under volt";
CM_ SG_ 919 EPASTP_a258_pspInvalidProjectPar "EPASTP ECU: a258 psp invalid project paramset";
CM_ SG_ 919 EPASTP_a259_scoCanBusOff "EPASTP ECU: a259 sco can bus off";
CM_ SG_ 919 EPASTP_a260_scoPrivateBusOff "EPASTP ECU: a260 sco private bus off";
CM_ SG_ 919 EPASTP_a261_sccmStatusError "EPASTP ECU: a261 sccm status error";
CM_ SG_ 919 EPASTP_a262_yawRateStatus "EPASTP ECU: a262 yaw rate status";
CM_ SG_ 919 EPASTP_a263_espWsStatus "EPASTP ECU: a263 esp ws status";
CM_ SG_ 919 EPASTP_a264_assistTorqueLimited "EPASTP ECU: a264 assist torque limited";
CM_ SG_ 919 EPASTP_a265_overheatProtect "EPASTP ECU: a265 overheat protect";
CM_ SG_ 919 EPASTP_a266_overloadProtect "EPASTP ECU: a266 overload protect";
CM_ SG_ 919 EPASTP_a267_safeSpeedAssist "EPASTP ECU: a267 safe speed assist";
CM_ SG_ 919 EPASTP_a268_eacCancelled "EPASTP ECU: a268 eac cancelled";
CM_ SG_ 919 EPASTP_a269_assistTorqueDisabled "EPASTP ECU: a269 assist torque disabled";
CM_ SG_ 919 EPASTP_a270_oscillationCompTrqLi "EPASTP ECU: a270 oscillation comp trq lim reached";
CM_ BO_ 909 "Electronic stability control message: party3; frame length from the layout, not yet observed on a vehicle bus";
CM_ SG_ 909 ESP_party3Crc "Electronic stability control: party3 crc";
CM_ SG_ 909 ESP_party3Counter "Electronic stability control: party3 counter";
CM_ SG_ 909 ESP_absActive "Electronic stability control: abs active";
CM_ SG_ 909 ESP_vehicleStandstill "Indicates that the vehicle is completely stationary.";
CM_ SG_ 909 ESP_vehicleStandstillQF "Qualifier of ESP_vehicleStandstill.";
CM_ SG_ 909 ESP_pEstMaximum "Maximum of estimated wheel braking pressure.";
CM_ SG_ 909 ESP_privateVehicleSpd "Vehicle speed as calculated by the ESP from the wheel speed sensors.";
CM_ SG_ 909 ESP_decoupledBrakePressOffsetCom "Master cylinder pressure sensor offset; raw 127 = signal not available (SNA)";
CM_ SG_ 909 ESP_privateVehicleSpdQF "ESP private vehicle speed qualifier";
CM_ SG_ 909 ESP_brakeMasterCylPress "Master cylinder pressure measured in the ESP; raw 1023 = signal not available (SNA)";
CM_ SG_ 909 ESP_brakeMasterCylPressQF "Reports the brake master cylinder pressure signal (ESP_brakeMasterCylPress) qualification status.";
CM_ BO_ 325 "Electronic stability control message: status; frame length from the layout, not yet observed on a vehicle bus";
CM_ SG_ 325 ESP_statusChecksum "Electronic stability control: status checksum";
CM_ SG_ 325 ESP_statusCounter "Electronic stability control: status counter";
CM_ SG_ 325 ESP_espModeActive "Electronic stability control: esp mode active";
CM_ SG_ 325 ESP_stabilityControlSts2 "Electronic stability control: stability control sts2";
CM_ SG_ 325 ESP_ebdFaultLamp "Electronic stability control: ebd fault lamp";
CM_ SG_ 325 ESP_absFaultLamp "ESP request to display ABS Fault Lamp.";
CM_ SG_ 325 ESP_espFaultLamp "ESP request to display ESP Fault lamp in instrument cluster.";
CM_ SG_ 325 ESP_hydraulicBoostEnabled "Electronic stability control: hydraulic boost enabled";
CM_ SG_ 325 ESP_espLampFlash "Electronic stability control: esp lamp flash";
CM_ SG_ 325 ESP_brakeLamp "Electronic stability control: brake lamp";
CM_ SG_ 325 ESP_absBrakeEvent2 "Indicates if ABS is active and on which axle.";
CM_ SG_ 325 ESP_longitudinalAccelQF "Longitudinal accel sensor quialifier from ESP";
CM_ SG_ 325 ESP_lateralAccelQF "Lateral accel sensor quialifier from ESP";
CM_ SG_ 325 ESP_yawRateQF "Electronic stability control: yaw rate QF";
CM_ SG_ 325 ESP_steeringAngleQF "Electronic stability control: steering angle QF";
CM_ SG_ 325 ESP_brakeDiscWipingActive "Indicates when brake disc wiping is active.";
CM_ SG_ 325 ESP_driverBrakeApply "Indicates when the driver applies the brake pedal; raw 3 = signal not available (SNA)";
CM_ SG_ 325 ESP_brakeApply "Electronic stability control: brake apply";
CM_ SG_ 325 ESP_aesPrimaryActuatorStatus "Electronic stability control: aes primary actuator status";
CM_ SG_ 325 ESP_cdpStatus "Indicates the state of the ESP to perform pressure builds through ESP for dynamic apply";
CM_ SG_ 325 ESP_ptcTargetState "Electronic stability control: ptc target state; raw 3 = signal not available (SNA)";
CM_ SG_ 325 ESP_btcTargetState "Electronic stability control: btc target state; raw 3 = signal not available (SNA)";
CM_ SG_ 325 ESP_decoupledBrakePressEst "Reports the master cylinder pressure estimated by the Electronic Stability Program (ESP) which includes four wheel ESP active pressure builds; raw 255 = signal not available (SNA)";
CM_ SG_ 325 ESP_ebrStandstillSkid "Electronic stability control: ebr standstill skid";
CM_ SG_ 325 ESP_ebrStatus "Electronic stability control: ebr status";
CM_ SG_ 325 ESP_brakeTorqueTarget "Electronic stability control: brake torque target";
CM_ BO_ 373 "Electronic stability control message: wheel speeds; frame length from the layout, not yet observed on a vehicle bus";
CM_ SG_ 373 ESP_wheelSpeedFrL "Electronic stability control: wheel speed fr l";
CM_ SG_ 373 ESP_wheelSpeedFrR "Electronic stability control: wheel speed fr r";
CM_ SG_ 373 ESP_wheelSpeedReL "Electronic stability control: wheel speed re l";
CM_ SG_ 373 ESP_wheelSpeedReR "Electronic stability control: wheel speed re r";
CM_ BO_ 925 "Electric brake booster message: status; frame length from the layout, not yet observed on a vehicle bus";
CM_ SG_ 925 IBST_statusChecksum "Electric brake booster: status checksum";
CM_ SG_ 925 IBST_statusCounter "Electric brake booster: status counter";
CM_ SG_ 925 IBST_iBoosterStatus "Indication of iBooster functional state";
CM_ SG_ 925 IBST_driverBrakeApply "Indicates when the driver applies the brake pedal.";
CM_ SG_ 925 IBST_internalState "Indication of iBooster internal state";
CM_ SG_ 925 IBST_sInputRodDriver "IBST estimated input rod stroke";
CM_ SG_ 925 IBST_LVPowerModeState "Electric brake booster: LV power mode state";
CM_ BO_ 1316 "PMF ECU message: mfg data; frame length from the layout, not yet observed on a vehicle bus";
CM_ SG_ 1316 PMF_processorDieIdLot "PMF ECU: processor die id lot";
CM_ SG_ 1316 PMF_processorDieIdWafer "PMF ECU: processor die id wafer";
CM_ SG_ 1316 PMF_processorDieIdX "PMF ECU: processor die id x";
CM_ SG_ 1316 PMF_processorDieIdY "PMF ECU: processor die id y";
CM_ BO_ 1364 "PMR ECU message: mfg data; frame length from the layout, not yet observed on a vehicle bus";
CM_ SG_ 1364 PMR_processorDieIdLot "PMR ECU: processor die id lot";
CM_ SG_ 1364 PMR_processorDieIdWafer "PMR ECU: processor die id wafer";
CM_ SG_ 1364 PMR_processorDieIdX "PMR ECU: processor die id x";
CM_ SG_ 1364 PMR_processorDieIdY "PMR ECU: processor die id y";
CM_ BO_ 1973 "PM ECU message: itpms display; frame length from the layout, not yet observed on a vehicle bus";
CM_ SG_ 1973 PM_itpmsDisplaySelector "PM ECU: itpms display selector";
CM_ SG_ 1973 PM_indirectTPMSTellTale "Indirect TPMS UI telltale status to indicate system availability";
CM_ SG_ 1973 PM_indirectTPMSDisplayState "Indirect TPMS UI calibration state";
CM_ SG_ 1973 PM_indirectTPMSDisplayProgress "PM ECU: indirect TPMS display progress";
CM_ SG_ 1973 PM_indirectTPMSDisplayWarningInd "Pressure loss warning indicator per wheel determined by indirect TPMS";
CM_ SG_ 1973 PM_indirectTPMSDisplayWarni_0001 "Pressure loss warning indicator per wheel determined by indirect TPMS";
CM_ SG_ 1973 PM_indirectTPMSDisplayWarni_0002 "Pressure loss warning indicator per wheel determined by indirect TPMS";
CM_ SG_ 1973 PM_indirectTPMSDisplayWarni_0003 "Pressure loss warning indicator per wheel determined by indirect TPMS";
CM_ SG_ 1973 PM_indirectTPMSRecommendedColdPr "Reports the recommended cold pressure for the front or rear tires as provided by the Indirect Tire Pressure Monitoring System (ITPMS); raw 255 = signal not available (SNA)";
CM_ SG_ 1973 PM_indirectTPMSRecommendedC_0001 "Reports the recommended cold pressure for the front or rear tires as provided by the Indirect Tire Pressure Monitoring System (ITPMS); raw 255 = signal not available (SNA)";
CM_ SG_ 1973 PM_fusedPressureEstimateFrL "Reports the estimated tire pressure at each wheel based on Indirect Tire Pressure Monitoring System (ITPMS) relative wheel speed and Global Navigation Satellite System (GNSS) absolute radius data.";
CM_ SG_ 1973 PM_fusedPressureEstimateFrR "Reports the estimated tire pressure at each wheel based on Indirect Tire Pressure Monitoring System (ITPMS) relative wheel speed and Global Navigation Satellite System (GNSS) absolute radius data.";
CM_ SG_ 1973 PM_fusedPressureEstimateReL "Reports the estimated tire pressure at each wheel based on Indirect Tire Pressure Monitoring System (ITPMS) relative wheel speed and Global Navigation Satellite System (GNSS) absolute radius data.";
CM_ SG_ 1973 PM_fusedPressureEstimateReR "Reports the estimated tire pressure at each wheel based on Indirect Tire Pressure Monitoring System (ITPMS) relative wheel speed and Global Navigation Satellite System (GNSS) absolute radius data.";
CM_ BO_ 2038 "PM ECU message: vdc debug; frame length from the layout, not yet observed on a vehicle bus";
CM_ SG_ 2038 PM_vdcDebugSelector "PM ECU: vdc debug selector";
CM_ SG_ 2038 PM_VDCA_TCSlipTargetMod_RA_Fwd "PM ECU: VDCA TC slip target mod RA fwd";
CM_ SG_ 2038 PM_VDCA_TCSlipTargetMod_RA_Rwd "PM ECU: VDCA TC slip target mod RA rwd";
CM_ SG_ 2038 PM_VSE_forceY_RA "PM ECU: VSE force y RA";
CM_ SG_ 2038 PM_VDCT_observerSlipAngle_RA "PM ECU: VDCT observer slip angle RA";
CM_ SG_ 2038 PM_VSE_muVehicleFxLow "PM ECU: VSE mu vehicle fx low";
CM_ SG_ 2038 PM_VE_fxmFres "PM ECU: VE fxm fres";
CM_ SG_ 2038 PM_VE_fxAccelMass "PM ECU: VE fx accel mass";
CM_ SG_ 2038 PM_VE_vxDotGrade "PM ECU: VE vx dot grade";
CM_ SG_ 2038 PM_VE_betaEst "PM ECU: VE beta est";
CM_ SG_ 2038 PM_VSE_muVehicleFxHigh "PM ECU: VSE mu vehicle fx high";
CM_ SG_ 2038 PM_VSE_muVehicleDecLeakRate "PM ECU: VSE mu vehicle dec leak rate";
CM_ SG_ 2038 PM_VSE_muVehicleLearnDown "PM ECU: VSE mu vehicle learn down";
CM_ SG_ 2038 PM_VSE_muVehicleDecFilter "PM ECU: VSE mu vehicle dec filter";
CM_ SG_ 2038 PM_VSE_muVehicleLatDecLeakRate "PM ECU: VSE mu vehicle lat dec leak rate";
CM_ SG_ 2038 PM_VSE_splitMuProbability "PM ECU: VSE split mu probability";
CM_ SG_ 2038 PM_VSE_splitMuTotalMz "PM ECU: VSE split mu total mz";
CM_ SG_ 2038 PM_VSE_attitudeBankAngle "PM ECU: VSE attitude bank angle";
CM_ SG_ 2038 PM_VSE_attitudeDBetaInControl "PM ECU: VSE attitude d beta in control";
CM_ SG_ 2038 PM_VSE_roadWheelAngleAverage "PM ECU: VSE road wheel angle average";
CM_ BO_ 17 "Restraint control module message: collision; frame length from the layout, not yet observed on a vehicle bus";
CM_ SG_ 17 RCM_collisionChecksum "Restraint control module: collision checksum";
CM_ SG_ 17 RCM_collisionCounter "Restraint control module: collision counter";
CM_ SG_ 17 RCM_collisionRear "Indicates that a rear collision occurred; raw 3 = signal not available (SNA)";
CM_ SG_ 17 RCM_collisionRight "Indicates that a right side collision occurred; raw 3 = signal not available (SNA)";
CM_ SG_ 17 RCM_collisionLeft "Indicates that a left side collision occurred; raw 3 = signal not available (SNA)";
CM_ SG_ 17 RCM_collisionFront "Indicates that a frontal collision occurred; raw 3 = signal not available (SNA)";
CM_ SG_ 17 RCM_collisionRollover "Indicates that a rollover has occurred; raw 3 = signal not available (SNA)";
CM_ SG_ 17 RCM_collisionPedPro "Indicates that a pedestrian impact has occurred; raw 3 = signal not available (SNA)";
CM_ SG_ 17 RCM_collisionSeverity "Collision severity";
CM_ BO_ 289 "Restraint control module message: near deploy; frame length from the layout, not yet observed on a vehicle bus";
CM_ SG_ 289 RCM_nearDeployChecksum "Restraint control module: near deploy checksum";
CM_ SG_ 289 RCM_nearDeployCounter "Restraint control module: near deploy counter";
CM_ SG_ 289 RCM_nearDeployRear "Indicates that a rear near deploy event has occurred. No airbags have been deployed; raw 3 = signal not available (SNA)";
CM_ SG_ 289 RCM_nearDeployRight "Indicates that a right side near deploy event has occurred. No airbags have been deployed; raw 3 = signal not available (SNA)";
CM_ SG_ 289 RCM_nearDeployLeft "Indicates that a left side near deploy event has occurred. No airbags have been deployed; raw 3 = signal not available (SNA)";
CM_ SG_ 289 RCM_nearDeployFront "Indicates that a frontal near deploy event has occurred. No airbags have been deployed; raw 3 = signal not available (SNA)";
CM_ SG_ 289 RCM_nearDeployRollover "Indicates that a roll over near deploy event has occurred. No airbags have been deployed; raw 3 = signal not available (SNA)";
CM_ SG_ 289 RCM_crashAlgoWakeup "Crash Algorithm Wakeup status; raw 3 = signal not available (SNA)";
CM_ BO_ 1618 "VCBATT0 ECU message: info; frame length from the layout, not yet observed on a vehicle bus";
CM_ SG_ 1618 VCBATT0_infoIndex "VCBATT0 ECU: info index";
CM_ SG_ 1618 VCBATT0_infoBuildType "VCBATT0 ECU: info build type";
CM_ SG_ 1618 VCBATT0_infoBuildConfigId "VCBATT0 ECU: info build config id";
CM_ SG_ 1618 VCBATT0_infoHardwareId "VCBATT0 ECU: info hardware id";
CM_ SG_ 1618 VCBATT0_infoComponentId "VCBATT0 ECU: info component id";
CM_ SG_ 1618 VCBATT0_infoPcbaId "VCBATT0 ECU: info pcba id";
CM_ SG_ 1618 VCBATT0_infoAssemblyId "VCBATT0 ECU: info assembly id; raw 255 = signal not available (SNA)";
CM_ SG_ 1618 VCBATT0_infoUsageId "VCBATT0 ECU: info usage id";
CM_ SG_ 1618 VCBATT0_infoSubUsageId "VCBATT0 ECU: info sub usage id";
CM_ SG_ 1618 VCBATT0_infoAppCrc "VCBATT0 ECU: info app crc";
CM_ SG_ 1618 VCBATT0_infoAppGitHash "VCBATT0 ECU: info app git hash";
CM_ SG_ 1618 VCBATT0_infoBootGitHash "VCBATT0 ECU: info boot git hash";
CM_ SG_ 1618 VCBATT0_infoBootUdsProtoVersion "VCBATT0 ECU: info boot uds proto version";
CM_ SG_ 1618 VCBATT0_infoBootCrc "VCBATT0 ECU: info boot crc";
CM_ BO_ 1994 "VCCC ECU message: info; frame length from the layout, not yet observed on a vehicle bus";
CM_ SG_ 1994 VCCC_infoIndex "VCCC ECU: info index";
CM_ SG_ 1994 VCCC_infoBuildType "VCCC ECU: info build type";
CM_ SG_ 1994 VCCC_infoBuildConfigId "VCCC ECU: info build config id";
CM_ SG_ 1994 VCCC_infoHardwareId "VCCC ECU: info hardware id";
CM_ SG_ 1994 VCCC_infoComponentId "VCCC ECU: info component id";
CM_ SG_ 1994 VCCC_infoPcbaId "VCCC ECU: info pcba id";
CM_ SG_ 1994 VCCC_infoAssemblyId "VCCC ECU: info assembly id; raw 255 = signal not available (SNA)";
CM_ SG_ 1994 VCCC_infoUsageId "VCCC ECU: info usage id";
CM_ SG_ 1994 VCCC_infoSubUsageId "VCCC ECU: info sub usage id";
CM_ SG_ 1994 VCCC_infoAppCrc "VCCC ECU: info app crc";
CM_ SG_ 1994 VCCC_infoAppGitHash "VCCC ECU: info app git hash";
CM_ SG_ 1994 VCCC_infoBootGitHash "VCCC ECU: info boot git hash";
CM_ SG_ 1994 VCCC_infoBootUdsProtoVersion "VCCC ECU: info boot uds proto version";
CM_ SG_ 1994 VCCC_infoBootCrc "VCCC ECU: info boot crc";
CM_ BO_ 260 "Front body controller message: party debug; frame length from the layout, not yet observed on a vehicle bus";
CM_ SG_ 260 VCFRONT_vcleftHighPower "Front body controller: vcleft high power";
CM_ SG_ 260 VCFRONT_vcrightHighPower "Front body controller: vcright high power";
CM_ SG_ 260 VCFRONT_uiHighPower "Front body controller: ui high power";
CM_ SG_ 260 VCFRONT_5VAStable "Front body controller: 5 VA stable";
CM_ SG_ 260 VCFRONT_5VBStable "Front body controller: 5 VB stable";
CM_ SG_ 260 VCFRONT_12VAStable "Front body controller: 12 VA stable";
CM_ SG_ 260 VCFRONT_12VBStable "Front body controller: 12 VB stable";
CM_ SG_ 260 VCFRONT_railA "Front body controller: rail a";
CM_ SG_ 260 VCFRONT_railB "Front body controller: rail b";
CM_ SG_ 260 VCFRONT_chargePumpStable "Front body controller: charge pump stable";
CM_ SG_ 260 VCFRONT_vehicleSM "Vehicle state machine state; raw 18 = signal not available (SNA)";
CM_ SG_ 260 VCFRONT_revBattFault "Front body controller: rev batt fault";
CM_ SG_ 260 VCFRONT_battSM "Front body controller: batt SM";
CM_ SG_ 260 VCFRONT_U13Init "Front body controller: U13 init";
CM_ SG_ 260 VCFRONT_U16Init "Front body controller: U16 init";
CM_ SG_ 260 VCFRONT_anyVehLoadShedActiveDBG "Front body controller: any veh load shed active DBG";
CM_ SG_ 260 VCFRONT_battVoltage "Front body controller: batt voltage";
CM_ SG_ 260 VCFRONT_battCurrent "Front body controller: batt current";
CM_ BO_ 258 "Left body controller message: door status; frame length from the layout, not yet observed on a vehicle bus";
CM_ SG_ 258 VCLEFT_doorClosureStatusFront "Status of the door from a closures perspective; raw 0 = signal not available (SNA)";
CM_ SG_ 258 VCLEFT_doorClosureStatusRear "Status of the door from a closures perspective; raw 0 = signal not available (SNA)";
CM_ SG_ 258 VCLEFT_frontLatchSwitch "State of front left door latch switch representing door open/closed. 0 is open and 1 is closed";
CM_ SG_ 258 VCLEFT_rearLatchSwitch "State of rear left door latch switch representing door open/closed. 0 is open and 1 is closed";
CM_ SG_ 258 VCLEFT_frontHandlePulled "Left body controller: front handle pulled";
CM_ SG_ 258 VCLEFT_rearHandlePulled "Left body controller: rear handle pulled";
CM_ SG_ 258 VCLEFT_frontRelActuatorSwitch "State of front left door latch switch representing latch arm/unarmed. Disarms while door handle is pulled.";
CM_ SG_ 258 VCLEFT_rearRelActuatorSwitch "State of rear left door latch switch representing latch arm/unarmed. Disarms while door handle is pulled";
CM_ SG_ 258 VCLEFT_frontLatchStatus "Status of left front door latch; raw 0 = signal not available (SNA)";
CM_ SG_ 258 VCLEFT_rearLatchStatus "Status of rear left door latch; raw 0 = signal not available (SNA)";
CM_ SG_ 258 VCLEFT_lastDoorReqSourceFront "last source of front door open request";
CM_ SG_ 258 VCLEFT_lastDoorReqSourceRear "last source of rear door open request";
CM_ SG_ 258 VCLEFT_frontIntSwitchFaulted "Indicates if the front door interior button is faulted";
CM_ SG_ 258 VCLEFT_rearIntSwitchFaulted "Indicates if the rear door interior button is faulted";
CM_ SG_ 258 VCLEFT_frontIntSwitchPressed "Left body controller: front int switch pressed";
CM_ SG_ 258 VCLEFT_rearIntSwitchPressed "Left body controller: rear int switch pressed";
CM_ SG_ 258 VCLEFT_mirrorTiltXPosition "Value representing left side view mirror tilt horizontal position";
CM_ SG_ 258 VCLEFT_mirrorTiltYPosition "Value representing left side view mirror tilt vertical position";
CM_ SG_ 258 VCLEFT_mirrorState "State of the left side view mirror.";
CM_ SG_ 258 VCLEFT_mirrorFoldState "Fold state for the left side view mirror";
CM_ SG_ 258 VCLEFT_mirrorRecallState "State of Mirror Recall.";
CM_ SG_ 258 VCLEFT_mirrorHeatState "Left body controller: mirror heat state; raw 0 = signal not available (SNA)";
CM_ SG_ 258 VCLEFT_rearHandlePulledPersist "Left body controller: rear handle pulled persist";
CM_ SG_ 258 VCLEFT_frontHandlePulledPersist "Left body controller: front handle pulled persist";
CM_ SG_ 258 VCLEFT_mirrorDipped "Reports if the side view mirrors in are in the dipped position.";
CM_ BO_ 546 "Left body controller message: epbm status; frame length from the layout, not yet observed on a vehicle bus";
CM_ SG_ 546 VCLEFT_cdpRequestState "If the Electronic Parking Brake makes a Controlled Deceleration for Parking Brake request, when cdpOkayToRequest is EPB_CDP_REQUEST_INVALID, cdpRequestState shall transition to EPB_CDP_REQUEST_INVALID, untill the Electronic Parking Brake Monitor enters unitStatus PARKED. Stability Control listens to this signal to qualify Controlled Deceleration for Parking Brake requests from the Electronic Parking Brake.";
CM_ SG_ 546 VCLEFT_epbmSystemStatusQF "Left body controller: epbm system status QF";
CM_ SG_ 546 VCLEFT_epbmUnitStatus "Electronic Parking Brake Monitors state.";
CM_ SG_ 546 VCLEFT_epbmCdpState "Left body controller: epbm cdp state";
CM_ SG_ 546 VCLEFT_epbmRedundantBrakingEnabl "Left body controller: epbm redundant braking enabled";
CM_ SG_ 546 VCLEFT_epbmStatusCounter "Left body controller: epbm status counter";
CM_ SG_ 546 VCLEFT_epbmStatusChecksum "Left body controller: epbm status checksum";
CM_ BO_ 778 "Left body controller message: restraint status; frame length from the layout, not yet observed on a vehicle bus";
CM_ SG_ 778 VCLEFT_frontOccupancyStatus "Left body controller: front occupancy status; raw 7 = signal not available (SNA)";
CM_ SG_ 778 VCLEFT_frontBuckleStatus "Status of front left seatbelt buckle";
CM_ SG_ 778 VCLEFT_rearLeftOccupancyStatus "Status of rear left seat occupancy sensor";
CM_ SG_ 778 VCLEFT_rearCenterOccupancyStatus "Status of rear center seat occupancy sensor";
CM_ SG_ 778 VCLEFT_rearRightOccupancyStatus "Status of rear right seat occupancy sensor";
CM_ SG_ 778 VCLEFT_rearLeftBuckleStatus "Status of rear left seatbelt buckle";
CM_ SG_ 778 VCLEFT_rearCenterBuckleStatus "Status of rear center seatbelt buckle";
CM_ SG_ 778 VCLEFT_seatTrackPosition "Status of seat track position sensor; raw 7 = signal not available (SNA)";
CM_ SG_ 778 VCLEFT_3RowLeftABStatus "Reports status of third row left airbag suppression; raw 2 = signal not available (SNA)";
CM_ SG_ 778 VCLEFT_3RowLeftBuckleStatus "Reports status of third row left seatbelt buckle";
CM_ SG_ 778 VCLEFT_restraintStatusCounter "Left body controller: restraint status counter";
CM_ SG_ 778 VCLEFT_restraintStatusChecksum "Left body controller: restraint status checksum";
CM_ BO_ 1124 "Right body controller message: AP hvac state1 hz; frame length from the layout, not yet observed on a vehicle bus";
CM_ SG_ 1124 VCRIGHT_AP_hvacState1HzIndex "Right body controller: AP hvac state1 hz index";
CM_ SG_ 1124 VCRIGHT_AP_tempCameraModele_0001 "Right body controller: AP temp camera modeled windshield out; raw 255 = signal not available (SNA)";
CM_ SG_ 1124 VCRIGHT_AP_tempCameraModeledWind "Right body controller: AP temp camera modeled windshield in; raw 255 = signal not available (SNA)";
CM_ SG_ 1124 VCRIGHT_AP_cameraModeledWin_0001 "Right body controller: AP camera modeled windshield out rh; raw 127 = signal not available (SNA)";
CM_ SG_ 1124 VCRIGHT_AP_cameraModeledWindshie "Right body controller: AP camera modeled windshield in rh; raw 127 = signal not available (SNA)";
CM_ SG_ 1124 VCRIGHT_AP_maxAchievableASideTem "Right body controller: AP max achievable a side temp camera pocket";
CM_ SG_ 1124 VCRIGHT_AP_cameraModeledPocketWa "Right body controller: AP camera modeled pocket water mass; raw 1023 = signal not available (SNA)";
CM_ SG_ 1124 VCRIGHT_AP_humidityModelInitStat "Right body controller: AP humidity model init status";
CM_ SG_ 1124 VCRIGHT_AP_humidityModelStatus "Right body controller: AP humidity model status";
CM_ BO_ 259 "Right body controller message: door status; frame length from the layout, not yet observed on a vehicle bus";
CM_ SG_ 259 VCRIGHT_doorClosureStatusFront "Status of the door from a closures perspective; raw 0 = signal not available (SNA)";
CM_ SG_ 259 VCRIGHT_doorClosureStatusRear "Status of the door from a closures perspective; raw 0 = signal not available (SNA)";
CM_ SG_ 259 VCRIGHT_frontLatchSwitch "State of front left door latch switch representing door open/closed. 0 is open and 1 is closed";
CM_ SG_ 259 VCRIGHT_rearLatchSwitch "State of rear right door latch switch representing door open/closed. 0 is open and 1 is closed";
CM_ SG_ 259 VCRIGHT_frontHandlePulled "Right body controller: front handle pulled";
CM_ SG_ 259 VCRIGHT_rearHandlePulled "Right body controller: rear handle pulled";
CM_ SG_ 259 VCRIGHT_frontRelActuatorSwitch "State of front left door latch switch representing latch arm/unarmed. Disarms while door handle is pulled.";
CM_ SG_ 259 VCRIGHT_rearRelActuatorSwitch "State of rear right door latch switch representing latch arm/unarmed. Disarms while door handle is pulled";
CM_ SG_ 259 VCRIGHT_frontLatchStatus "Status of right front door latch; raw 0 = signal not available (SNA)";
CM_ SG_ 259 VCRIGHT_rearLatchStatus "Status of rear right door latch; raw 0 = signal not available (SNA)";
CM_ SG_ 259 VCRIGHT_lastDoorReqSourceFront "last source of front door open request";
CM_ SG_ 259 VCRIGHT_lastDoorReqSourceRear "last source of rear door open request";
CM_ SG_ 259 VCRIGHT_frontIntSwitchFaulted "Indicates if the front door interior button is faulted";
CM_ SG_ 259 VCRIGHT_rearIntSwitchFaulted "Indicates if the rear door interior button is faulted";
CM_ SG_ 259 VCRIGHT_frontHandlePulledPersist "Right body controller: front handle pulled persist";
CM_ SG_ 259 VCRIGHT_frontIntSwitchPressed "Right body controller: front int switch pressed";
CM_ SG_ 259 VCRIGHT_rearIntSwitchPressed "Right body controller: rear int switch pressed";
CM_ SG_ 259 VCRIGHT_mirrorTiltXPosition "Value representing right side view mirror tilt horizontal position";
CM_ SG_ 259 VCRIGHT_mirrorTiltYPosition "Value representing right side view mirror tilt vertical position";
CM_ SG_ 259 VCRIGHT_mirrorState "State of the right side view mirror.";
CM_ SG_ 259 VCRIGHT_mirrorFoldState "Fold state for the right side view mirror";
CM_ SG_ 259 VCRIGHT_mirrorDipped "Reports if the side view mirrors in are in the dipped position.";
CM_ SG_ 259 VCRIGHT_trunkLatchStatus "State of the trunk latch; raw 0 = signal not available (SNA)";
CM_ SG_ 259 VCRIGHT_mirrorRecallState "State of Mirror Recall.";
CM_ SG_ 259 VCRIGHT_rearHandlePulledPersist "Right body controller: rear handle pulled persist";
CM_ BO_ 611 "Right body controller message: epbm status; frame length from the layout, not yet observed on a vehicle bus";
CM_ SG_ 611 VCRIGHT_cdpRequestState "If the Electronic Parking Brake makes a Controlled Deceleration for Parking Brake request, when cdpOkayToRequest is EPB_CDP_REQUEST_INVALID, cdpRequestState shall transition to EPB_CDP_REQUEST_INVALID, untill the Electronic Parking Brake Monitor enters unitStatus PARKED. Stability Control listens to this signal to qualify Controlled Deceleration for Parking Brake requests from the Electronic Parking Brake.";
CM_ SG_ 611 VCRIGHT_epbmSystemStatusQF "Right body controller: epbm system status QF";
CM_ SG_ 611 VCRIGHT_epbmUnitStatus "Electronic Parking Brake Monitors state.";
CM_ SG_ 611 VCRIGHT_epbmCdpState "Right body controller: epbm cdp state";
CM_ SG_ 611 VCRIGHT_epbmRedundantBrakingEnab "Right body controller: epbm redundant braking enabled";
CM_ SG_ 611 VCRIGHT_epbmStatusCounter "Right body controller: epbm status counter";
CM_ SG_ 611 VCRIGHT_epbmStatusChecksum "Right body controller: epbm status checksum";
CM_ BO_ 794 "Right body controller message: restraint status; frame length from the layout, not yet observed on a vehicle bus";
CM_ SG_ 794 VCRIGHT_frontOccupancyStatus "Right body controller: front occupancy status; raw 7 = signal not available (SNA)";
CM_ SG_ 794 VCRIGHT_frontBuckleStatus "Status of front right seatbelt buckle";
CM_ SG_ 794 VCRIGHT_rearCenterBuckleStatus "Right body controller: rear center buckle status";
CM_ SG_ 794 VCRIGHT_rearRightBuckleStatus "Right body controller: rear right buckle status";
CM_ SG_ 794 VCRIGHT_rearRightOccupancyStatus "Right body controller: rear right occupancy status";
CM_ SG_ 794 VCRIGHT_3RowLeftBuckleStatus "Status of third row left seatbelt buckle";
CM_ SG_ 794 VCRIGHT_3RowRightBuckleStatus "Right body controller: 3 row right buckle status";
CM_ SG_ 794 VCRIGHT_3RowLeftOccupancyStatus "Right body controller: 3 row left occupancy status";
CM_ SG_ 794 VCRIGHT_3RowRightOccupancyStatus "Right body controller: 3 row right occupancy status";
CM_ SG_ 794 VCRIGHT_seatTrackPosition "Right body controller: seat track position; raw 7 = signal not available (SNA)";
CM_ SG_ 794 VCRIGHT_occupantClassification "Right body controller: occupant classification; raw 7 = signal not available (SNA)";
CM_ SG_ 794 VCRIGHT_occupantClassificationQF "Right body controller: occupant classification QF";
CM_ SG_ 794 VCRIGHT_classificationEnabled "Indicates whether the RCM should consume VCRIGHT occupant classification rather than another source such as OCS1P";
CM_ SG_ 794 VCRIGHT_classificationEnabledQF "Indicates whether the VCRIGHT_classificationEnabled signal is valid";
CM_ SG_ 794 VCRIGHT_3RowRightABStatus "Reports status of third row right airbag suppression; raw 2 = signal not available (SNA)";
CM_ SG_ 794 VCRIGHT_restraintStatusCounter "Right body controller: restraint status counter";
CM_ SG_ 794 VCRIGHT_restraintStatusChecksum "Right body controller: restraint status checksum";
BA_DEF_ BO_ "GenMsgCycleTime" INT 0 3600000;
BA_DEF_ BO_ "GenMsgSendType" ENUM "Cyclic","NotUsed","NotUsed","NotUsed","NotUsed","NotUsed","NotUsed","IfActive","NoMsgSendType","NotUsed";
BA_DEF_ BO_ "VFrameFormat" ENUM "StandardCAN","ExtendedCAN","reserved","J1939PG","reserved","reserved","reserved","reserved","reserved","reserved","reserved","reserved","reserved","reserved","StandardCAN_FD","ExtendedCAN_FD";
BA_DEF_ BO_ "CANFD_BRS" ENUM "0","1";
BA_DEF_ SG_ "GenSigSNA" STRING;
BA_DEF_ SG_ "SystemSignalLongSymbol" STRING;
BA_DEF_ SG_ "Confidence" ENUM "validated","plausible","layout-only","contradicted";
BA_DEF_DEF_ "GenMsgCycleTime" 0;
BA_DEF_DEF_ "GenMsgSendType" "NoMsgSendType";
BA_DEF_DEF_ "VFrameFormat" "StandardCAN";
BA_DEF_DEF_ "CANFD_BRS" "1";
BA_DEF_DEF_ "GenSigSNA" "";
BA_DEF_DEF_ "SystemSignalLongSymbol" "";
BA_DEF_DEF_ "Confidence" "layout-only";
BA_ "GenMsgCycleTime" BO_ 919 1000;
BA_ "GenMsgSendType" BO_ 919 0;
BA_ "GenMsgCycleTime" BO_ 909 10;
BA_ "GenMsgSendType" BO_ 909 0;
BA_ "GenMsgCycleTime" BO_ 325 20;
BA_ "GenMsgSendType" BO_ 325 0;
BA_ "GenMsgCycleTime" BO_ 373 20;
BA_ "GenMsgSendType" BO_ 373 0;
BA_ "GenMsgCycleTime" BO_ 925 40;
BA_ "GenMsgSendType" BO_ 925 0;
BA_ "GenMsgCycleTime" BO_ 1316 1000;
BA_ "GenMsgSendType" BO_ 1316 0;
BA_ "GenMsgCycleTime" BO_ 1364 1000;
BA_ "GenMsgSendType" BO_ 1364 0;
BA_ "GenMsgCycleTime" BO_ 1973 1000;
BA_ "GenMsgSendType" BO_ 1973 0;
BA_ "GenMsgCycleTime" BO_ 2038 20;
BA_ "GenMsgSendType" BO_ 2038 0;
BA_ "GenMsgCycleTime" BO_ 17 10;
BA_ "GenMsgSendType" BO_ 17 0;
BA_ "GenMsgCycleTime" BO_ 289 10;
BA_ "GenMsgSendType" BO_ 289 0;
BA_ "GenMsgCycleTime" BO_ 1618 1000;
BA_ "GenMsgSendType" BO_ 1618 0;
BA_ "GenMsgCycleTime" BO_ 1994 1000;
BA_ "GenMsgSendType" BO_ 1994 0;
BA_ "GenMsgCycleTime" BO_ 260 100;
BA_ "GenMsgSendType" BO_ 260 0;
BA_ "GenMsgCycleTime" BO_ 258 100;
BA_ "GenMsgSendType" BO_ 258 0;
BA_ "GenMsgCycleTime" BO_ 546 100;
BA_ "GenMsgSendType" BO_ 546 0;
BA_ "GenMsgCycleTime" BO_ 778 50;
BA_ "GenMsgSendType" BO_ 778 0;
BA_ "GenMsgCycleTime" BO_ 1124 1000;
BA_ "GenMsgSendType" BO_ 1124 0;
BA_ "GenMsgCycleTime" BO_ 259 100;
BA_ "GenMsgSendType" BO_ 259 0;
BA_ "GenMsgCycleTime" BO_ 611 100;
BA_ "GenMsgSendType" BO_ 611 0;
BA_ "GenMsgCycleTime" BO_ 794 50;
BA_ "GenMsgSendType" BO_ 794 0;
BA_ "Confidence" SG_ 1427 EPASTP_alertID 1;
BA_ "Confidence" SG_ 1427 EPASTP_alertState 1;
BA_ "Confidence" SG_ 1427 EPASTP_a264_degradedECU 1;
BA_ "Confidence" SG_ 1427 EPASTP_a264_vehicleSpeed 1;
BA_ "Confidence" SG_ 1427 EPASTP_a264_powerRatio 1;
BA_ "Confidence" SG_ 1427 EPASTP_a264_ownSideDegradationRe 1;
BA_ "SystemSignalLongSymbol" SG_ 1427 EPASTP_a264_ownSideDegradationRe "EPASTP_a264_ownSideDegradationReason";
BA_ "Confidence" SG_ 1427 EPASTP_a264_otherSideDegradation 1;
BA_ "SystemSignalLongSymbol" SG_ 1427 EPASTP_a264_otherSideDegradation "EPASTP_a264_otherSideDegradationReason";
BA_ "Confidence" SG_ 1427 EPASTP_a265_degradedECU 1;
BA_ "Confidence" SG_ 1427 EPASTP_a265_vehicleSpeed 1;
BA_ "Confidence" SG_ 1427 EPASTP_a265_rawMcuTemperature 1;
BA_ "Confidence" SG_ 1427 EPASTP_a265_degradedCurrentLimit 1;
BA_ "Confidence" SG_ 1427 EPASTP_a266_cdpAssistFactor 1;
BA_ "Confidence" SG_ 1427 EPASTP_a266_vehicleSpeed 1;
BA_ "Confidence" SG_ 1427 EPASTP_a267_vehicleSpeed 1;
BA_ "Confidence" SG_ 1427 EPASTP_a267_velocityEstimatorSta 1;
BA_ "SystemSignalLongSymbol" SG_ 1427 EPASTP_a267_velocityEstimatorSta "EPASTP_a267_velocityEstimatorState";
BA_ "Confidence" SG_ 1427 EPASTP_a269_vehicleSpeed 1;
BA_ "Confidence" SG_ 919 EPASTP_matrixIndex 1;
BA_ "SystemSignalLongSymbol" SG_ 919 EPASTP_a001_adcCalibrationOrInit "EPASTP_a001_adcCalibrationOrInitFail";
BA_ "SystemSignalLongSymbol" SG_ 919 EPASTP_a005_scpUnknownResetSourc "EPASTP_a005_scpUnknownResetSource";
BA_ "SystemSignalLongSymbol" SG_ 919 EPASTP_a006_swrhResetByInvalidEr "EPASTP_a006_swrhResetByInvalidErrid";
BA_ "SystemSignalLongSymbol" SG_ 919 EPASTP_a009_mcusscLbistPermanent "EPASTP_a009_mcusscLbistPermanentFail";
BA_ "SystemSignalLongSymbol" SG_ 919 EPASTP_a010_svcIncompatibleSwVer "EPASTP_a010_svcIncompatibleSwVersions";
BA_ "SystemSignalLongSymbol" SG_ 919 EPASTP_a013_mcusscSffMonitoringF "EPASTP_a013_mcusscSffMonitoringFailed";
BA_ "SystemSignalLongSymbol" SG_ 919 EPASTP_a014_mcusscSffMonitoringM "EPASTP_a014_mcusscSffMonitoringMia";
BA_ "SystemSignalLongSymbol" SG_ 919 EPASTP_a015_mcusscCsErrorCheckFa "EPASTP_a015_mcusscCsErrorCheckFail";
BA_ "SystemSignalLongSymbol" SG_ 919 EPASTP_a016_mcufcCsErrorCheckFai "EPASTP_a016_mcufcCsErrorCheckFail";
BA_ "SystemSignalLongSymbol" SG_ 919 EPASTP_a017_stmdStmPlausibilityC "EPASTP_a017_stmdStmPlausibilityCheckErr";
BA_ "SystemSignalLongSymbol" SG_ 919 EPASTP_a019_rsthHwResetInfoCorru "EPASTP_a019_rsthHwResetInfoCorruptionCheck";
BA_ "SystemSignalLongSymbol" SG_ 919 EPASTP_a020_mcusscEolEcuIdIntegr "EPASTP_a020_mcusscEolEcuIdIntegritiyFail";
BA_ "SystemSignalLongSymbol" SG_ 919 EPASTP_a022_swrhSwResetInfoCorru "EPASTP_a022_swrhSwResetInfoCorruptionCheck";
BA_ "SystemSignalLongSymbol" SG_ 919 EPASTP_a028_smuhNonInitDataCorru "EPASTP_a028_smuhNonInitDataCorruption";
BA_ "SystemSignalLongSymbol" SG_ 919 EPASTP_a029_smuhSmuCoreCntErrorT "EPASTP_a029_smuhSmuCoreCntErrorTestFail";
BA_ "SystemSignalLongSymbol" SG_ 919 EPASTP_a031_pmsProductionModeFai "EPASTP_a031_pmsProductionModeFailed";
BA_ "SystemSignalLongSymbol" SG_ 919 EPASTP_a033_icsvcPswVersionMisma "EPASTP_a033_icsvcPswVersionMismatch";
BA_ "SystemSignalLongSymbol" SG_ 919 EPASTP_a038_csohCh1CsErrorErrAtR "EPASTP_a038_csohCh1CsErrorErrAtReset";
BA_ "SystemSignalLongSymbol" SG_ 919 EPASTP_a039_csohCh2CsErrorErrAtR "EPASTP_a039_csohCh2CsErrorErrAtReset";
BA_ "SystemSignalLongSymbol" SG_ 919 EPASTP_a040_swrhLimitedResetRetr "EPASTP_a040_swrhLimitedResetRetriesExpired";
BA_ "SystemSignalLongSymbol" SG_ 919 EPASTP_a041_imcmCoreConfiguratio "EPASTP_a041_imcmCoreConfigurationMismatch";
BA_ "SystemSignalLongSymbol" SG_ 919 EPASTP_a045_psumSbcBandgapVoltEr "EPASTP_a045_psumSbcBandgapVoltErr";
BA_ "SystemSignalLongSymbol" SG_ 919 EPASTP_a046_mcusscOscillatorNotR "EPASTP_a046_mcusscOscillatorNotReliable";
BA_ "SystemSignalLongSymbol" SG_ 919 EPASTP_a052_ermSdcInputBufferOve "EPASTP_a052_ermSdcInputBufferOverflow";
BA_ "SystemSignalLongSymbol" SG_ 919 EPASTP_a053_adcUnexpectedNumOfDa "EPASTP_a053_adcUnexpectedNumOfData";
BA_ "SystemSignalLongSymbol" SG_ 919 EPASTP_a056_amGduConfigCsErrorCh "EPASTP_a056_amGduConfigCsErrorCheck";
BA_ "SystemSignalLongSymbol" SG_ 919 EPASTP_a067_tspmPowermoduleTempI "EPASTP_a067_tspmPowermoduleTempImplausible";
BA_ "SystemSignalLongSymbol" SG_ 919 EPASTP_a068_rsthCoreRedundancyEr "EPASTP_a068_rsthCoreRedundancyErr";
BA_ "SystemSignalLongSymbol" SG_ 919 EPASTP_a069_rsthCoreTempOutOfRan "EPASTP_a069_rsthCoreTempOutOfRangeHwCheck";
BA_ "SystemSignalLongSymbol" SG_ 919 EPASTP_a072_rsthFlashUncorrEccOr "EPASTP_a072_rsthFlashUncorrEccOrOvfl";
BA_ "SystemSignalLongSymbol" SG_ 919 EPASTP_a075_rsthUnusedOtherModul "EPASTP_a075_rsthUnusedOtherModuleAlarm";
BA_ "SystemSignalLongSymbol" SG_ 919 EPASTP_a081_exchFloatingPointExc "EPASTP_a081_exchFloatingPointException";
BA_ "SystemSignalLongSymbol" SG_ 919 EPASTP_a083_tdaDclinkcapacitorTe "EPASTP_a083_tdaDclinkcapacitorTempChecker";
BA_ "SystemSignalLongSymbol" SG_ 919 EPASTP_a085_amGduSwitchOffTestBy "EPASTP_a085_amGduSwitchOffTestByMcu";
BA_ "SystemSignalLongSymbol" SG_ 919 EPASTP_a088_tedMainboardTempChec "EPASTP_a088_tedMainboardTempChecker";
BA_ "SystemSignalLongSymbol" SG_ 919 EPASTP_a089_tedRevercebattfetjun "EPASTP_a089_tedRevercebattfetjunctionTempChecker";
BA_ "SystemSignalLongSymbol" SG_ 919 EPASTP_a091_bvpBattVoltCrossChkF "EPASTP_a091_bvpBattVoltCrossChkFailed";
BA_ "SystemSignalLongSymbol" SG_ 919 EPASTP_a092_amGduSwitchOffTestBy "EPASTP_a092_amGduSwitchOffTestBySbc";
BA_ "SystemSignalLongSymbol" SG_ 919 EPASTP_a093_sctpTsuSingleStaticF "EPASTP_a093_sctpTsuSingleStaticFail";
BA_ "SystemSignalLongSymbol" SG_ 919 EPASTP_a094_sctpTsuMultipleStati "EPASTP_a094_sctpTsuMultipleStaticFail";
BA_ "SystemSignalLongSymbol" SG_ 919 EPASTP_a095_mdModelBasedMotorInt "EPASTP_a095_mdModelBasedMotorIntegrityCheck";
BA_ "SystemSignalLongSymbol" SG_ 919 EPASTP_a096_rppRpsSingleStaticFa "EPASTP_a096_rppRpsSingleStaticFail";
BA_ "SystemSignalLongSymbol" SG_ 919 EPASTP_a097_rppRpsMultipleStatic "EPASTP_a097_rppRpsMultipleStaticFail";
BA_ "SystemSignalLongSymbol" SG_ 919 EPASTP_a099_mcdTorqueMismatchFau "EPASTP_a099_mcdTorqueMismatchFault";
BA_ "SystemSignalLongSymbol" SG_ 919 EPASTP_a103_exhaUnusedInterruptC "EPASTP_a103_exhaUnusedInterruptCallException";
BA_ "SystemSignalLongSymbol" SG_ 919 EPASTP_a105_exhaSriBusErrExcepti "EPASTP_a105_exhaSriBusErrException";
BA_ "SystemSignalLongSymbol" SG_ 919 EPASTP_a106_exhaSpbBusErrExcepti "EPASTP_a106_exhaSpbBusErrException";
BA_ "SystemSignalLongSymbol" SG_ 919 EPASTP_a107_exhaOtherNmiExceptio "EPASTP_a107_exhaOtherNmiException";
BA_ "SystemSignalLongSymbol" SG_ 919 EPASTP_a108_exhaInternalProtecti "EPASTP_a108_exhaInternalProtectionException";
BA_ "SystemSignalLongSymbol" SG_ 919 EPASTP_a109_exhaSysBusOrPeriphEr "EPASTP_a109_exhaSysBusOrPeriphErrException";
BA_ "SystemSignalLongSymbol" SG_ 919 EPASTP_a110_amPhaseRelaySwitchOf "EPASTP_a110_amPhaseRelaySwitchOffTest";
BA_ "SystemSignalLongSymbol" SG_ 919 EPASTP_a111_amCurrentSensingDisc "EPASTP_a111_amCurrentSensingDisconnection";
BA_ "SystemSignalLongSymbol" SG_ 919 EPASTP_a112_rsthSafetyFlipflopEr "EPASTP_a112_rsthSafetyFlipflopErr";
BA_ "SystemSignalLongSymbol" SG_ 919 EPASTP_a113_rsthUncorrectableEnd "EPASTP_a113_rsthUncorrectableEndToEndBusErr";
BA_ "SystemSignalLongSymbol" SG_ 919 EPASTP_a115_mcusscLbistSingleFai "EPASTP_a115_mcusscLbistSingleFail";
BA_ "SystemSignalLongSymbol" SG_ 919 EPASTP_a116_mrccStartupRegCsErro "EPASTP_a116_mrccStartupRegCsErrorStaticErr";
BA_ "SystemSignalLongSymbol" SG_ 919 EPASTP_a117_mrccStartupRegCsErro "EPASTP_a117_mrccStartupRegCsErrorTransientErr";
BA_ "SystemSignalLongSymbol" SG_ 919 EPASTP_a118_mcusscFlashCsErrorEr "EPASTP_a118_mcusscFlashCsErrorErr";
BA_ "SystemSignalLongSymbol" SG_ 919 EPASTP_a119_mcusscFlashEccCritic "EPASTP_a119_mcusscFlashEccCriticalErr";
BA_ "SystemSignalLongSymbol" SG_ 919 EPASTP_a120_mcusscFlashEccLatent "EPASTP_a120_mcusscFlashEccLatentErr";
BA_ "SystemSignalLongSymbol" SG_ 919 EPASTP_a124_mcusscMbistEccTransi "EPASTP_a124_mcusscMbistEccTransientErr";
BA_ "SystemSignalLongSymbol" SG_ 919 EPASTP_a127_exchAdditionalExcept "EPASTP_a127_exchAdditionalExceptionAfterRst";
BA_ "SystemSignalLongSymbol" SG_ 919 EPASTP_a128_exchExceptionStopRes "EPASTP_a128_exchExceptionStopRestart";
BA_ "SystemSignalLongSymbol" SG_ 919 EPASTP_a129_exchAdditionalExcept "EPASTP_a129_exchAdditionalExceptionStopRestart";
BA_ "SystemSignalLongSymbol" SG_ 919 EPASTP_a131_exchGuardedResetAfte "EPASTP_a131_exchGuardedResetAfterPartitionStop";
BA_ "SystemSignalLongSymbol" SG_ 919 EPASTP_a132_mcusscNotSupportedMc "EPASTP_a132_mcusscNotSupportedMcu";
BA_ "SystemSignalLongSymbol" SG_ 919 EPASTP_a133_mcusscLbistEcuIdIsNo "EPASTP_a133_mcusscLbistEcuIdIsNotSupported";
BA_ "SystemSignalLongSymbol" SG_ 919 EPASTP_a134_osehGuardedResetAfte "EPASTP_a134_osehGuardedResetAfterErrWithoutReset";
BA_ "SystemSignalLongSymbol" SG_ 919 EPASTP_a135_tmpsfetjCalculationO "EPASTP_a135_tmpsfetjCalculationOverflowErr";
BA_ "SystemSignalLongSymbol" SG_ 919 EPASTP_a137_osehErrWithoutImmedi "EPASTP_a137_osehErrWithoutImmediateReset";
BA_ "SystemSignalLongSymbol" SG_ 919 EPASTP_a138_osehAdditionalErrWit "EPASTP_a138_osehAdditionalErrWithoutImmReset";
BA_ "SystemSignalLongSymbol" SG_ 919 EPASTP_a142_tedEmifilterDmcTempC "EPASTP_a142_tedEmifilterDmcTempChecker";
BA_ "SystemSignalLongSymbol" SG_ 919 EPASTP_a143_tedEmifilterCmcTempC "EPASTP_a143_tedEmifilterCmcTempChecker";
BA_ "SystemSignalLongSymbol" SG_ 919 EPASTP_a145_mriPeripheralRaminit "EPASTP_a145_mriPeripheralRaminitFailed";
BA_ "SystemSignalLongSymbol" SG_ 919 EPASTP_a148_mrccExitFromStandbyD "EPASTP_a148_mrccExitFromStandbyDetected";
BA_ "SystemSignalLongSymbol" SG_ 919 EPASTP_a149_amReversibleEmergenc "EPASTP_a149_amReversibleEmergencyOffRequested";
BA_ "SystemSignalLongSymbol" SG_ 919 EPASTP_a150_amExternalEmergencyO "EPASTP_a150_amExternalEmergencyOffRequested";
BA_ "SystemSignalLongSymbol" SG_ 919 EPASTP_a151_amPermanentEmergency "EPASTP_a151_amPermanentEmergencyOffRequested";
BA_ "SystemSignalLongSymbol" SG_ 919 EPASTP_a152_exchFlashEccExceptio "EPASTP_a152_exchFlashEccException";
BA_ "SystemSignalLongSymbol" SG_ 919 EPASTP_a153_sdsmBlockSelectorInv "EPASTP_a153_sdsmBlockSelectorInvalid";
BA_ "SystemSignalLongSymbol" SG_ 919 EPASTP_a154_sdsmCsErrorInvalidPr "EPASTP_a154_sdsmCsErrorInvalidPrimary";
BA_ "SystemSignalLongSymbol" SG_ 919 EPASTP_a156_amIntSerialErrSafety "EPASTP_a156_amIntSerialErrSafetyReset";
BA_ "SystemSignalLongSymbol" SG_ 919 EPASTP_a158_amGduFailDuringRecov "EPASTP_a158_amGduFailDuringRecovery";
BA_ "SystemSignalLongSymbol" SG_ 919 EPASTP_a159_exchFlashWordlineTra "EPASTP_a159_exchFlashWordlineTransientErr";
BA_ "SystemSignalLongSymbol" SG_ 919 EPASTP_a160_rsthCpu1UnexpectedAl "EPASTP_a160_rsthCpu1UnexpectedAlarm";
BA_ "SystemSignalLongSymbol" SG_ 919 EPASTP_a161_tdaRelayfetjunctionT "EPASTP_a161_tdaRelayfetjunctionTempChecker";
BA_ "SystemSignalLongSymbol" SG_ 919 EPASTP_a162_tdaBridgefetjunction "EPASTP_a162_tdaBridgefetjunctionTempChecker";
BA_ "SystemSignalLongSymbol" SG_ 919 EPASTP_a163_tdaPowermoduleTempCh "EPASTP_a163_tdaPowermoduleTempChecker";
BA_ "SystemSignalLongSymbol" SG_ 919 EPASTP_a164_tdaBattfetjunctionTe "EPASTP_a164_tdaBattfetjunctionTempChecker";
BA_ "SystemSignalLongSymbol" SG_ 919 EPASTP_a165_tdaDcbusshuntTempChe "EPASTP_a165_tdaDcbusshuntTempChecker";
BA_ "SystemSignalLongSymbol" SG_ 919 EPASTP_a166_tdaPhasecurrentshunt "EPASTP_a166_tdaPhasecurrentshuntTempChecker";
BA_ "SystemSignalLongSymbol" SG_ 919 EPASTP_a167_iccd1ErrQueueOverflo "EPASTP_a167_iccd1ErrQueueOverflow";
BA_ "SystemSignalLongSymbol" SG_ 919 EPASTP_a172_pmpElangMotorcurrent "EPASTP_a172_pmpElangMotorcurrentAge";
BA_ "SystemSignalLongSymbol" SG_ 919 EPASTP_a175_exchFlashStoredConfi "EPASTP_a175_exchFlashStoredConfigErr";
BA_ "SystemSignalLongSymbol" SG_ 919 EPASTP_a176_exchCpu1ExceptionRes "EPASTP_a176_exchCpu1ExceptionReset";
BA_ "SystemSignalLongSymbol" SG_ 919 EPASTP_a179_tedMotorcoilTempChec "EPASTP_a179_tedMotorcoilTempChecker";
BA_ "SystemSignalLongSymbol" SG_ 919 EPASTP_a180_dmDeadlineViolationC "EPASTP_a180_dmDeadlineViolationC1";
BA_ "SystemSignalLongSymbol" SG_ 919 EPASTP_a181_dmDeadlineViolationC "EPASTP_a181_dmDeadlineViolationC1";
BA_ "SystemSignalLongSymbol" SG_ 919 EPASTP_a184_sbcmCommBufferOverfl "EPASTP_a184_sbcmCommBufferOverflow";
BA_ "SystemSignalLongSymbol" SG_ 919 EPASTP_a185_sbcscpQAWatchdogRese "EPASTP_a185_sbcscpQAWatchdogReset";
BA_ "SystemSignalLongSymbol" SG_ 919 EPASTP_a186_wdhCommBufferOverflo "EPASTP_a186_wdhCommBufferOverflow";
BA_ "SystemSignalLongSymbol" SG_ 919 EPASTP_a188_epmCommBufferOverflo "EPASTP_a188_epmCommBufferOverflow";
BA_ "SystemSignalLongSymbol" SG_ 919 EPASTP_a190_sbchCommBufferOverfl "EPASTP_a190_sbchCommBufferOverflow";
BA_ "SystemSignalLongSymbol" SG_ 919 EPASTP_a191_sbcscpVcp2VucVoltFai "EPASTP_a191_sbcscpVcp2VucVoltFail";
BA_ "SystemSignalLongSymbol" SG_ 919 EPASTP_a196_topEolTasOffsetInval "EPASTP_a196_topEolTasOffsetInvalid";
BA_ "SystemSignalLongSymbol" SG_ 919 EPASTP_a200_ammInputBufferOverfl "EPASTP_a200_ammInputBufferOverflow";
BA_ "SystemSignalLongSymbol" SG_ 919 EPASTP_a201_ammOutputBufferOverf "EPASTP_a201_ammOutputBufferOverflow";
BA_ "SystemSignalLongSymbol" SG_ 919 EPASTP_a202_ohnvmpStoredOffsetLo "EPASTP_a202_ohnvmpStoredOffsetLost";
BA_ "SystemSignalLongSymbol" SG_ 919 EPASTP_a206_fdrOclPartialBlockin "EPASTP_a206_fdrOclPartialBlocking";
BA_ "SystemSignalLongSymbol" SG_ 919 EPASTP_a208_fdrLowSeverityBlocki "EPASTP_a208_fdrLowSeverityBlocking";
BA_ "SystemSignalLongSymbol" SG_ 919 EPASTP_a209_fdrLowSeverityFreezi "EPASTP_a209_fdrLowSeverityFreezing";
BA_ "SystemSignalLongSymbol" SG_ 919 EPASTP_a213_frmHighFrictionDetec "EPASTP_a213_frmHighFrictionDetected";
BA_ "SystemSignalLongSymbol" SG_ 919 EPASTP_a218_aadApplicationStateE "EPASTP_a218_aadApplicationStateErr";
BA_ "SystemSignalLongSymbol" SG_ 919 EPASTP_a258_pspInvalidProjectPar "EPASTP_a258_pspInvalidProjectParamset";
BA_ "SystemSignalLongSymbol" SG_ 919 EPASTP_a270_oscillationCompTrqLi "EPASTP_a270_oscillationCompTrqLimReached";
BA_ "Confidence" SG_ 909 ESP_party3Crc 0;
BA_ "Confidence" SG_ 909 ESP_party3Counter 0;
BA_ "Confidence" SG_ 909 ESP_absActive 0;
BA_ "Confidence" SG_ 909 ESP_vehicleStandstill 0;
BA_ "Confidence" SG_ 909 ESP_vehicleStandstillQF 0;
BA_ "Confidence" SG_ 909 ESP_pEstMaximum 0;
BA_ "Confidence" SG_ 909 ESP_privateVehicleSpd 0;
BA_ "Confidence" SG_ 909 ESP_decoupledBrakePressOffsetCom 0;
BA_ "GenSigSNA" SG_ 909 ESP_decoupledBrakePressOffsetCom "127";
BA_ "SystemSignalLongSymbol" SG_ 909 ESP_decoupledBrakePressOffsetCom "ESP_decoupledBrakePressOffsetComp";
BA_ "Confidence" SG_ 909 ESP_privateVehicleSpdQF 0;
BA_ "Confidence" SG_ 909 ESP_brakeMasterCylPress 0;
BA_ "GenSigSNA" SG_ 909 ESP_brakeMasterCylPress "1023";
BA_ "Confidence" SG_ 909 ESP_brakeMasterCylPressQF 0;
BA_ "Confidence" SG_ 325 ESP_statusChecksum 0;
BA_ "Confidence" SG_ 325 ESP_statusCounter 0;
BA_ "Confidence" SG_ 325 ESP_espModeActive 0;
BA_ "Confidence" SG_ 325 ESP_stabilityControlSts2 0;
BA_ "Confidence" SG_ 325 ESP_ebdFaultLamp 0;
BA_ "Confidence" SG_ 325 ESP_absFaultLamp 0;
BA_ "Confidence" SG_ 325 ESP_espFaultLamp 0;
BA_ "Confidence" SG_ 325 ESP_hydraulicBoostEnabled 0;
BA_ "Confidence" SG_ 325 ESP_espLampFlash 0;
BA_ "Confidence" SG_ 325 ESP_brakeLamp 0;
BA_ "Confidence" SG_ 325 ESP_absBrakeEvent2 0;
BA_ "Confidence" SG_ 325 ESP_longitudinalAccelQF 0;
BA_ "Confidence" SG_ 325 ESP_lateralAccelQF 0;
BA_ "Confidence" SG_ 325 ESP_yawRateQF 0;
BA_ "Confidence" SG_ 325 ESP_steeringAngleQF 0;
BA_ "Confidence" SG_ 325 ESP_brakeDiscWipingActive 0;
BA_ "Confidence" SG_ 325 ESP_driverBrakeApply 0;
BA_ "GenSigSNA" SG_ 325 ESP_driverBrakeApply "3";
BA_ "Confidence" SG_ 325 ESP_brakeApply 0;
BA_ "Confidence" SG_ 325 ESP_aesPrimaryActuatorStatus 0;
BA_ "Confidence" SG_ 325 ESP_cdpStatus 0;
BA_ "Confidence" SG_ 325 ESP_ptcTargetState 0;
BA_ "GenSigSNA" SG_ 325 ESP_ptcTargetState "3";
BA_ "Confidence" SG_ 325 ESP_btcTargetState 0;
BA_ "GenSigSNA" SG_ 325 ESP_btcTargetState "3";
BA_ "Confidence" SG_ 325 ESP_decoupledBrakePressEst 0;
BA_ "GenSigSNA" SG_ 325 ESP_decoupledBrakePressEst "255";
BA_ "Confidence" SG_ 325 ESP_ebrStandstillSkid 0;
BA_ "Confidence" SG_ 325 ESP_ebrStatus 0;
BA_ "Confidence" SG_ 325 ESP_brakeTorqueTarget 0;
BA_ "Confidence" SG_ 373 ESP_wheelSpeedFrL 1;
BA_ "Confidence" SG_ 373 ESP_wheelSpeedFrR 1;
BA_ "Confidence" SG_ 373 ESP_wheelSpeedReL 1;
BA_ "Confidence" SG_ 373 ESP_wheelSpeedReR 1;
BA_ "Confidence" SG_ 925 IBST_statusChecksum 0;
BA_ "Confidence" SG_ 925 IBST_statusCounter 0;
BA_ "Confidence" SG_ 925 IBST_iBoosterStatus 0;
BA_ "Confidence" SG_ 925 IBST_driverBrakeApply 0;
BA_ "Confidence" SG_ 925 IBST_internalState 0;
BA_ "Confidence" SG_ 925 IBST_sInputRodDriver 0;
BA_ "Confidence" SG_ 925 IBST_LVPowerModeState 0;
BA_ "Confidence" SG_ 1316 PMF_processorDieIdLot 0;
BA_ "Confidence" SG_ 1316 PMF_processorDieIdWafer 0;
BA_ "Confidence" SG_ 1316 PMF_processorDieIdX 0;
BA_ "Confidence" SG_ 1316 PMF_processorDieIdY 0;
BA_ "Confidence" SG_ 1364 PMR_processorDieIdLot 0;
BA_ "Confidence" SG_ 1364 PMR_processorDieIdWafer 0;
BA_ "Confidence" SG_ 1364 PMR_processorDieIdX 0;
BA_ "Confidence" SG_ 1364 PMR_processorDieIdY 0;
BA_ "Confidence" SG_ 1973 PM_itpmsDisplaySelector 1;
BA_ "Confidence" SG_ 1973 PM_indirectTPMSTellTale 0;
BA_ "Confidence" SG_ 1973 PM_indirectTPMSDisplayState 0;
BA_ "Confidence" SG_ 1973 PM_indirectTPMSDisplayProgress 0;
BA_ "Confidence" SG_ 1973 PM_indirectTPMSDisplayWarningInd 0;
BA_ "SystemSignalLongSymbol" SG_ 1973 PM_indirectTPMSDisplayWarningInd "PM_indirectTPMSDisplayWarningIndicatorFL";
BA_ "Confidence" SG_ 1973 PM_indirectTPMSDisplayWarni_0001 0;
BA_ "SystemSignalLongSymbol" SG_ 1973 PM_indirectTPMSDisplayWarni_0001 "PM_indirectTPMSDisplayWarningIndicatorFR";
BA_ "Confidence" SG_ 1973 PM_indirectTPMSDisplayWarni_0002 0;
BA_ "SystemSignalLongSymbol" SG_ 1973 PM_indirectTPMSDisplayWarni_0002 "PM_indirectTPMSDisplayWarningIndicatorRL";
BA_ "Confidence" SG_ 1973 PM_indirectTPMSDisplayWarni_0003 0;
BA_ "SystemSignalLongSymbol" SG_ 1973 PM_indirectTPMSDisplayWarni_0003 "PM_indirectTPMSDisplayWarningIndicatorRR";
BA_ "Confidence" SG_ 1973 PM_indirectTPMSRecommendedColdPr 0;
BA_ "GenSigSNA" SG_ 1973 PM_indirectTPMSRecommendedColdPr "255";
BA_ "SystemSignalLongSymbol" SG_ 1973 PM_indirectTPMSRecommendedColdPr "PM_indirectTPMSRecommendedColdPressureFront";
BA_ "Confidence" SG_ 1973 PM_indirectTPMSRecommendedC_0001 0;
BA_ "GenSigSNA" SG_ 1973 PM_indirectTPMSRecommendedC_0001 "255";
BA_ "SystemSignalLongSymbol" SG_ 1973 PM_indirectTPMSRecommendedC_0001 "PM_indirectTPMSRecommendedColdPressureRear";
BA_ "Confidence" SG_ 1973 PM_fusedPressureEstimateFrL 0;
BA_ "Confidence" SG_ 1973 PM_fusedPressureEstimateFrR 0;
BA_ "Confidence" SG_ 1973 PM_fusedPressureEstimateReL 0;
BA_ "Confidence" SG_ 1973 PM_fusedPressureEstimateReR 0;
BA_ "Confidence" SG_ 2038 PM_vdcDebugSelector 1;
BA_ "Confidence" SG_ 2038 PM_VDCA_TCSlipTargetMod_RA_Fwd 0;
BA_ "Confidence" SG_ 2038 PM_VDCA_TCSlipTargetMod_RA_Rwd 0;
BA_ "Confidence" SG_ 2038 PM_VSE_forceY_RA 0;
BA_ "Confidence" SG_ 2038 PM_VDCT_observerSlipAngle_RA 0;
BA_ "Confidence" SG_ 2038 PM_VSE_muVehicleFxLow 0;
BA_ "Confidence" SG_ 2038 PM_VE_fxmFres 0;
BA_ "Confidence" SG_ 2038 PM_VE_fxAccelMass 0;
BA_ "Confidence" SG_ 2038 PM_VE_vxDotGrade 0;
BA_ "Confidence" SG_ 2038 PM_VE_betaEst 0;
BA_ "Confidence" SG_ 2038 PM_VSE_muVehicleFxHigh 0;
BA_ "Confidence" SG_ 2038 PM_VSE_muVehicleDecLeakRate 0;
BA_ "Confidence" SG_ 2038 PM_VSE_muVehicleLearnDown 0;
BA_ "Confidence" SG_ 2038 PM_VSE_muVehicleDecFilter 0;
BA_ "Confidence" SG_ 2038 PM_VSE_muVehicleLatDecLeakRate 0;
BA_ "Confidence" SG_ 2038 PM_VSE_splitMuProbability 0;
BA_ "Confidence" SG_ 2038 PM_VSE_splitMuTotalMz 0;
BA_ "Confidence" SG_ 2038 PM_VSE_attitudeBankAngle 0;
BA_ "Confidence" SG_ 2038 PM_VSE_attitudeDBetaInControl 0;
BA_ "Confidence" SG_ 2038 PM_VSE_roadWheelAngleAverage 0;
BA_ "Confidence" SG_ 17 RCM_collisionChecksum 0;
BA_ "Confidence" SG_ 17 RCM_collisionCounter 0;
BA_ "Confidence" SG_ 17 RCM_collisionRear 0;
BA_ "GenSigSNA" SG_ 17 RCM_collisionRear "3";
BA_ "Confidence" SG_ 17 RCM_collisionRight 0;
BA_ "GenSigSNA" SG_ 17 RCM_collisionRight "3";
BA_ "Confidence" SG_ 17 RCM_collisionLeft 0;
BA_ "GenSigSNA" SG_ 17 RCM_collisionLeft "3";
BA_ "Confidence" SG_ 17 RCM_collisionFront 0;
BA_ "GenSigSNA" SG_ 17 RCM_collisionFront "3";
BA_ "Confidence" SG_ 17 RCM_collisionRollover 0;
BA_ "GenSigSNA" SG_ 17 RCM_collisionRollover "3";
BA_ "Confidence" SG_ 17 RCM_collisionPedPro 0;
BA_ "GenSigSNA" SG_ 17 RCM_collisionPedPro "3";
BA_ "Confidence" SG_ 17 RCM_collisionSeverity 0;
BA_ "Confidence" SG_ 289 RCM_nearDeployChecksum 0;
BA_ "Confidence" SG_ 289 RCM_nearDeployCounter 0;
BA_ "Confidence" SG_ 289 RCM_nearDeployRear 0;
BA_ "GenSigSNA" SG_ 289 RCM_nearDeployRear "3";
BA_ "Confidence" SG_ 289 RCM_nearDeployRight 0;
BA_ "GenSigSNA" SG_ 289 RCM_nearDeployRight "3";
BA_ "Confidence" SG_ 289 RCM_nearDeployLeft 0;
BA_ "GenSigSNA" SG_ 289 RCM_nearDeployLeft "3";
BA_ "Confidence" SG_ 289 RCM_nearDeployFront 0;
BA_ "GenSigSNA" SG_ 289 RCM_nearDeployFront "3";
BA_ "Confidence" SG_ 289 RCM_nearDeployRollover 0;
BA_ "GenSigSNA" SG_ 289 RCM_nearDeployRollover "3";
BA_ "Confidence" SG_ 289 RCM_crashAlgoWakeup 0;
BA_ "GenSigSNA" SG_ 289 RCM_crashAlgoWakeup "3";
BA_ "Confidence" SG_ 1618 VCBATT0_infoIndex 1;
BA_ "Confidence" SG_ 1618 VCBATT0_infoBuildType 0;
BA_ "Confidence" SG_ 1618 VCBATT0_infoBuildConfigId 0;
BA_ "Confidence" SG_ 1618 VCBATT0_infoHardwareId 0;
BA_ "Confidence" SG_ 1618 VCBATT0_infoComponentId 0;
BA_ "Confidence" SG_ 1618 VCBATT0_infoPcbaId 0;
BA_ "Confidence" SG_ 1618 VCBATT0_infoAssemblyId 0;
BA_ "GenSigSNA" SG_ 1618 VCBATT0_infoAssemblyId "255";
BA_ "Confidence" SG_ 1618 VCBATT0_infoUsageId 0;
BA_ "Confidence" SG_ 1618 VCBATT0_infoSubUsageId 0;
BA_ "Confidence" SG_ 1618 VCBATT0_infoAppCrc 0;
BA_ "Confidence" SG_ 1618 VCBATT0_infoAppGitHash 0;
BA_ "Confidence" SG_ 1618 VCBATT0_infoBootGitHash 0;
BA_ "Confidence" SG_ 1618 VCBATT0_infoBootUdsProtoVersion 0;
BA_ "Confidence" SG_ 1618 VCBATT0_infoBootCrc 0;
BA_ "Confidence" SG_ 1994 VCCC_infoIndex 1;
BA_ "Confidence" SG_ 1994 VCCC_infoBuildType 0;
BA_ "Confidence" SG_ 1994 VCCC_infoBuildConfigId 0;
BA_ "Confidence" SG_ 1994 VCCC_infoHardwareId 0;
BA_ "Confidence" SG_ 1994 VCCC_infoComponentId 0;
BA_ "Confidence" SG_ 1994 VCCC_infoPcbaId 0;
BA_ "Confidence" SG_ 1994 VCCC_infoAssemblyId 0;
BA_ "GenSigSNA" SG_ 1994 VCCC_infoAssemblyId "255";
BA_ "Confidence" SG_ 1994 VCCC_infoUsageId 0;
BA_ "Confidence" SG_ 1994 VCCC_infoSubUsageId 0;
BA_ "Confidence" SG_ 1994 VCCC_infoAppCrc 0;
BA_ "Confidence" SG_ 1994 VCCC_infoAppGitHash 0;
BA_ "Confidence" SG_ 1994 VCCC_infoBootGitHash 0;
BA_ "Confidence" SG_ 1994 VCCC_infoBootUdsProtoVersion 0;
BA_ "Confidence" SG_ 1994 VCCC_infoBootCrc 0;
BA_ "Confidence" SG_ 260 VCFRONT_vcleftHighPower 0;
BA_ "Confidence" SG_ 260 VCFRONT_vcrightHighPower 0;
BA_ "Confidence" SG_ 260 VCFRONT_uiHighPower 0;
BA_ "Confidence" SG_ 260 VCFRONT_5VAStable 0;
BA_ "Confidence" SG_ 260 VCFRONT_5VBStable 0;
BA_ "Confidence" SG_ 260 VCFRONT_12VAStable 0;
BA_ "Confidence" SG_ 260 VCFRONT_12VBStable 0;
BA_ "Confidence" SG_ 260 VCFRONT_railA 0;
BA_ "Confidence" SG_ 260 VCFRONT_railB 0;
BA_ "Confidence" SG_ 260 VCFRONT_chargePumpStable 0;
BA_ "Confidence" SG_ 260 VCFRONT_vehicleSM 0;
BA_ "GenSigSNA" SG_ 260 VCFRONT_vehicleSM "18";
BA_ "Confidence" SG_ 260 VCFRONT_revBattFault 0;
BA_ "Confidence" SG_ 260 VCFRONT_battSM 0;
BA_ "Confidence" SG_ 260 VCFRONT_U13Init 0;
BA_ "Confidence" SG_ 260 VCFRONT_U16Init 0;
BA_ "Confidence" SG_ 260 VCFRONT_anyVehLoadShedActiveDBG 0;
BA_ "Confidence" SG_ 260 VCFRONT_battVoltage 0;
BA_ "Confidence" SG_ 260 VCFRONT_battCurrent 0;
BA_ "Confidence" SG_ 258 VCLEFT_doorClosureStatusFront 0;
BA_ "GenSigSNA" SG_ 258 VCLEFT_doorClosureStatusFront "0";
BA_ "Confidence" SG_ 258 VCLEFT_doorClosureStatusRear 0;
BA_ "GenSigSNA" SG_ 258 VCLEFT_doorClosureStatusRear "0";
BA_ "Confidence" SG_ 258 VCLEFT_frontLatchSwitch 0;
BA_ "Confidence" SG_ 258 VCLEFT_rearLatchSwitch 0;
BA_ "Confidence" SG_ 258 VCLEFT_frontHandlePulled 0;
BA_ "Confidence" SG_ 258 VCLEFT_rearHandlePulled 0;
BA_ "Confidence" SG_ 258 VCLEFT_frontRelActuatorSwitch 0;
BA_ "Confidence" SG_ 258 VCLEFT_rearRelActuatorSwitch 0;
BA_ "Confidence" SG_ 258 VCLEFT_frontLatchStatus 0;
BA_ "GenSigSNA" SG_ 258 VCLEFT_frontLatchStatus "0";
BA_ "Confidence" SG_ 258 VCLEFT_rearLatchStatus 0;
BA_ "GenSigSNA" SG_ 258 VCLEFT_rearLatchStatus "0";
BA_ "Confidence" SG_ 258 VCLEFT_lastDoorReqSourceFront 0;
BA_ "Confidence" SG_ 258 VCLEFT_lastDoorReqSourceRear 0;
BA_ "Confidence" SG_ 258 VCLEFT_frontIntSwitchFaulted 0;
BA_ "Confidence" SG_ 258 VCLEFT_rearIntSwitchFaulted 0;
BA_ "Confidence" SG_ 258 VCLEFT_frontIntSwitchPressed 0;
BA_ "Confidence" SG_ 258 VCLEFT_rearIntSwitchPressed 0;
BA_ "Confidence" SG_ 258 VCLEFT_mirrorTiltXPosition 0;
BA_ "Confidence" SG_ 258 VCLEFT_mirrorTiltYPosition 0;
BA_ "Confidence" SG_ 258 VCLEFT_mirrorState 0;
BA_ "Confidence" SG_ 258 VCLEFT_mirrorFoldState 0;
BA_ "Confidence" SG_ 258 VCLEFT_mirrorRecallState 0;
BA_ "Confidence" SG_ 258 VCLEFT_mirrorHeatState 0;
BA_ "GenSigSNA" SG_ 258 VCLEFT_mirrorHeatState "0";
BA_ "Confidence" SG_ 258 VCLEFT_rearHandlePulledPersist 0;
BA_ "Confidence" SG_ 258 VCLEFT_frontHandlePulledPersist 0;
BA_ "Confidence" SG_ 258 VCLEFT_mirrorDipped 0;
BA_ "Confidence" SG_ 546 VCLEFT_cdpRequestState 0;
BA_ "Confidence" SG_ 546 VCLEFT_epbmSystemStatusQF 0;
BA_ "Confidence" SG_ 546 VCLEFT_epbmUnitStatus 0;
BA_ "Confidence" SG_ 546 VCLEFT_epbmCdpState 0;
BA_ "Confidence" SG_ 546 VCLEFT_epbmRedundantBrakingEnabl 0;
BA_ "SystemSignalLongSymbol" SG_ 546 VCLEFT_epbmRedundantBrakingEnabl "VCLEFT_epbmRedundantBrakingEnabled";
BA_ "Confidence" SG_ 546 VCLEFT_epbmStatusCounter 0;
BA_ "Confidence" SG_ 546 VCLEFT_epbmStatusChecksum 0;
BA_ "Confidence" SG_ 778 VCLEFT_frontOccupancyStatus 0;
BA_ "GenSigSNA" SG_ 778 VCLEFT_frontOccupancyStatus "7";
BA_ "Confidence" SG_ 778 VCLEFT_frontBuckleStatus 0;
BA_ "Confidence" SG_ 778 VCLEFT_rearLeftOccupancyStatus 0;
BA_ "Confidence" SG_ 778 VCLEFT_rearCenterOccupancyStatus 0;
BA_ "Confidence" SG_ 778 VCLEFT_rearRightOccupancyStatus 0;
BA_ "Confidence" SG_ 778 VCLEFT_rearLeftBuckleStatus 0;
BA_ "Confidence" SG_ 778 VCLEFT_rearCenterBuckleStatus 0;
BA_ "Confidence" SG_ 778 VCLEFT_seatTrackPosition 0;
BA_ "GenSigSNA" SG_ 778 VCLEFT_seatTrackPosition "7";
BA_ "Confidence" SG_ 778 VCLEFT_3RowLeftABStatus 0;
BA_ "GenSigSNA" SG_ 778 VCLEFT_3RowLeftABStatus "2";
BA_ "Confidence" SG_ 778 VCLEFT_3RowLeftBuckleStatus 0;
BA_ "Confidence" SG_ 778 VCLEFT_restraintStatusCounter 0;
BA_ "Confidence" SG_ 778 VCLEFT_restraintStatusChecksum 0;
BA_ "Confidence" SG_ 1124 VCRIGHT_AP_hvacState1HzIndex 1;
BA_ "Confidence" SG_ 1124 VCRIGHT_AP_tempCameraModele_0001 0;
BA_ "GenSigSNA" SG_ 1124 VCRIGHT_AP_tempCameraModele_0001 "255";
BA_ "SystemSignalLongSymbol" SG_ 1124 VCRIGHT_AP_tempCameraModele_0001 "VCRIGHT_AP_tempCameraModeledWindshieldOut";
BA_ "Confidence" SG_ 1124 VCRIGHT_AP_tempCameraModeledWind 0;
BA_ "GenSigSNA" SG_ 1124 VCRIGHT_AP_tempCameraModeledWind "255";
BA_ "SystemSignalLongSymbol" SG_ 1124 VCRIGHT_AP_tempCameraModeledWind "VCRIGHT_AP_tempCameraModeledWindshieldIn";
BA_ "Confidence" SG_ 1124 VCRIGHT_AP_cameraModeledWin_0001 0;
BA_ "GenSigSNA" SG_ 1124 VCRIGHT_AP_cameraModeledWin_0001 "127";
BA_ "SystemSignalLongSymbol" SG_ 1124 VCRIGHT_AP_cameraModeledWin_0001 "VCRIGHT_AP_cameraModeledWindshieldOutRh";
BA_ "Confidence" SG_ 1124 VCRIGHT_AP_cameraModeledWindshie 0;
BA_ "GenSigSNA" SG_ 1124 VCRIGHT_AP_cameraModeledWindshie "127";
BA_ "SystemSignalLongSymbol" SG_ 1124 VCRIGHT_AP_cameraModeledWindshie "VCRIGHT_AP_cameraModeledWindshieldInRh";
BA_ "Confidence" SG_ 1124 VCRIGHT_AP_maxAchievableASideTem 0;
BA_ "SystemSignalLongSymbol" SG_ 1124 VCRIGHT_AP_maxAchievableASideTem "VCRIGHT_AP_maxAchievableASideTempCameraPocket";
BA_ "Confidence" SG_ 1124 VCRIGHT_AP_cameraModeledPocketWa 0;
BA_ "GenSigSNA" SG_ 1124 VCRIGHT_AP_cameraModeledPocketWa "1023";
BA_ "SystemSignalLongSymbol" SG_ 1124 VCRIGHT_AP_cameraModeledPocketWa "VCRIGHT_AP_cameraModeledPocketWaterMass";
BA_ "Confidence" SG_ 1124 VCRIGHT_AP_humidityModelInitStat 0;
BA_ "SystemSignalLongSymbol" SG_ 1124 VCRIGHT_AP_humidityModelInitStat "VCRIGHT_AP_humidityModelInitStatus";
BA_ "Confidence" SG_ 1124 VCRIGHT_AP_humidityModelStatus 0;
BA_ "Confidence" SG_ 259 VCRIGHT_doorClosureStatusFront 0;
BA_ "GenSigSNA" SG_ 259 VCRIGHT_doorClosureStatusFront "0";
BA_ "Confidence" SG_ 259 VCRIGHT_doorClosureStatusRear 0;
BA_ "GenSigSNA" SG_ 259 VCRIGHT_doorClosureStatusRear "0";
BA_ "Confidence" SG_ 259 VCRIGHT_frontLatchSwitch 0;
BA_ "Confidence" SG_ 259 VCRIGHT_rearLatchSwitch 0;
BA_ "Confidence" SG_ 259 VCRIGHT_frontHandlePulled 0;
BA_ "Confidence" SG_ 259 VCRIGHT_rearHandlePulled 0;
BA_ "Confidence" SG_ 259 VCRIGHT_frontRelActuatorSwitch 0;
BA_ "Confidence" SG_ 259 VCRIGHT_rearRelActuatorSwitch 0;
BA_ "Confidence" SG_ 259 VCRIGHT_frontLatchStatus 0;
BA_ "GenSigSNA" SG_ 259 VCRIGHT_frontLatchStatus "0";
BA_ "Confidence" SG_ 259 VCRIGHT_rearLatchStatus 0;
BA_ "GenSigSNA" SG_ 259 VCRIGHT_rearLatchStatus "0";
BA_ "Confidence" SG_ 259 VCRIGHT_lastDoorReqSourceFront 0;
BA_ "Confidence" SG_ 259 VCRIGHT_lastDoorReqSourceRear 0;
BA_ "Confidence" SG_ 259 VCRIGHT_frontIntSwitchFaulted 0;
BA_ "Confidence" SG_ 259 VCRIGHT_rearIntSwitchFaulted 0;
BA_ "Confidence" SG_ 259 VCRIGHT_frontHandlePulledPersist 0;
BA_ "Confidence" SG_ 259 VCRIGHT_frontIntSwitchPressed 0;
BA_ "Confidence" SG_ 259 VCRIGHT_rearIntSwitchPressed 0;
BA_ "Confidence" SG_ 259 VCRIGHT_mirrorTiltXPosition 0;
BA_ "Confidence" SG_ 259 VCRIGHT_mirrorTiltYPosition 0;
BA_ "Confidence" SG_ 259 VCRIGHT_mirrorState 0;
BA_ "Confidence" SG_ 259 VCRIGHT_mirrorFoldState 0;
BA_ "Confidence" SG_ 259 VCRIGHT_mirrorDipped 0;
BA_ "Confidence" SG_ 259 VCRIGHT_trunkLatchStatus 0;
BA_ "GenSigSNA" SG_ 259 VCRIGHT_trunkLatchStatus "0";
BA_ "Confidence" SG_ 259 VCRIGHT_mirrorRecallState 0;
BA_ "Confidence" SG_ 259 VCRIGHT_rearHandlePulledPersist 0;
BA_ "Confidence" SG_ 611 VCRIGHT_cdpRequestState 0;
BA_ "Confidence" SG_ 611 VCRIGHT_epbmSystemStatusQF 0;
BA_ "Confidence" SG_ 611 VCRIGHT_epbmUnitStatus 0;
BA_ "Confidence" SG_ 611 VCRIGHT_epbmCdpState 0;
BA_ "Confidence" SG_ 611 VCRIGHT_epbmRedundantBrakingEnab 0;
BA_ "SystemSignalLongSymbol" SG_ 611 VCRIGHT_epbmRedundantBrakingEnab "VCRIGHT_epbmRedundantBrakingEnabled";
BA_ "Confidence" SG_ 611 VCRIGHT_epbmStatusCounter 0;
BA_ "Confidence" SG_ 611 VCRIGHT_epbmStatusChecksum 0;
BA_ "Confidence" SG_ 794 VCRIGHT_frontOccupancyStatus 0;
BA_ "GenSigSNA" SG_ 794 VCRIGHT_frontOccupancyStatus "7";
BA_ "Confidence" SG_ 794 VCRIGHT_frontBuckleStatus 0;
BA_ "Confidence" SG_ 794 VCRIGHT_rearCenterBuckleStatus 0;
BA_ "Confidence" SG_ 794 VCRIGHT_rearRightBuckleStatus 0;
BA_ "Confidence" SG_ 794 VCRIGHT_rearRightOccupancyStatus 0;
BA_ "Confidence" SG_ 794 VCRIGHT_3RowLeftBuckleStatus 0;
BA_ "Confidence" SG_ 794 VCRIGHT_3RowRightBuckleStatus 0;
BA_ "Confidence" SG_ 794 VCRIGHT_3RowLeftOccupancyStatus 0;
BA_ "Confidence" SG_ 794 VCRIGHT_3RowRightOccupancyStatus 0;
BA_ "Confidence" SG_ 794 VCRIGHT_seatTrackPosition 0;
BA_ "GenSigSNA" SG_ 794 VCRIGHT_seatTrackPosition "7";
BA_ "Confidence" SG_ 794 VCRIGHT_occupantClassification 0;
BA_ "GenSigSNA" SG_ 794 VCRIGHT_occupantClassification "7";
BA_ "Confidence" SG_ 794 VCRIGHT_occupantClassificationQF 0;
BA_ "Confidence" SG_ 794 VCRIGHT_classificationEnabled 0;
BA_ "Confidence" SG_ 794 VCRIGHT_classificationEnabledQF 0;
BA_ "Confidence" SG_ 794 VCRIGHT_3RowRightABStatus 0;
BA_ "GenSigSNA" SG_ 794 VCRIGHT_3RowRightABStatus "2";
BA_ "Confidence" SG_ 794 VCRIGHT_restraintStatusCounter 0;
BA_ "Confidence" SG_ 794 VCRIGHT_restraintStatusChecksum 0;
VAL_ 1427 EPASTP_alertID 270 "a270_oscillationCompTrqLimReached" 269 "a269_assistTorqueDisabled" 268 "a268_eacCancelled" 267 "a267_safeSpeedAssist" 266 "a266_overloadProtect" 265 "a265_overheatProtect" 264 "a264_assistTorqueLimited" 263 "a263_espWsStatus" 262 "a262_yawRateStatus" 261 "a261_sccmStatusError" 260 "a260_scoPrivateBusOff" 259 "a259_scoCanBusOff" 258 "a258_pspInvalidProjectParamset" 257 "a257_dcvmUnderVolt" 256 "a256_dcvmOverVolt" 255 "a255_pmState2Mia" 254 "a254_vcFrontMia" 253 "a253_vcFrontCsError" 252 "a252_vcFrontCntError" 251 "a251_uiTuneReqMia" 250 "a250_uiTuneReqCsError" 249 "a249_uiTuneReqCntError" 248 "a248_sccmMia" 247 "a247_sccmCsError" 246 "a246_sccmCntError" 245 "a245_rcmMia" 244 "a244_rcmCsError" 243 "a243_rcmCntError" 242 "a242_gtwConfigMia" 241 "a241_espWsMia" 240 "a240_espWsCsError" 239 "a239_espWsCntError" 238 "a238_espWrMia" 237 "a237_espWrCsError" 236 "a236_espWrCntError" 235 "a235_ecu2StatMia" 234 "a234_ecu2StatCsError" 233 "a233_ecu2StatCntError" 232 "a232_diSpdMia" 231 "a231_diSpdCsError" 230 "a230_diSpdCntError" 229 "a229_dirTorqueMia" 228 "a228_dirTorqueCsError" 227 "a227_dirTorqueCntError" 226 "a226_dasMia" 225 "a225_dasCsError" 224 "a224_dasCntError" 223 "a223_apsMia" 222 "a222_apsCsError" 221 "a221_apsCntError" 219 "a219_frhFastRestartFailed" 218 "a218_aadApplicationStateErr" 217 "a217_msdMasterSilentErr" 216 "a216_isdgImproperShutdown" 215 "a215_vsgSafeViolErr" 214 "a214_velInterfaceErr" 213 "a213_frmHighFrictionDetected" 212 "a212_frmDataLost" 211 "a211_frmInternalErr" 210 "a210_fdrTotalBlocking" 209 "a209_fdrLowSeverityFreezing" 208 "a208_fdrLowSeverityBlocking" 207 "a207_fdrOclFreezing" 206 "a206_fdrOclPartialBlocking" 205 "a205_fdrOclFail" 204 "a204_fdpPrevTrqErr" 203 "a203_ctcInterfaceErr" 202 "a202_ohnvmpStoredOffsetLost" 201 "a201_ammOutputBufferOverflow" 200 "a200_ammInputBufferOverflow" 199 "a199_osumC1StackNearFull" 198 "a198_osumC1CsaNearFull" 197 "a197_difpDifactorInvalid" 196 "a196_topEolTasOffsetInvalid" 195 "a195_imcmCommErrC1" 194 "a194_amNvdataLoss" 193 "a193_osumC0StackNearFull" 192 "a192_osumC0CsaNearFull" 191 "a191_sbcscpVcp2VucVoltFail" 190 "a190_sbchCommBufferOverflow" 189 "a189_sbchCommErrMcuToSbc" 188 "a188_epmCommBufferOverflow" 187 "a187_epmVoltFail" 186 "a186_wdhCommBufferOverflow" 185 "a185_sbcscpQAWatchdogReset" 184 "a184_sbcmCommBufferOverflow" 183 "a183_sbchCommErrSbcToMcu" 182 "a182_mcdInputMia" 181 "a181_dmDeadlineViolationC1" 180 "a180_dmDeadlineViolationC1" 179 "a179_tedMotorcoilTempChecker" 178 "a178_exchWdtException" 177 "a177_etsrInvalidated" 176 "a176_exchCpu1ExceptionReset" 175 "a175_exchFlashStoredConfigErr" 174 "a174_pmpPhasecurrentAge" 173 "a173_pmpRotorspeedAge" 172 "a172_pmpElangMotorcurrentAge" 171 "a171_pmpKgvalueAge" 170 "a170_pmpDcvoltAge" 169 "a169_scpSafetyReset" 168 "a168_c1csInvalidC1App" 167 "a167_iccd1ErrQueueOverflow" 166 "a166_tdaPhasecurrentshuntTempChecker" 165 "a165_tdaDcbusshuntTempChecker" 164 "a164_tdaBattfetjunctionTempChecker" 163 "a163_tdaPowermoduleTempChecker" 162 "a162_tdaBridgefetjunctionTempChecker" 161 "a161_tdaRelayfetjunctionTempChecker" 160 "a160_rsthCpu1UnexpectedAlarm" 159 "a159_exchFlashWordlineTransientErr" 158 "a158_amGduFailDuringRecovery" 157 "a157_mcudcpInvalidEcuId" 156 "a156_amIntSerialErrSafetyReset" 155 "a155_sdsmDataInvalidAll" 154 "a154_sdsmCsErrorInvalidPrimary" 153 "a153_sdsmBlockSelectorInvalid" 152 "a152_exchFlashEccException" 151 "a151_amPermanentEmergencyOffRequested" 150 "a150_amExternalEmergencyOffRequested" 149 "a149_amReversibleEmergencyOffRequested" 148 "a148_mrccExitFromStandbyDetected" 147 "a147_amDcLinkShortedFail" 146 "a146_btarcRcCircuitCheck" 145 "a145_mriPeripheralRaminitFailed" 144 "a144_mriCoreRaminitFailed" 143 "a143_tedEmifilterCmcTempChecker" 142 "a142_tedEmifilterDmcTempChecker" 141 "a141_amFetShortTest" 140 "a140_imcmConfigurationErr" 139 "a139_osehAdditionalOsErr" 138 "a138_osehAdditionalErrWithoutImmReset" 137 "a137_osehErrWithoutImmediateReset" 136 "a136_ftElectricalAngleQf" 135 "a135_tmpsfetjCalculationOverflowErr" 134 "a134_osehGuardedResetAfterErrWithoutReset" 133 "a133_mcusscLbistEcuIdIsNotSupported" 132 "a132_mcusscNotSupportedMcu" 131 "a131_exchGuardedResetAfterPartitionStop" 130 "a130_mrccConfigCsErrorErr" 129 "a129_exchAdditionalExceptionStopRestart" 128 "a128_exchExceptionStopRestart" 127 "a127_exchAdditionalExceptionAfterRst" 126 "a126_mcusscMonbistMiaErr" 125 "a125_mcusscMbistMiaErr" 124 "a124_mcusscMbistEccTransientErr" 123 "a123_imcmCommErr" 122 "a122_pcpBridgeFetShort" 121 "a121_mcusscMbistEccErr" 120 "a120_mcusscFlashEccLatentErr" 119 "a119_mcusscFlashEccCriticalErr" 118 "a118_mcusscFlashCsErrorErr" 117 "a117_mrccStartupRegCsErrorTransientErr" 116 "a116_mrccStartupRegCsErrorStaticErr" 115 "a115_mcusscLbistSingleFail" 114 "a114_osehOsErr" 113 "a113_rsthUncorrectableEndToEndBusErr" 112 "a112_rsthSafetyFlipflopErr" 111 "a111_amCurrentSensingDisconnection" 110 "a110_amPhaseRelaySwitchOffTest" 109 "a109_exhaSysBusOrPeriphErrException" 108 "a108_exhaInternalProtectionException" 107 "a107_exhaOtherNmiException" 106 "a106_exhaSpbBusErrException" 105 "a105_exhaSriBusErrException" 104 "a104_exhaBusMpuException" 103 "a103_exhaUnusedInterruptCallException" 102 "a102_amPhasecurrentQosErr" 101 "a101_sdrvSpcIdMismatch" 100 "a100_amVbrgLssFault" 99 "a099_mcdTorqueMismatchFault" 98 "a098_invErr" 97 "a097_rppRpsMultipleStaticFail" 96 "a096_rppRpsSingleStaticFail" 95 "a095_mdModelBasedMotorIntegrityCheck" 94 "a094_sctpTsuMultipleStaticFail" 93 "a093_sctpTsuSingleStaticFail" 92 "a092_amGduSwitchOffTestBySbc" 91 "a091_bvpBattVoltCrossChkFailed" 90 "a090_etsmWarning" 89 "a089_tedRevercebattfetjunctionTempChecker" 88 "a088_tedMainboardTempChecker" 87 "a087_rsthFlashConfigErr" 86 "a086_rsthRamUncorrEcc" 85 "a085_amGduSwitchOffTestByMcu" 84 "a084_adcTriggerCheck" 83 "a083_tdaDclinkcapacitorTempChecker" 82 "a082_adcTriggerTimeChk" 81 "a081_exchFloatingPointException" 80 "a080_pwmTimerSyncCheck" 79 "a079_gduhComErr" 78 "a078_dmDeadlineViolation" 77 "a077_dmDeadlineViolation" 76 "a076_exchGeneralException" 75 "a075_rsthUnusedOtherModuleAlarm" 74 "a074_rsthUnexpectedAlarm" 73 "a073_rsthOtherEdcEcc" 72 "a072_rsthFlashUncorrEccOrOvfl" 71 "a071_rsthInternalHighVolt" 70 "a070_rsthInternalLowVolt" 69 "a069_rsthCoreTempOutOfRangeHwCheck" 68 "a068_rsthCoreRedundancyErr" 67 "a067_tspmPowermoduleTempImplausible" 66 "a066_amVoltQfErr" 65 "a065_amGduJuncTemp" 64 "a064_amBridgeShort" 63 "a063_amIntRegulatorErr" 62 "a062_amPhaseBridgeCheck" 61 "a061_amIntSerialErr" 60 "a060_amGduFail" 59 "a059_amStartupTestFailed" 58 "a058_amIntVgsUndervtgErr" 57 "a057_amGduVds" 56 "a056_amGduConfigCsErrorCheck" 55 "a055_amExtendedGduTest" 54 "a054_adcUnexpectedData" 53 "a053_adcUnexpectedNumOfData" 52 "a052_ermSdcInputBufferOverflow" 51 "a051_ermMessageErr" 50 "a050_erlErr" 49 "a049_epmLgFail" 48 "a048_epmVcpVoltFail" 47 "a047_epmVregVoltFail" 46 "a046_mcusscOscillatorNotReliable" 45 "a045_psumSbcBandgapVoltErr" 44 "a044_sbcmSbcEepromFail" 43 "a043_sbcmWdStateDisabled" 42 "a042_wdhWdTestFail" 41 "a041_imcmCoreConfigurationMismatch" 40 "a040_swrhLimitedResetRetriesExpired" 39 "a039_csohCh2CsErrorErrAtReset" 38 "a038_csohCh1CsErrorErrAtReset" 37 "a037_epmV5P2Fail" 36 "a036_sbcmSbcBistFailed" 35 "a035_sbchChipIdFail" 34 "a034_sbchReadbackRegFail" 33 "a033_icsvcPswVersionMismatch" 32 "a032_eolpEolCheckFailed" 31 "a031_pmsProductionModeFailed" 30 "a030_rsthClockReset" 29 "a029_smuhSmuCoreCntErrorTestFail" 28 "a028_smuhNonInitDataCorruption" 27 "a027_mcusscDmuHfErr" 26 "a026_mrccCsErrorCheckFail" 25 "a025_btarcCorruptionCheck" 24 "a024_srhCsErrorCheckFail" 23 "a023_btarcCorruptionCheck" 22 "a022_swrhSwResetInfoCorruptionCheck" 21 "a021_osehCsErrorCheck" 20 "a020_mcusscEolEcuIdIntegritiyFail" 19 "a019_rsthHwResetInfoCorruptionCheck" 18 "a018_exchCsErrorCheck" 17 "a017_stmdStmPlausibilityCheckErr" 16 "a016_mcufcCsErrorCheckFail" 15 "a015_mcusscCsErrorCheckFail" 14 "a014_mcusscSffMonitoringMia" 13 "a013_mcusscSffMonitoringFailed" 12 "a012_mcusscMbistEccErr" 11 "a011_mcusscMonbistErr" 10 "a010_svcIncompatibleSwVersions" 9 "a009_mcusscLbistPermanentFail" 8 "a008_psdcPlatformShutdown" 7 "a007_tsmcCoreTempDiff" 6 "a006_swrhResetByInvalidErrid" 5 "a005_scpUnknownResetSource" 4 "a004_scpInputMia" 3 "a003_pspInvalidParamset" 2 "a002_adcMuxErr" 1 "a001_adcCalibrationOrInitFail" 0 "ALERT_DO_NOT_USE_ZERO" ;
VAL_ 1427 EPASTP_alertState 1 "SET" 0 "CLEARED" ;
VAL_ 1427 EPASTP_a264_degradedECU 3 "BOTH_ECU_SIDES" 2 "OTHER_ECU_SIDE" 1 "OWN_ECU_SIDE" 0 "NONE" ;
VAL_ 1427 EPASTP_a264_ownSideDegradationRe 92 "DC_LINK_CAPACITOR_HOTSPOTCASEDIFF_TEMPERATURE" 84 "PHASECURRENT_SHUNT_TEMPERATURE_MOMENTARY" 80 "DC_LINK_CAPACITOR_TEMPERATURE" 52 "EMIFILTER_DMC_TEMPERATURE" 48 "EMIFILTER_CMC_TEMPERATURE" 44 "DCLINK_SHUNT_TEMPERATURE" 40 "PHASECURRENT_SHUNT_TEMPERATURE" 36 "POWER_MODULE_TEMPERATURE" 32 "MOTOR_COIL_TEMPERATURE" 28 "BATTERY_FET_JUNCTION_TEMPERATURE" 24 "MAIN_BOARD_TEMPERATURE" 20 "REVERSE_BATTERY_FET_JUNCTION_TEMPERATURE" 12 "RELAY_FET_JUNCTION_TEMPERATURE" 8 "BRIDGE_FET_JUNCTION_TEMPERATURE" 4 "CORE1_DEGRADATION" 0 "NO_DEGRADATION_ON_THIS_ECU_SIDE" ;
VAL_ 1427 EPASTP_a264_otherSideDegradation 92 "DC_LINK_CAPACITOR_HOTSPOTCASEDIFF_TEMPERATURE" 84 "PHASECURRENT_SHUNT_TEMPERATURE_MOMENTARY" 80 "DC_LINK_CAPACITOR_TEMPERATURE" 52 "EMIFILTER_DMC_TEMPERATURE" 48 "EMIFILTER_CMC_TEMPERATURE" 44 "DCLINK_SHUNT_TEMPERATURE" 40 "PHASECURRENT_SHUNT_TEMPERATURE" 36 "POWER_MODULE_TEMPERATURE" 32 "MOTOR_COIL_TEMPERATURE" 28 "BATTERY_FET_JUNCTION_TEMPERATURE" 24 "MAIN_BOARD_TEMPERATURE" 20 "REVERSE_BATTERY_FET_JUNCTION_TEMPERATURE" 12 "RELAY_FET_JUNCTION_TEMPERATURE" 8 "BRIDGE_FET_JUNCTION_TEMPERATURE" 4 "CORE1_DEGRADATION" 0 "NO_DEGRADATION_ON_THIS_ECU_SIDE" ;
VAL_ 1427 EPASTP_a265_degradedECU 3 "BOTH_ECU_SIDES" 2 "OTHER_ECU_SIDE" 1 "OWN_ECU_SIDE" 0 "NONE" ;
VAL_ 1427 EPASTP_a267_velocityEstimatorSta 5 "BACKUP_MOTOR" 4 "BACKUP_WHEELS_B" 3 "BACKUP_WHEELS_A" 2 "WHEELS_REDUCED" 1 "WHEELS_NORMAL" 0 "NOT_INITIALIZED" ;
VAL_ 919 EPASTP_matrixIndex 4 "AlertMatrix4" 3 "AlertMatrix3" 2 "AlertMatrix2" 1 "AlertMatrix1" 0 "AlertMatrix0" ;
VAL_ 909 ESP_absActive 1 "ABS_ACTIVE" 0 "ABS_NOT_ACTIVE" ;
VAL_ 909 ESP_vehicleStandstill 1 "STANDSTILL" 0 "NOT_STANDSTILL" ;
VAL_ 909 ESP_vehicleStandstillQF 2 "STANDSTILL_FAULTED" 1 "STANDSTILL_NORMAL" 0 "STANDSTILL_NOT_INIT" ;
VAL_ 909 ESP_decoupledBrakePressOffsetCom 127 "SNA" ;
VAL_ 909 ESP_privateVehicleSpdQF 2 "Faulty" 1 "Normal" 0 "NotInit_orOff" ;
VAL_ 909 ESP_brakeMasterCylPress 1023 "SNA" ;
VAL_ 909 ESP_brakeMasterCylPressQF 3 "PRESSURE_FAULTED2" 2 "PRESSURE_FAULTED" 1 "PRESSURE_NORMAL" 0 "PRESSURE_NOT_INITIALIZED" ;
VAL_ 325 ESP_espModeActive 3 "ESP_MODE_03" 2 "ESP_MODE_02" 1 "ESP_MODE_01" 0 "ESP_MODE_00_NORMAL" ;
VAL_ 325 ESP_stabilityControlSts2 3 "FAULTED" 2 "ENGAGED" 1 "ON" 0 "INIT" ;
VAL_ 325 ESP_ebdFaultLamp 1 "EBD_FAULT_LAMP_ON" 0 "EBD_FAULT_LAMP_OFF" ;
VAL_ 325 ESP_absFaultLamp 1 "ABS_FAULT_LAMP_ON" 0 "ABS_FAULT_LAMP_OFF" ;
VAL_ 325 ESP_espFaultLamp 1 "ESP_FAULT_LAMP_ON" 0 "ESP_FAULT_LAMP_OFF" ;
VAL_ 325 ESP_espLampFlash 1 "ESP_LAMP_FLASH" 0 "ESP_LAMP_OFF" ;
VAL_ 325 ESP_brakeLamp 1 "LAMP_ON" 0 "LAMP_OFF" ;
VAL_ 325 ESP_absBrakeEvent2 3 "ABS_EVENT_ACTIVE_REAR" 2 "ABS_EVENT_ACTIVE_FRONT" 1 "ABS_EVENT_ACTIVE_FRONT_REAR" 0 "ABS_EVENT_NOT_ACTIVE" ;
VAL_ 325 ESP_longitudinalAccelQF 1 "IN_SPEC" 0 "UNDEFINABLE_ACCURACY" ;
VAL_ 325 ESP_lateralAccelQF 1 "IN_SPEC" 0 "UNDEFINABLE_ACCURACY" ;
VAL_ 325 ESP_yawRateQF 1 "IN_SPEC" 0 "UNDEFINABLE_ACCURACY" ;
VAL_ 325 ESP_steeringAngleQF 1 "IN_SPEC" 0 "UNDEFINABLE_ACCURACY" ;
VAL_ 325 ESP_brakeDiscWipingActive 1 "BDW_ACTIVE" 0 "BDW_INACTIVE" ;
VAL_ 325 ESP_driverBrakeApply 3 "Faulty_SNA" 2 "Driver_applying_brakes" 1 "Not_Applied" 0 "NotInit_orOff" ;
VAL_ 325 ESP_brakeApply 1 "BLS_ACTIVE" 0 "BLS_INACTIVE" ;
VAL_ 325 ESP_aesPrimaryActuatorStatus 3 "AES_FAILURE" 2 "AES_ACTIVE" 1 "AES_AVAILABLE" 0 "AES_NOT_SUPPORTED_OR_NOT_INIT" ;
VAL_ 325 ESP_cdpStatus 3 "CDP_COMMAND_INVALID" 2 "ACTUATING_EPB_CDP" 1 "CDP_IS_AVAILABLE" 0 "CDP_IS_NOT_AVAILABLE" ;
VAL_ 325 ESP_ptcTargetState 3 "SNA" 2 "ON" 1 "BACKUP" 0 "FAULT" ;
VAL_ 325 ESP_btcTargetState 3 "SNA" 2 "ON" 1 "BACKUP" 0 "OFF" ;
VAL_ 325 ESP_decoupledBrakePressEst 255 "SNA" ;
VAL_ 325 ESP_ebrStandstillSkid 1 "STANDSTILL_SKID_DETECTED" 0 "NO_STANDSTILL_SKID" ;
VAL_ 325 ESP_ebrStatus 3 "EBR_COMMAND_INVALID" 2 "ACTUATING_DI_EBR" 1 "EBR_IS_AVAILABLE" 0 "EBR_IS_NOT_AVAILABLE" ;
VAL_ 373 ESP_wheelSpeedFrL 8191 "SNA" ;
VAL_ 373 ESP_wheelSpeedFrR 8191 "SNA" ;
VAL_ 373 ESP_wheelSpeedReL 8191 "SNA" ;
VAL_ 373 ESP_wheelSpeedReR 8191 "SNA" ;
VAL_ 925 IBST_iBoosterStatus 6 "IBOOSTER_ACTUATION" 5 "IBOOSTER_READY" 4 "IBOOSTER_ACTIVE_GOOD_CHECK" 3 "IBOOSTER_DIAGNOSTIC" 2 "IBOOSTER_FAILURE" 1 "IBOOSTER_INIT" 0 "IBOOSTER_OFF" ;
VAL_ 925 IBST_driverBrakeApply 3 "FAULT" 2 "DRIVER_APPLYING_BRAKES" 1 "BRAKES_NOT_APPLIED" 0 "NOT_INIT_OR_OFF" ;
VAL_ 925 IBST_internalState 6 "POST_DRIVE_CHECK" 5 "TRANSITION_TO_IDLE" 4 "DIAGNOSTIC" 3 "EXTERNAL_BRAKE_REQUEST" 2 "LOCAL_BRAKE_REQUEST" 1 "PRE_DRIVE_CHECK" 0 "NO_MODE_ACTIVE" ;
VAL_ 925 IBST_LVPowerModeState 3 "PEAK_POWER_REDUCTION_RESERVED" 2 "PEAK_POWER_REDUCTION_ACTIVE_MAX600W_NOMINAL350W" 1 "PEAK_POWER_REDUCTION_AVAILABLE" 0 "PEAK_POWER_REDUCTION_NOT_SUPPORTED" ;
VAL_ 1973 PM_itpmsDisplaySelector 3 "Mux3" 2 "Mux2" 1 "Mux1" 0 "Mux0" ;
VAL_ 1973 PM_indirectTPMSTellTale 2 "TPMS_TELLTALE_FLASHING" 1 "TPMS_TELLTALE_SOLID" 0 "TPMS_TELLTALE_OFF" ;
VAL_ 1973 PM_indirectTPMSDisplayState 3 "FAULTED" 2 "CALIBRATED" 1 "CALIBRATING" 0 "UNAVAILABLE" ;
VAL_ 1973 PM_indirectTPMSDisplayWarningInd 2 "HARD" 1 "SOFT" 0 "NONE" ;
VAL_ 1973 PM_indirectTPMSDisplayWarni_0001 2 "HARD" 1 "SOFT" 0 "NONE" ;
VAL_ 1973 PM_indirectTPMSDisplayWarni_0002 2 "HARD" 1 "SOFT" 0 "NONE" ;
VAL_ 1973 PM_indirectTPMSDisplayWarni_0003 2 "HARD" 1 "SOFT" 0 "NONE" ;
VAL_ 1973 PM_indirectTPMSRecommendedColdPr 255 "SNA" 254 "OVER_RANGE" ;
VAL_ 1973 PM_indirectTPMSRecommendedC_0001 255 "SNA" 254 "OVER_RANGE" ;
VAL_ 2038 PM_vdcDebugSelector 32 "Mux32" 31 "Mux31" 30 "Mux30" 29 "Mux29" 28 "Mux28" 27 "Mux27" 26 "Mux26" 25 "Mux25" 24 "Mux24" 23 "Mux23" 22 "Mux22" 21 "Mux21" 20 "Mux20" 19 "Mux19" 18 "Mux18" 17 "Mux17" 16 "Mux16" 15 "Mux15" 14 "Mux14" 13 "Mux13" 12 "Mux12" 11 "Mux11" 10 "Mux10" 9 "Mux9" 8 "Mux8" 7 "Mux7" 6 "Mux6" 5 "Mux5" 4 "Mux4" 3 "Mux3" 2 "Mux2" 1 "Mux1" 0 "Mux0" ;
VAL_ 17 RCM_collisionRear 3 "RCM_COLLISION_EVENT_SNA" 1 "RCM_COLLISION_EVENT_ACTIVE" 0 "RCM_COLLISION_EVENT_INACTIVE" ;
VAL_ 17 RCM_collisionRight 3 "RCM_COLLISION_EVENT_SNA" 1 "RCM_COLLISION_EVENT_ACTIVE" 0 "RCM_COLLISION_EVENT_INACTIVE" ;
VAL_ 17 RCM_collisionLeft 3 "RCM_COLLISION_EVENT_SNA" 1 "RCM_COLLISION_EVENT_ACTIVE" 0 "RCM_COLLISION_EVENT_INACTIVE" ;
VAL_ 17 RCM_collisionFront 3 "RCM_COLLISION_EVENT_SNA" 1 "RCM_COLLISION_EVENT_ACTIVE" 0 "RCM_COLLISION_EVENT_INACTIVE" ;
VAL_ 17 RCM_collisionRollover 3 "RCM_COLLISION_EVENT_SNA" 1 "RCM_COLLISION_EVENT_ACTIVE" 0 "RCM_COLLISION_EVENT_INACTIVE" ;
VAL_ 17 RCM_collisionPedPro 3 "RCM_COLLISION_EVENT_SNA" 1 "RCM_COLLISION_EVENT_ACTIVE" 0 "RCM_COLLISION_EVENT_INACTIVE" ;
VAL_ 17 RCM_collisionSeverity 3 "RCM_COLLISION_SEVERITY_PEDPRO_EVENT" 2 "RCM_COLLISION_SEVERITY_SECOND_STAGE" 1 "RCM_COLLISION_SEVERITY_FIRST_STAGE" 0 "RCM_COLLISION_SEVERITY_PRETENSIONER" ;
VAL_ 289 RCM_nearDeployRear 3 "RCM_NEAR_DEPLOY_EVENT_SNA" 1 "RCM_NEAR_DEPLOY_EVENT_ACTIVE" 0 "RCM_NEAR_DEPLOY_EVENT_INACTIVE" ;
VAL_ 289 RCM_nearDeployRight 3 "RCM_NEAR_DEPLOY_EVENT_SNA" 1 "RCM_NEAR_DEPLOY_EVENT_ACTIVE" 0 "RCM_NEAR_DEPLOY_EVENT_INACTIVE" ;
VAL_ 289 RCM_nearDeployLeft 3 "RCM_NEAR_DEPLOY_EVENT_SNA" 1 "RCM_NEAR_DEPLOY_EVENT_ACTIVE" 0 "RCM_NEAR_DEPLOY_EVENT_INACTIVE" ;
VAL_ 289 RCM_nearDeployFront 3 "RCM_NEAR_DEPLOY_EVENT_SNA" 1 "RCM_NEAR_DEPLOY_EVENT_ACTIVE" 0 "RCM_NEAR_DEPLOY_EVENT_INACTIVE" ;
VAL_ 289 RCM_nearDeployRollover 3 "RCM_NEAR_DEPLOY_EVENT_SNA" 1 "RCM_NEAR_DEPLOY_EVENT_ACTIVE" 0 "RCM_NEAR_DEPLOY_EVENT_INACTIVE" ;
VAL_ 289 RCM_crashAlgoWakeup 3 "RCM_CRASH_ALGO_WAKEUP_EVENT_SNA" 1 "RCM_CRASH_ALGO_WAKEUP_EVENT_ACTIVE" 0 "RCM_CRASH_ALGO_WAKEUP_EVENT_INACTIVE" ;
VAL_ 1618 VCBATT0_infoIndex 255 "END" 41 "SUBCOMPONENT14" 40 "SUBCOMPONENT13" 39 "SUBCOMPONENT12" 38 "SUBCOMPONENT11" 37 "SUBCOMPONENT10" 36 "SUBCOMPONENT9" 35 "SUBCOMPONENT8" 34 "SUBCOMPONENT7" 33 "SUBCOMPONENT6" 32 "SUBCOMPONENT5" 31 "SUBCOMPONENT4" 24 "SUBCOMPONENT3" 23 "SUBCOMPONENT2" 20 "UDS_PROTOCOL_BOOTCRC" 19 "VERSION_DEPRECATED" 18 "BOOTLOADER_GITHASH" 17 "APP_GITHASH" 16 "SUBCOMPONENT1" 15 "BOOTLOADER_CRC" 14 "BOOTLOADER_SVN" 13 "APP_CRC" 11 "PCBAID_ASSYID_USAGEID" 10 "BUILD_HWID_COMPONENTID" 9 "DEPRECATED_9" 8 "DEPRECATED_8" 7 "DEPRECATED_7" 6 "DEPRECATED_6" 5 "DEPRECATED_5" 4 "DEPRECATED_4" 3 "DEPRECATED_3" 2 "DEPRECATED_2" 1 "DEPRECATED_1" 0 "DEPRECATED_0" ;
VAL_ 1618 VCBATT0_infoBuildType 4 "INFO_MFG_BUILD" 3 "INFO_TRACEABLE_CI_BUILD" 2 "INFO_LOCAL_BUILD" 1 "INFO_PLATFORM_BUILD" 0 "INFO_UNKNOWN_BUILD" ;
VAL_ 1618 VCBATT0_infoAssemblyId 255 "ASSEMBLY_SNA" 1 "ASSEMBLY1" ;
VAL_ 1994 VCCC_infoIndex 255 "END" 41 "SUBCOMPONENT14" 40 "SUBCOMPONENT13" 39 "SUBCOMPONENT12" 38 "SUBCOMPONENT11" 37 "SUBCOMPONENT10" 36 "SUBCOMPONENT9" 35 "SUBCOMPONENT8" 34 "SUBCOMPONENT7" 33 "SUBCOMPONENT6" 32 "SUBCOMPONENT5" 31 "SUBCOMPONENT4" 24 "SUBCOMPONENT3" 23 "SUBCOMPONENT2" 20 "UDS_PROTOCOL_BOOTCRC" 19 "VERSION_DEPRECATED" 18 "BOOTLOADER_GITHASH" 17 "APP_GITHASH" 16 "SUBCOMPONENT1" 15 "BOOTLOADER_CRC" 14 "BOOTLOADER_SVN" 13 "APP_CRC" 11 "PCBAID_ASSYID_USAGEID" 10 "BUILD_HWID_COMPONENTID" 9 "DEPRECATED_9" 8 "DEPRECATED_8" 7 "DEPRECATED_7" 6 "DEPRECATED_6" 5 "DEPRECATED_5" 4 "DEPRECATED_4" 3 "DEPRECATED_3" 2 "DEPRECATED_2" 1 "DEPRECATED_1" 0 "DEPRECATED_0" ;
VAL_ 1994 VCCC_infoBuildType 4 "INFO_MFG_BUILD" 3 "INFO_TRACEABLE_CI_BUILD" 2 "INFO_LOCAL_BUILD" 1 "INFO_PLATFORM_BUILD" 0 "INFO_UNKNOWN_BUILD" ;
VAL_ 1994 VCCC_infoAssemblyId 255 "ASSEMBLY_SNA" 1 "ASSEMBLY1" ;
VAL_ 260 VCFRONT_vehicleSM 18 "VEHICLE_STATUS_SNA" 17 "VEHICLE_STATUS_RESET" 16 "VEHICLE_STATUS_TURN_ON_RAILS" 15 "VEHICLE_STATUS_OTA" 14 "VEHICLE_STATUS_CRASH" 13 "VEHICLE_STATUS_DRIVE" 12 "VEHICLE_STATUS_CONDITIONING" 11 "VEHICLE_STATUS_ACCESSORY_PLUS" 10 "VEHICLE_STATUS_ACCESSORY" 9 "VEHICLE_STATUS_HV_UP_STANDBY" 8 "VEHICLE_STATUS_LV_AWAKE" 7 "VEHICLE_STATUS_LV_SHUTDOWN" 6 "VEHICLE_STATUS_SLEEP_STANDBY" 5 "VEHICLE_STATUS_SLEEP_SHUTDOWN" 4 "VEHICLE_STATUS_SYSTEM_CHECKS" 3 "VEHICLE_STATUS_BATTERY_POST_WAKE" 2 "VEHICLE_STATUS_SILENT_WAKE" 1 "VEHICLE_STATUS_LOW_POWER_STANDBY" 0 "VEHICLE_STATUS_INIT" ;
VAL_ 260 VCFRONT_battSM 10 "BATTERY_SM_STATE_EXTERNAL_LV_BUS_CONTROL" 9 "BATTERY_SM_STATE_RECOVERY" 8 "BATTERY_SM_STATE_FAULT" 7 "BATTERY_SM_STATE_SHORTED_CELL_TEST" 6 "BATTERY_SM_STATE_DISCONNECTED_BATTERY_TEST" 5 "BATTERY_SM_STATE_OTA_STANDBY" 4 "BATTERY_SM_STATE_RESISTANCE_ESTIMATION" 3 "BATTERY_SM_STATE_STANDBY" 2 "BATTERY_SM_STATE_DISCHARGE" 1 "BATTERY_SM_STATE_CHARGE" 0 "BATTERY_SM_STATE_INIT" ;
VAL_ 258 VCLEFT_doorClosureStatusFront 8 "CLOSURE_STATUS_FAULT" 2 "CLOSURE_STATUS_CLOSED" 1 "CLOSURE_STATUS_OPEN" 0 "CLOSURE_STATUS_SNA" ;
VAL_ 258 VCLEFT_doorClosureStatusRear 8 "CLOSURE_STATUS_FAULT" 2 "CLOSURE_STATUS_CLOSED" 1 "CLOSURE_STATUS_OPEN" 0 "CLOSURE_STATUS_SNA" ;
VAL_ 258 VCLEFT_frontLatchStatus 8 "LATCH_FAULT" 7 "LATCH_DEFAULT" 6 "LATCH_TIMEOUT" 5 "LATCH_AJAR" 4 "LATCH_OPENING" 3 "LATCH_CLOSING" 2 "LATCH_CLOSED" 1 "LATCH_OPENED" 0 "LATCH_SNA" ;
VAL_ 258 VCLEFT_rearLatchStatus 8 "LATCH_FAULT" 7 "LATCH_DEFAULT" 6 "LATCH_TIMEOUT" 5 "LATCH_AJAR" 4 "LATCH_OPENING" 3 "LATCH_CLOSING" 2 "LATCH_CLOSED" 1 "LATCH_OPENED" 0 "LATCH_SNA" ;
VAL_ 258 VCLEFT_lastDoorReqSourceFront 4 "DOOR_REQUEST_SOURCE_ECU" 3 "DOOR_REQUEST_SOURCE_VCSEC" 2 "DOOR_REQUEST_SOURCE_EXTERIOR_HANDLE" 1 "DOOR_REQUEST_SOURCE_INTERIOR_BUTTON" 0 "DOOR_REQUEST_SOURCE_UNKNOWN" ;
VAL_ 258 VCLEFT_lastDoorReqSourceRear 4 "DOOR_REQUEST_SOURCE_ECU" 3 "DOOR_REQUEST_SOURCE_VCSEC" 2 "DOOR_REQUEST_SOURCE_EXTERIOR_HANDLE" 1 "DOOR_REQUEST_SOURCE_INTERIOR_BUTTON" 0 "DOOR_REQUEST_SOURCE_UNKNOWN" ;
VAL_ 258 VCLEFT_mirrorState 5 "MIRROR_STATE_CALIBRATION" 4 "MIRROR_STATE_RECALL" 3 "MIRROR_STATE_FOLD_UNFOLD" 2 "MIRROR_STATE_TILT_Y" 1 "MIRROR_STATE_TILT_X" 0 "MIRROR_STATE_IDLE" ;
VAL_ 258 VCLEFT_mirrorFoldState 4 "MIRROR_FOLD_STATE_UNFOLDING" 3 "MIRROR_FOLD_STATE_FOLDING" 2 "MIRROR_FOLD_STATE_UNFOLDED" 1 "MIRROR_FOLD_STATE_FOLDED" 0 "MIRROR_FOLD_STATE_UNKNOWN" ;
VAL_ 258 VCLEFT_mirrorRecallState 5 "MIRROR_RECALL_STATE_RECALLING_STOPPED" 4 "MIRROR_RECALL_STATE_RECALLING_FAILED" 3 "MIRROR_RECALL_STATE_RECALLING_COMPLETE" 2 "MIRROR_RECALL_STATE_RECALLING_AXIS_2" 1 "MIRROR_RECALL_STATE_RECALLING_AXIS_1" 0 "MIRROR_RECALL_STATE_INIT" ;
VAL_ 258 VCLEFT_mirrorHeatState 4 "HEATER_STATE_FAULT" 3 "HEATER_STATE_OFF_UNAVAILABLE" 2 "HEATER_STATE_OFF" 1 "HEATER_STATE_ON" 0 "HEATER_STATE_SNA" ;
VAL_ 546 VCLEFT_cdpRequestState 1 "EPB_CDP_REQUEST_VALID" 0 "EPB_CDP_REQUEST_INVALID" ;
VAL_ 546 VCLEFT_epbmSystemStatusQF 1 "EPBM_SYSTEM_STATUS_INVALID" 0 "EPBM_SYSTEM_STATUS_VALID" ;
VAL_ 546 VCLEFT_epbmUnitStatus 23 "EPB_STATUS_COUNT" 22 "EPB_STATUS_AUTONOMY_OPEN" 21 "EPB_STATUS_FREE_ROLL_MODE" 20 "EPB_STATUS_DYNAMIC_PARKING" 19 "EPB_STATUS_EXTERNAL_PARKING" 18 "EPB_STATUS_RELEASING_FOR_EXTERNAL_PARK" 17 "EPB_STATUS_EXTERNAL_DYNAMIC" 16 "EPB_STATUS_SUMMON_PARKING" 15 "EPB_STATUS_SUMMON_RELEASING" 14 "EPB_STATUS_SUMMON" 13 "EPB_STATUS_WINCHMODE_PENDING" 12 "EPB_STATUS_PARK_PENDING" 11 "EPB_STATUS_SERVICE_RELEASING" 10 "EPB_STATUS_RELEASING" 9 "EPB_STATUS_DYNAMIC_APPLYING" 8 "EPB_STATUS_PARKING" 7 "EPB_STATUS_WINCHMODE_RELEASING" 6 "EPB_STATUS_WINCHMODE" 5 "EPB_STATUS_SERVICE" 4 "EPB_STATUS_START" 3 "EPB_STATUS_PARK" 2 "EPB_STATUS_DYNAMIC" 1 "EPB_STATUS_OPEN" 0 "EPB_STATUS_UNKNOWN" ;
VAL_ 546 VCLEFT_epbmCdpState 2 "EPB_CDP_STATE_FAULT" 1 "EPB_CDP_STATE_VALID" 0 "EPB_CDP_STATE_UNKNOWN" ;
VAL_ 778 VCLEFT_frontOccupancyStatus 7 "SEAT_OCCUPANCY_SNA" 3 "SEAT_NOT_CONFIGURED" 2 "SEAT_OCCUPANCY_FAULTED" 1 "SEAT_OCCUPIED" 0 "SEAT_UNOCCUPIED" ;
VAL_ 778 VCLEFT_frontBuckleStatus 3 "SEAT_BELT_BUCKLE_NOT_CONFIGURED" 2 "SEAT_BELT_BUCKLE_STATUS_FAULTED" 1 "SEAT_BELT_BUCKLE_STATUS_LATCHED" 0 "SEAT_BELT_BUCKLE_STATUS_UNLATCHED" ;
VAL_ 778 VCLEFT_rearLeftOccupancyStatus 3 "SEAT_NOT_CONFIGURED" 2 "SEAT_OCCUPANCY_FAULTED" 1 "SEAT_OCCUPIED" 0 "SEAT_UNOCCUPIED" ;
VAL_ 778 VCLEFT_rearCenterOccupancyStatus 3 "SEAT_NOT_CONFIGURED" 2 "SEAT_OCCUPANCY_FAULTED" 1 "SEAT_OCCUPIED" 0 "SEAT_UNOCCUPIED" ;
VAL_ 778 VCLEFT_rearRightOccupancyStatus 3 "SEAT_NOT_CONFIGURED" 2 "SEAT_OCCUPANCY_FAULTED" 1 "SEAT_OCCUPIED" 0 "SEAT_UNOCCUPIED" ;
VAL_ 778 VCLEFT_rearLeftBuckleStatus 3 "SEAT_BELT_BUCKLE_NOT_CONFIGURED" 2 "SEAT_BELT_BUCKLE_STATUS_FAULTED" 1 "SEAT_BELT_BUCKLE_STATUS_LATCHED" 0 "SEAT_BELT_BUCKLE_STATUS_UNLATCHED" ;
VAL_ 778 VCLEFT_rearCenterBuckleStatus 3 "SEAT_BELT_BUCKLE_NOT_CONFIGURED" 2 "SEAT_BELT_BUCKLE_STATUS_FAULTED" 1 "SEAT_BELT_BUCKLE_STATUS_LATCHED" 0 "SEAT_BELT_BUCKLE_STATUS_UNLATCHED" ;
VAL_ 778 VCLEFT_seatTrackPosition 7 "SEAT_TRACK_POSITION_SNA" 3 "SEAT_TRACK_POSITION_FAULTED" 2 "SEAT_TRACK_POSITION_NOT_CONFIGURED" 1 "SEAT_TRACK_POSITION_REARWARD" 0 "SEAT_TRACK_POSITION_FORWARD" ;
VAL_ 778 VCLEFT_3RowLeftABStatus 2 "AIRBAG_STATE_SNA" 1 "AIRBAG_SUPPRESS" 0 "AIRBAG_ALLOW" ;
VAL_ 778 VCLEFT_3RowLeftBuckleStatus 3 "SEAT_BELT_BUCKLE_NOT_CONFIGURED" 2 "SEAT_BELT_BUCKLE_STATUS_FAULTED" 1 "SEAT_BELT_BUCKLE_STATUS_LATCHED" 0 "SEAT_BELT_BUCKLE_STATUS_UNLATCHED" ;
VAL_ 1124 VCRIGHT_AP_hvacState1HzIndex 1 "END" 0 "0" ;
VAL_ 1124 VCRIGHT_AP_tempCameraModele_0001 255 "SNA" ;
VAL_ 1124 VCRIGHT_AP_tempCameraModeledWind 255 "SNA" ;
VAL_ 1124 VCRIGHT_AP_cameraModeledWin_0001 127 "SNA" ;
VAL_ 1124 VCRIGHT_AP_cameraModeledWindshie 127 "SNA" ;
VAL_ 1124 VCRIGHT_AP_cameraModeledPocketWa 1023 "SNA" ;
VAL_ 1124 VCRIGHT_AP_humidityModelInitStat 21 "INIT_STATUS_LIMP_FORWARD_CALC_AMBIENT_PROBE_AND_THS" 20 "INIT_STATUS_LIMP_FORWARD_CALC_WEATHER_PROBE_AND_THS" 19 "INIT_STATUS_LIMP_FORWARD_CALC_PROBE_AND_THS" 18 "INIT_STATUS_LIMP_FORWARD_CALC_AMBIENT_AND_THS" 17 "INIT_STATUS_LIMP_FORWARD_CALC_WEATHER_AND_THS" 16 "INIT_STATUS_LIMP_FORWARD_CALC_THS_ONLY" 15 "INIT_STATUS_LIMP_FORWARD_CALC_AMBIENT_AND_PROBE" 14 "INIT_STATUS_LIMP_FORWARD_CALC_WEATHER_AND_PROBE" 13 "INIT_STATUS_LIMP_FORWARD_CALC_PROBE_ONLY" 12 "INIT_STATUS_LIMP_FORWARD_CALC_AMBIENT_ONLY" 11 "INIT_STATUS_LIMP_FORWARD_CALC_WEATHER_ONLY" 10 "INIT_STATUS_LIMP_FROM_SENSORS_PROBE_ONLY" 9 "INIT_STATUS_FROM_FORWARD_CALC" 8 "INIT_STATUS_FROM_SENSORS" 7 "INIT_STATUS_FAULTED_MULTI_CYCLE_SENSOR_INVALID" 6 "INIT_STATUS_FAULTED_ALL_INVALID" 5 "INIT_STATUS_FAULTED_FORWARD_CALC_WEATHER_AND_AMBIENT_INVALID" 4 "INIT_STATUS_FAULTED_FROM_SENSORS_THS_INVALID" 3 "INIT_STATUS_WAITING_FOR_SENSORS_API" 2 "INIT_STATUS_WAITING_FOR_CABIN_MODEL_INIT" 1 "INIT_STATUS_WAITING_FOR_GTW" 0 "INIT_STATUS_UNKNOWN" ;
VAL_ 1124 VCRIGHT_AP_humidityModelStatus 19 "STATUS_RUNNING_FAULTED_WEATHER_AND_AMBIENT_INVALID" 18 "STATUS_RUNNING_LIMP_THS_DIRECTLY_NO_PROBE_LIMIT" 17 "STATUS_RUNNING_LIMP_THS_DIRECTLY_WITH_PROBE_LIMIT" 16 "STATUS_RUNNING_LIMP_THS_ONLY_SUBSTITUTED" 15 "STATUS_RUNNING_LIMP_AMBIENT_AND_PROBE_SUBSTITUTED_NO_THS_FEEDBACK" 14 "STATUS_RUNNING_LIMP_WEATHER_AND_PROBE_SUBSTITUTED_NO_THS_FEEDBACK" 13 "STATUS_RUNNING_LIMP_AMBIENT_AND_PROBE_SUBSTITUTED_WITH_THS_FEEDBACK" 12 "STATUS_RUNNING_LIMP_WEATHER_AND_PROBE_SUBSTITUTED_WITH_THS_FEEDBACK" 11 "STATUS_RUNNING_LIMP_EVAP_SUBSTITUTED_NO_THS_FEEDBACK" 10 "STATUS_RUNNING_LIMP_PROBE_SUBSTITUTED_NO_THS_FEEDBACK" 9 "STATUS_RUNNING_LIMP_AMBIENT_SUBSTITUTED_NO_THS_FEEDBACK" 8 "STATUS_RUNNING_LIMP_WEATHER_SUBSTITUTED_NO_THS_FEEDBACK" 7 "STATUS_RUNNING_LIMP_EVAP_SUBSTITUTED_WITH_THS_FEEDBACK" 6 "STATUS_RUNNING_LIMP_PROBE_SUBSTITUTED_WITH_THS_FEEDBACK" 5 "STATUS_RUNNING_LIMP_AMBIENT_SUBSTITUTED_WITH_THS_FEEDBACK" 4 "STATUS_RUNNING_LIMP_WEATHER_SUBSTITUTED_WITH_THS_FEEDBACK" 3 "STATUS_RUNNING_RECOVERED_CATCHUP" 2 "STATUS_RUNNING_PAUSED_AWAITING_RECOVERY" 1 "STATUS_RUNNING_NOMINAL" 0 "STATUS_UNKNOWN" ;
VAL_ 259 VCRIGHT_doorClosureStatusFront 8 "CLOSURE_STATUS_FAULT" 2 "CLOSURE_STATUS_CLOSED" 1 "CLOSURE_STATUS_OPEN" 0 "CLOSURE_STATUS_SNA" ;
VAL_ 259 VCRIGHT_doorClosureStatusRear 8 "CLOSURE_STATUS_FAULT" 2 "CLOSURE_STATUS_CLOSED" 1 "CLOSURE_STATUS_OPEN" 0 "CLOSURE_STATUS_SNA" ;
VAL_ 259 VCRIGHT_frontLatchStatus 8 "LATCH_FAULT" 7 "LATCH_DEFAULT" 6 "LATCH_TIMEOUT" 5 "LATCH_AJAR" 4 "LATCH_OPENING" 3 "LATCH_CLOSING" 2 "LATCH_CLOSED" 1 "LATCH_OPENED" 0 "LATCH_SNA" ;
VAL_ 259 VCRIGHT_rearLatchStatus 8 "LATCH_FAULT" 7 "LATCH_DEFAULT" 6 "LATCH_TIMEOUT" 5 "LATCH_AJAR" 4 "LATCH_OPENING" 3 "LATCH_CLOSING" 2 "LATCH_CLOSED" 1 "LATCH_OPENED" 0 "LATCH_SNA" ;
VAL_ 259 VCRIGHT_lastDoorReqSourceFront 4 "DOOR_REQUEST_SOURCE_ECU" 3 "DOOR_REQUEST_SOURCE_VCSEC" 2 "DOOR_REQUEST_SOURCE_EXTERIOR_HANDLE" 1 "DOOR_REQUEST_SOURCE_INTERIOR_BUTTON" 0 "DOOR_REQUEST_SOURCE_UNKNOWN" ;
VAL_ 259 VCRIGHT_lastDoorReqSourceRear 4 "DOOR_REQUEST_SOURCE_ECU" 3 "DOOR_REQUEST_SOURCE_VCSEC" 2 "DOOR_REQUEST_SOURCE_EXTERIOR_HANDLE" 1 "DOOR_REQUEST_SOURCE_INTERIOR_BUTTON" 0 "DOOR_REQUEST_SOURCE_UNKNOWN" ;
VAL_ 259 VCRIGHT_mirrorState 5 "MIRROR_STATE_CALIBRATION" 4 "MIRROR_STATE_RECALL" 3 "MIRROR_STATE_FOLD_UNFOLD" 2 "MIRROR_STATE_TILT_Y" 1 "MIRROR_STATE_TILT_X" 0 "MIRROR_STATE_IDLE" ;
VAL_ 259 VCRIGHT_mirrorFoldState 4 "MIRROR_FOLD_STATE_UNFOLDING" 3 "MIRROR_FOLD_STATE_FOLDING" 2 "MIRROR_FOLD_STATE_UNFOLDED" 1 "MIRROR_FOLD_STATE_FOLDED" 0 "MIRROR_FOLD_STATE_UNKNOWN" ;
VAL_ 259 VCRIGHT_trunkLatchStatus 8 "LATCH_FAULT" 7 "LATCH_DEFAULT" 6 "LATCH_TIMEOUT" 5 "LATCH_AJAR" 4 "LATCH_OPENING" 3 "LATCH_CLOSING" 2 "LATCH_CLOSED" 1 "LATCH_OPENED" 0 "LATCH_SNA" ;
VAL_ 259 VCRIGHT_mirrorRecallState 5 "MIRROR_RECALL_STATE_RECALLING_STOPPED" 4 "MIRROR_RECALL_STATE_RECALLING_FAILED" 3 "MIRROR_RECALL_STATE_RECALLING_COMPLETE" 2 "MIRROR_RECALL_STATE_RECALLING_AXIS_2" 1 "MIRROR_RECALL_STATE_RECALLING_AXIS_1" 0 "MIRROR_RECALL_STATE_INIT" ;
VAL_ 611 VCRIGHT_cdpRequestState 1 "EPB_CDP_REQUEST_VALID" 0 "EPB_CDP_REQUEST_INVALID" ;
VAL_ 611 VCRIGHT_epbmSystemStatusQF 1 "EPBM_SYSTEM_STATUS_INVALID" 0 "EPBM_SYSTEM_STATUS_VALID" ;
VAL_ 611 VCRIGHT_epbmUnitStatus 23 "EPB_STATUS_COUNT" 22 "EPB_STATUS_AUTONOMY_OPEN" 21 "EPB_STATUS_FREE_ROLL_MODE" 20 "EPB_STATUS_DYNAMIC_PARKING" 19 "EPB_STATUS_EXTERNAL_PARKING" 18 "EPB_STATUS_RELEASING_FOR_EXTERNAL_PARK" 17 "EPB_STATUS_EXTERNAL_DYNAMIC" 16 "EPB_STATUS_SUMMON_PARKING" 15 "EPB_STATUS_SUMMON_RELEASING" 14 "EPB_STATUS_SUMMON" 13 "EPB_STATUS_WINCHMODE_PENDING" 12 "EPB_STATUS_PARK_PENDING" 11 "EPB_STATUS_SERVICE_RELEASING" 10 "EPB_STATUS_RELEASING" 9 "EPB_STATUS_DYNAMIC_APPLYING" 8 "EPB_STATUS_PARKING" 7 "EPB_STATUS_WINCHMODE_RELEASING" 6 "EPB_STATUS_WINCHMODE" 5 "EPB_STATUS_SERVICE" 4 "EPB_STATUS_START" 3 "EPB_STATUS_PARK" 2 "EPB_STATUS_DYNAMIC" 1 "EPB_STATUS_OPEN" 0 "EPB_STATUS_UNKNOWN" ;
VAL_ 611 VCRIGHT_epbmCdpState 2 "EPB_CDP_STATE_FAULT" 1 "EPB_CDP_STATE_VALID" 0 "EPB_CDP_STATE_UNKNOWN" ;
VAL_ 794 VCRIGHT_frontOccupancyStatus 7 "SEAT_OCCUPANCY_SNA" 3 "SEAT_NOT_CONFIGURED" 2 "SEAT_OCCUPANCY_FAULTED" 1 "SEAT_OCCUPIED" 0 "SEAT_UNOCCUPIED" ;
VAL_ 794 VCRIGHT_frontBuckleStatus 3 "SEAT_BELT_BUCKLE_NOT_CONFIGURED" 2 "SEAT_BELT_BUCKLE_STATUS_FAULTED" 1 "SEAT_BELT_BUCKLE_STATUS_LATCHED" 0 "SEAT_BELT_BUCKLE_STATUS_UNLATCHED" ;
VAL_ 794 VCRIGHT_rearCenterBuckleStatus 3 "SEAT_BELT_BUCKLE_NOT_CONFIGURED" 2 "SEAT_BELT_BUCKLE_STATUS_FAULTED" 1 "SEAT_BELT_BUCKLE_STATUS_LATCHED" 0 "SEAT_BELT_BUCKLE_STATUS_UNLATCHED" ;
VAL_ 794 VCRIGHT_rearRightBuckleStatus 3 "SEAT_BELT_BUCKLE_NOT_CONFIGURED" 2 "SEAT_BELT_BUCKLE_STATUS_FAULTED" 1 "SEAT_BELT_BUCKLE_STATUS_LATCHED" 0 "SEAT_BELT_BUCKLE_STATUS_UNLATCHED" ;
VAL_ 794 VCRIGHT_rearRightOccupancyStatus 3 "SEAT_NOT_CONFIGURED" 2 "SEAT_OCCUPANCY_FAULTED" 1 "SEAT_OCCUPIED" 0 "SEAT_UNOCCUPIED" ;
VAL_ 794 VCRIGHT_3RowLeftBuckleStatus 3 "SEAT_BELT_BUCKLE_NOT_CONFIGURED" 2 "SEAT_BELT_BUCKLE_STATUS_FAULTED" 1 "SEAT_BELT_BUCKLE_STATUS_LATCHED" 0 "SEAT_BELT_BUCKLE_STATUS_UNLATCHED" ;
VAL_ 794 VCRIGHT_3RowRightBuckleStatus 3 "SEAT_BELT_BUCKLE_NOT_CONFIGURED" 2 "SEAT_BELT_BUCKLE_STATUS_FAULTED" 1 "SEAT_BELT_BUCKLE_STATUS_LATCHED" 0 "SEAT_BELT_BUCKLE_STATUS_UNLATCHED" ;
VAL_ 794 VCRIGHT_3RowLeftOccupancyStatus 3 "SEAT_NOT_CONFIGURED" 2 "SEAT_OCCUPANCY_FAULTED" 1 "SEAT_OCCUPIED" 0 "SEAT_UNOCCUPIED" ;
VAL_ 794 VCRIGHT_3RowRightOccupancyStatus 3 "SEAT_NOT_CONFIGURED" 2 "SEAT_OCCUPANCY_FAULTED" 1 "SEAT_OCCUPIED" 0 "SEAT_UNOCCUPIED" ;
VAL_ 794 VCRIGHT_seatTrackPosition 7 "SEAT_TRACK_POSITION_SNA" 3 "SEAT_TRACK_POSITION_FAULTED" 2 "SEAT_TRACK_POSITION_NOT_CONFIGURED" 1 "SEAT_TRACK_POSITION_REARWARD" 0 "SEAT_TRACK_POSITION_FORWARD" ;
VAL_ 794 VCRIGHT_occupantClassification 7 "SEAT_OCCUPANT_CLASSIFICATON_SNA" 6 "SEAT_OCCUPANT_CLASSIFICATON_OUT_OF_POSITION" 5 "SEAT_OCCUPANT_CLASSIFICATON_NOT_CONFIGURED" 4 "SEAT_OCCUPANT_CLASSIFICATON_INIT" 3 "SEAT_OCCUPANT_CLASSIFICATON_LARGE" 2 "SEAT_OCCUPANT_CLASSIFICATON_SMALL" 1 "SEAT_OCCUPANT_CLASSIFICATON_INHIBIT" 0 "SEAT_OCCUPANT_CLASSIFICATON_EMPTY" ;
VAL_ 794 VCRIGHT_occupantClassificationQF 1 "SEAT_OCCUPANT_CLASSIFICATON_NOT_FAULTED" 0 "SEAT_OCCUPANT_CLASSIFICATON_FAULTED" ;
VAL_ 794 VCRIGHT_classificationEnabled 1 "VCRIGHT_CLASSIFICATION_SOURCE" 0 "OCS1P_CLASSIFICATION_SOURCE" ;
VAL_ 794 VCRIGHT_classificationEnabledQF 1 "CLASSIFICATION_ENABLED_NOT_FAULTED" 0 "CLASSIFICATION_ENABLED_FAULTED" ;
VAL_ 794 VCRIGHT_3RowRightABStatus 2 "AIRBAG_STATE_SNA" 1 "AIRBAG_SUPPRESS" 0 "AIRBAG_ALLOW" ;
